VERSION "12.2.7"

NS_ :

BS_:

BU_: BMS_Tester EDS_F EDS_R EPS2 FCAM_PT GS IDB_PT POD RCU_PT VCU_PT XGW_PT

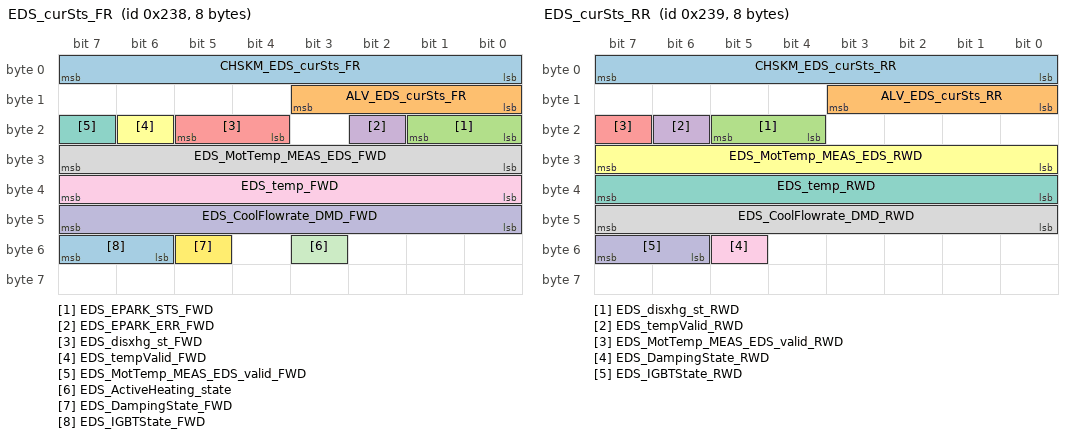
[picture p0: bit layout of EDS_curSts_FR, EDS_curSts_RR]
BO_ 568 EDS_curSts_FR: 8 EDS_F
 SG_ CHSKM_EDS_curSts_FR : 7|8@0+ (1,0) [0|255] ""  IDB_PT,VCU_PT
 SG_ ALV_EDS_curSts_FR : 11|4@0+ (1,0) [0|14] ""  IDB_PT,VCU_PT
 SG_ EDS_EPARK_STS_FWD : 17|2@0+ (1,0) [0|3] ""  VCU_PT
 SG_ EDS_EPARK_ERR_FWD : 18|1@0+ (1,0) [0|1] ""  VCU_PT
 SG_ EDS_disxhg_st_FWD : 21|2@0+ (1,0) [0|3] ""  VCU_PT
 SG_ EDS_tempValid_FWD : 22|1@0+ (1,0) [0|1] ""  VCU_PT
 SG_ EDS_MotTemp_MEAS_EDS_valid_FWD : 23|1@0+ (1,0) [0|1] ""  VCU_PT
 SG_ EDS_MotTemp_MEAS_EDS_FWD : 31|8@0+ (1,-40) [-40|215] "°C"  VCU_PT
 SG_ EDS_temp_FWD : 39|8@0+ (1,-40) [-40|215] "°C"  VCU_PT
 SG_ EDS_CoolFlowrate_DMD_FWD : 47|8@0+ (0.1,0) [0|25.4] "l/min"  IDB_PT,VCU_PT
 SG_ EDS_ActiveHeating_state : 51|1@0+ (1,0) [0|1] ""  VCU_PT
 SG_ EDS_DampingState_FWD : 53|1@0+ (1,0) [0|1] ""  IDB_PT,VCU_PT
 SG_ EDS_IGBTState_FWD : 55|2@0+ (1,0) [0|3] ""  IDB_PT,VCU_PT

BO_ 569 EDS_curSts_RR: 8 EDS_R
 SG_ CHSKM_EDS_curSts_RR : 7|8@0+ (1,0) [0|255] ""  IDB_PT,VCU_PT
 SG_ ALV_EDS_curSts_RR : 11|4@0+ (1,0) [0|14] ""  IDB_PT,VCU_PT
 SG_ EDS_disxhg_st_RWD : 21|2@0+ (1,0) [0|3] ""  VCU_PT
 SG_ EDS_tempValid_RWD : 22|1@0+ (1,0) [0|1] ""  VCU_PT
 SG_ EDS_MotTemp_MEAS_EDS_valid_RWD : 23|1@0+ (1,0) [0|1] ""  VCU_PT
 SG_ EDS_MotTemp_MEAS_EDS_RWD : 31|8@0+ (1,-40) [-40|215] "°C"  VCU_PT
 SG_ EDS_temp_RWD : 39|8@0+ (1,-40) [-40|215] "°C"  VCU_PT
 SG_ EDS_CoolFlowrate_DMD_RWD : 47|8@0+ (0.1,0) [0|25.4] "l/min"  IDB_PT,VCU_PT
 SG_ EDS_DampingState_RWD : 53|1@0+ (1,0) [0|1] ""  IDB_PT,VCU_PT
 SG_ EDS_IGBTState_RWD : 55|2@0+ (1,0) [0|3] ""  IDB_PT,VCU_PT

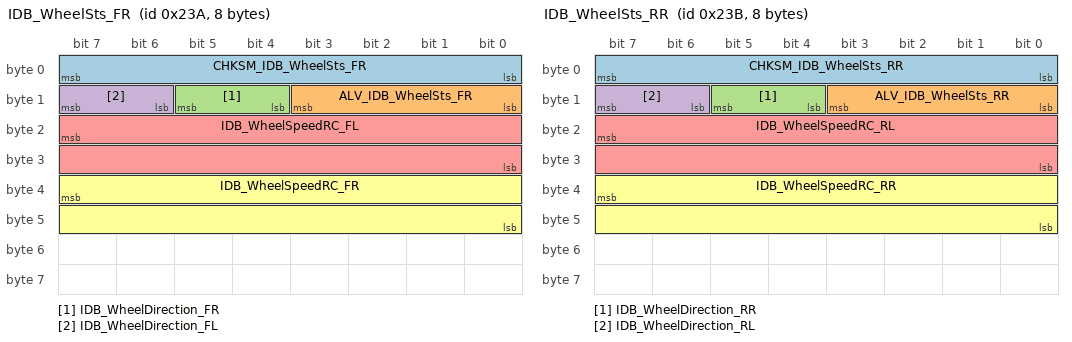
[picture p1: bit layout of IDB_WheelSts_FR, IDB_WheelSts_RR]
BO_ 570 IDB_WheelSts_FR: 8 IDB_PT
 SG_ CHKSM_IDB_WheelSts_FR : 7|8@0+ (1,0) [0|255] ""  FCAM_PT,RCU_PT
 SG_ ALV_IDB_WheelSts_FR : 11|4@0+ (1,0) [0|14] ""  FCAM_PT,RCU_PT
 SG_ IDB_WheelDirection_FR : 13|2@0+ (1,0) [0|3] ""  FCAM_PT,RCU_PT
 SG_ IDB_WheelDirection_FL : 15|2@0+ (1,0) [0|3] ""  FCAM_PT,RCU_PT
 SG_ IDB_WheelSpeedRC_FL : 23|16@0+ (1,0) [0|65534] ""  FCAM_PT,RCU_PT
 SG_ IDB_WheelSpeedRC_FR : 39|16@0+ (1,0) [0|65534] ""  FCAM_PT,RCU_PT

BO_ 571 IDB_WheelSts_RR: 8 IDB_PT
 SG_ CHKSM_IDB_WheelSts_RR : 7|8@0+ (1,0) [0|255] ""  FCAM_PT,RCU_PT
 SG_ ALV_IDB_WheelSts_RR : 11|4@0+ (1,0) [0|14] ""  FCAM_PT,RCU_PT
 SG_ IDB_WheelDirection_RR : 13|2@0+ (1,0) [0|3] ""  FCAM_PT,RCU_PT
 SG_ IDB_WheelDirection_RL : 15|2@0+ (1,0) [0|3] ""  FCAM_PT,RCU_PT
 SG_ IDB_WheelSpeedRC_RL : 23|16@0+ (1,0) [0|65534] ""  FCAM_PT,RCU_PT
 SG_ IDB_WheelSpeedRC_RR : 39|16@0+ (1,0) [0|65534] ""  FCAM_PT,RCU_PT

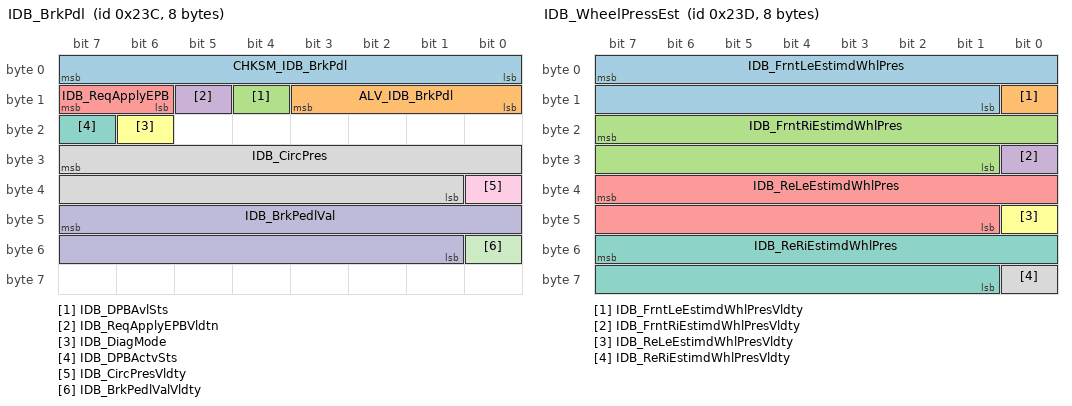
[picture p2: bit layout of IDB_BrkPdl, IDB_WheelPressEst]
BO_ 572 IDB_BrkPdl: 8 IDB_PT
 SG_ CHKSM_IDB_BrkPdl : 7|8@0+ (1,0) [0|255] ""  FCAM_PT,RCU_PT
 SG_ ALV_IDB_BrkPdl : 11|4@0+ (1,0) [0|14] ""  FCAM_PT,RCU_PT
 SG_ IDB_DPBAvlSts : 12|1@0+ (1,0) [0|1] ""  RCU_PT
 SG_ IDB_ReqApplyEPBVldtn : 13|1@0+ (1,0) [0|1] ""  RCU_PT
 SG_ IDB_ReqApplyEPB : 15|2@0+ (1,0) [0|3] ""  RCU_PT
 SG_ IDB_DiagMode : 22|1@0+ (1,0) [0|1] ""  RCU_PT
 SG_ IDB_DPBActvSts : 23|1@0+ (1,0) [0|1] ""  RCU_PT
 SG_ IDB_CircPres : 31|15@0+ (0.01,0) [0|327.67] "bar"  RCU_PT
 SG_ IDB_CircPresVldty : 32|1@0+ (1,0) [0|1] ""  RCU_PT
 SG_ IDB_BrkPedlVal : 47|15@0+ (0.1,0) [0|3276.7] "mm"  FCAM_PT,RCU_PT
 SG_ IDB_BrkPedlValVldty : 48|1@0+ (1,0) [0|1] ""  FCAM_PT,RCU_PT

BO_ 573 IDB_WheelPressEst: 8 IDB_PT
 SG_ IDB_FrntLeEstimdWhlPres : 7|15@0+ (1,0) [0|327.67] "bar"  RCU_PT
 SG_ IDB_FrntLeEstimdWhlPresVldty : 8|1@0+ (1,0) [0|1] ""  RCU_PT
 SG_ IDB_FrntRiEstimdWhlPres : 23|15@0+ (1,0) [0|327.67] "bar"  RCU_PT
 SG_ IDB_FrntRiEstimdWhlPresVldty : 24|1@0+ (1,0) [0|1] ""  RCU_PT
 SG_ IDB_ReLeEstimdWhlPres : 39|15@0+ (1,0) [0|327.67] "bar"  RCU_PT
 SG_ IDB_ReLeEstimdWhlPresVldty : 40|1@0+ (1,0) [0|1] ""  RCU_PT
 SG_ IDB_ReRiEstimdWhlPres : 55|15@0+ (1,0) [0|327.67] "bar"  RCU_PT
 SG_ IDB_ReRiEstimdWhlPresVldty : 56|1@0+ (1,0) [0|1] ""  RCU_PT

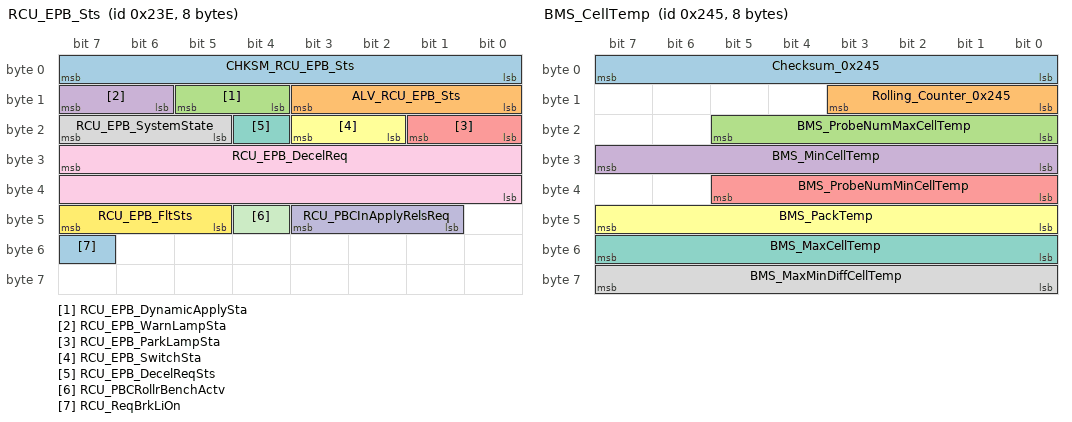
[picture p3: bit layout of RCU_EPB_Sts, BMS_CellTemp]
BO_ 574 RCU_EPB_Sts: 8 RCU_PT
 SG_ CHKSM_RCU_EPB_Sts : 7|8@0+ (1,0) [0|255] ""  FCAM_PT,IDB_PT,VCU_PT
 SG_ ALV_RCU_EPB_Sts : 11|4@0+ (1,0) [0|14] ""  FCAM_PT,IDB_PT,VCU_PT
 SG_ RCU_EPB_DynamicApplySta : 13|2@0+ (1,0) [0|3] ""  IDB_PT
 SG_ RCU_EPB_WarnLampSta : 15|2@0+ (1,0) [0|3] ""  IDB_PT
 SG_ RCU_EPB_ParkLampSta : 17|2@0+ (1,0) [0|3] ""  IDB_PT
 SG_ RCU_EPB_SwitchSta : 19|2@0+ (1,0) [0|3] ""  IDB_PT
 SG_ RCU_EPB_DecelReqSts : 20|1@0+ (1,0) [0|1] ""  IDB_PT
 SG_ RCU_EPB_SystemState : 23|3@0+ (1,0) [0|7] ""  FCAM_PT,IDB_PT
 SG_ RCU_EPB_DecelReq : 31|16@0+ (0.001,0) [0|65.535] "g"  IDB_PT
 SG_ RCU_PBCInApplyRelsReq : 43|3@0+ (1,0) [0|7] ""  IDB_PT
 SG_ RCU_PBCRollrBenchActv : 44|1@0+ (1,0) [0|1] ""  IDB_PT
 SG_ RCU_EPB_FltSts : 47|3@0+ (1,0) [0|5] ""  FCAM_PT,IDB_PT,VCU_PT
 SG_ RCU_ReqBrkLiOn : 55|1@0+ (1,0) [0|1] ""  IDB_PT

BO_ 581 BMS_CellTemp: 8 XGW_PT
 SG_ Checksum_0x245 : 7|8@0+ (1,0) [0|255] ""  POD
 SG_ Rolling_Counter_0x245 : 11|4@0+ (1,0) [0|14] ""  POD
 SG_ BMS_ProbeNumMaxCellTemp : 21|6@0+ (1,0) [0|63] ""  POD
 SG_ BMS_MinCellTemp : 31|8@0+ (1,-40) [-40|215] "°C"  POD
 SG_ BMS_ProbeNumMinCellTemp : 37|6@0+ (1,0) [0|63] ""  POD
 SG_ BMS_PackTemp : 47|8@0+ (1,-40) [-40|215] "°C"  POD
 SG_ BMS_MaxCellTemp : 55|8@0+ (1,-40) [-40|215] "°C"  POD
 SG_ BMS_MaxMinDiffCellTemp : 63|8@0+ (1,-40) [-40|215] "°C"  POD

BO_ 585 BMS_CoolntInletOutletTmp: 8 XGW_PT
 SG_ CHSKM_BMS_CoolntInletOutletTmp : 7|8@0+ (1,0) [0|255] ""  POD,VCU_PT
 SG_ ALV_BMS_CoolntInletOutletTmp : 11|4@0+ (1,0) [0|14] ""  POD,VCU_PT
 SG_ BMS_CoolantInletTemp : 23|8@0+ (1,-40) [-40|215] "°C"  POD,VCU_PT
 SG_ BMS_CoolantOutletTemp : 31|8@0+ (1,-40) [-40|215] "°C"  POD,VCU_PT

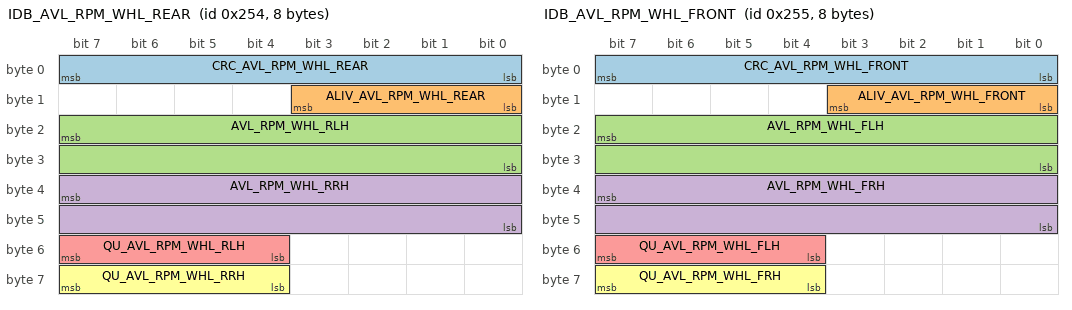
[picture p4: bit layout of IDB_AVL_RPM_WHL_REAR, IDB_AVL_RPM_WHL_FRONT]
BO_ 596 IDB_AVL_RPM_WHL_REAR: 8 IDB_PT
 SG_ CRC_AVL_RPM_WHL_REAR : 7|8@0+ (1,0) [0|255] ""  EPS2
 SG_ ALIV_AVL_RPM_WHL_REAR : 11|4@0+ (1,0) [0|14] ""  EPS2
 SG_ AVL_RPM_WHL_RLH : 23|16@0+ (0.0156,-511.9844) [-400|400] "rad/s"  EPS2
 SG_ AVL_RPM_WHL_RRH : 39|16@0+ (0.0156,-511.9844) [-400|400] "rad/s"  EPS2
 SG_ QU_AVL_RPM_WHL_RLH : 55|4@0+ (1,0) [0|15] "Bit"  EPS2
 SG_ QU_AVL_RPM_WHL_RRH : 63|4@0+ (1,0) [0|15] "Bit"  EPS2

BO_ 597 IDB_AVL_RPM_WHL_FRONT: 8 IDB_PT
 SG_ CRC_AVL_RPM_WHL_FRONT : 7|8@0+ (1,0) [0|255] ""  EPS2
 SG_ ALIV_AVL_RPM_WHL_FRONT : 11|4@0+ (1,0) [0|14] ""  EPS2
 SG_ AVL_RPM_WHL_FLH : 23|16@0+ (0.0156,-511.9844) [-400|400] "rad/s"  EPS2
 SG_ AVL_RPM_WHL_FRH : 39|16@0+ (0.0156,-511.9844) [-400|400] "rad/s"  EPS2
 SG_ QU_AVL_RPM_WHL_FLH : 55|4@0+ (1,0) [0|15] "Bit"  EPS2
 SG_ QU_AVL_RPM_WHL_FRH : 63|4@0+ (1,0) [0|15] "Bit"  EPS2

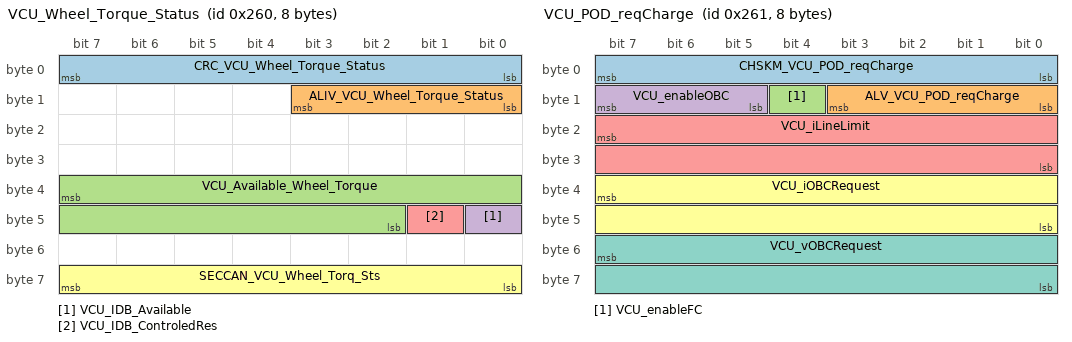
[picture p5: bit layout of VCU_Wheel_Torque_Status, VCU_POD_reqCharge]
BO_ 608 VCU_Wheel_Torque_Status: 8 VCU_PT
 SG_ CRC_VCU_Wheel_Torque_Status : 7|8@0+ (1,0) [0|255] ""  IDB_PT
 SG_ ALIV_VCU_Wheel_Torque_Status : 11|4@0+ (1,0) [0|14] ""  IDB_PT
 SG_ VCU_Available_Wheel_Torque : 39|14@0- (1,0) [-8000|8000] "Nm"  IDB_PT
 SG_ VCU_IDB_Available : 40|1@0+ (1,0) [0|1] ""  IDB_PT
 SG_ VCU_IDB_ControledRes : 41|1@0+ (1,0) [0|1] ""  IDB_PT
 SG_ SECCAN_VCU_Wheel_Torq_Sts : 63|8@0+ (1,0) [0|255] ""  IDB_PT

BO_ 609 VCU_POD_reqCharge: 8 VCU_PT
 SG_ CHSKM_VCU_POD_reqCharge : 7|8@0+ (1,0) [0|255] ""  POD
 SG_ ALV_VCU_POD_reqCharge : 11|4@0+ (1,0) [0|14] ""  POD
 SG_ VCU_enableFC : 12|1@0+ (1,0) [0|1] ""  POD
 SG_ VCU_enableOBC : 15|3@0+ (1,0) [0|7] ""  POD
 SG_ VCU_iLineLimit : 23|16@0+ (0.0625,0) [0|48] "A"  POD
 SG_ VCU_iOBCRequest : 39|16@0+ (0.0625,0) [0|48] "A"  POD
 SG_ VCU_vOBCRequest : 55|16@0+ (0.0625,0) [240|470] "V"  POD

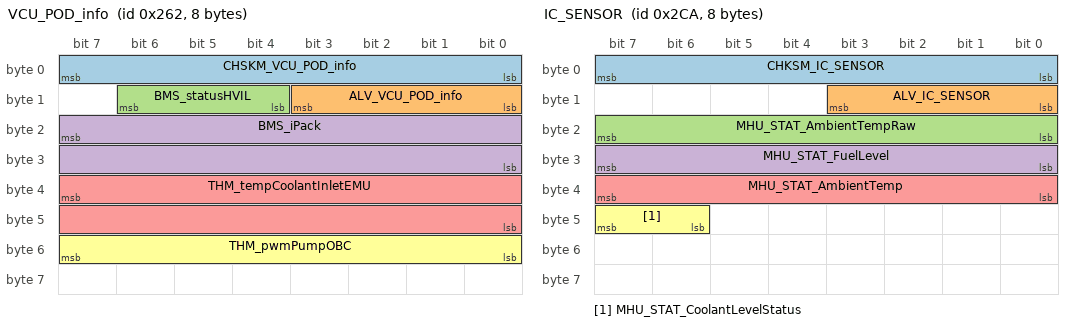
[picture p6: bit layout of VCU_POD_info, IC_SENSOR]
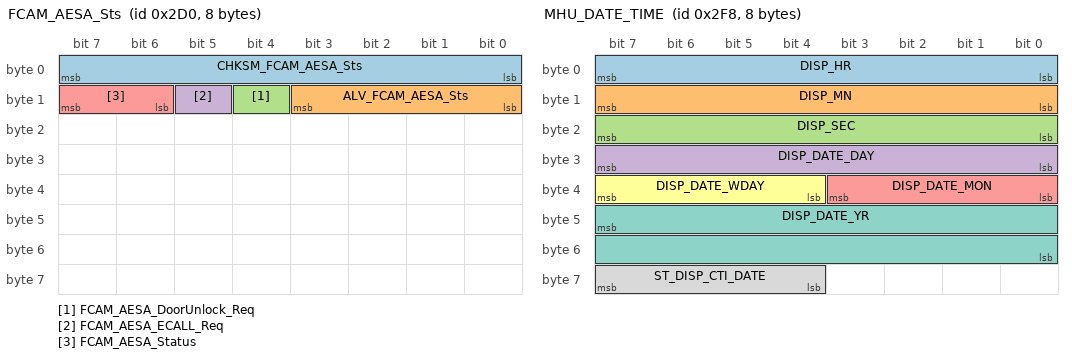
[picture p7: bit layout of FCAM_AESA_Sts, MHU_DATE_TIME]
BO_ 610 VCU_POD_info: 8 VCU_PT
 SG_ CHSKM_VCU_POD_info : 7|8@0+ (1,0) [0|255] ""  POD
 SG_ ALV_VCU_POD_info : 11|4@0+ (1,0) [0|14] ""  POD
 SG_ BMS_statusHVIL : 14|3@0+ (1,0) [0|1] ""  POD
 SG_ BMS_iPack : 23|16@0- (0.125,0) [-1023|1023] "A"  POD
 SG_ THM_tempCoolantInletEMU : 39|16@0+ (1,-40) [-30|98] "°C"  POD
 SG_ THM_pwmPumpOBC : 55|8@0+ (1,0) [0|100] "%"  POD

BO_ 680 EDS_Power_FR: 8 EDS_F
 SG_ CHSKM_EDS_Power_FR : 7|8@0+ (1,0) [0|255] ""  IDB_PT,VCU_PT
 SG_ ALV_EDS_Power_FR : 11|4@0+ (1,0) [0|14] ""  IDB_PT,VCU_PT
 SG_ EDS_MotorSerialNum_FWD : 15|1@0+ (1,0) [0|1] ""  IDB_PT,VCU_PT
 SG_ EDS_MaxTrq_FWD : 23|16@0+ (1,-2000) [-2000|2000] "Nm"  IDB_PT,VCU_PT
 SG_ EDS_MinTrq_FWD : 39|16@0+ (1,-2000) [-2000|2000] "Nm"  IDB_PT,VCU_PT

BO_ 681 EDS_Power_RR: 8 EDS_R
 SG_ CHSKM_EDS_R_Power_RR : 7|8@0+ (1,0) [0|255] ""  IDB_PT,VCU_PT
 SG_ ALV_EDS_R_Power_RR : 11|4@0+ (1,0) [0|14] ""  IDB_PT,VCU_PT
 SG_ EDS_MotorSerialNum_RWD : 15|1@0+ (1,0) [0|1] ""  IDB_PT,VCU_PT
 SG_ EDS_MaxTrq_RWD : 23|16@0+ (1,-2000) [-2000|2000] "Nm"  IDB_PT,VCU_PT
 SG_ EDS_MinTrq_RWD : 39|16@0+ (1,-2000) [-2000|2000] "Nm"  IDB_PT,VCU_PT

BO_ 714 IC_SENSOR: 8 XGW_PT
 SG_ CHKSM_IC_SENSOR : 7|8@0+ (1,0) [0|255] ""  EDS_F,EDS_R,EPS2,IDB_PT,POD,RCU_PT,VCU_PT
 SG_ ALV_IC_SENSOR : 11|4@0+ (1,0) [0|14] ""  EDS_F,EDS_R,EPS2,IDB_PT,POD,RCU_PT,VCU_PT
 SG_ MHU_STAT_AmbientTempRaw : 23|8@0+ (0.5,-40) [-40|85] "°C"  EDS_F,EDS_R,EPS2,IDB_PT,POD,RCU_PT,VCU_PT
 SG_ MHU_STAT_FuelLevel : 31|8@0+ (1,0) [0|100] "l"  EDS_F,EDS_R,EPS2,IDB_PT,POD,RCU_PT,VCU_PT
 SG_ MHU_STAT_AmbientTemp : 39|8@0+ (0.5,-40) [-40|85] "Degree C"  EDS_F,EDS_R,EPS2,IDB_PT,POD,RCU_PT,VCU_PT
 SG_ MHU_STAT_CoolantLevelStatus : 47|2@0+ (1,0) [0|3] "-"  EDS_F,EDS_R,EPS2,IDB_PT,POD,RCU_PT,VCU_PT

 BO_ 720 FCAM_AESA_Sts: 8 FCAM_PT
 SG_ CHKSM_FCAM_AESA_Sts : 7|8@0+ (1,0) [0|255] ""  VCU_PT
 SG_ ALV_FCAM_AESA_Sts : 11|4@0+ (1,0) [0|14] ""  VCU_PT
 SG_ FCAM_AESA_DoorUnlock_Req : 12|1@0+ (1,0) [0|1] ""  Vector__XXX
 SG_ FCAM_AESA_ECALL_Req : 13|1@0+ (1,0) [0|1] ""  Vector__XXX
 SG_ FCAM_AESA_Status : 15|2@0+ (1,0) [0|3] ""  VCU_PT

BO_ 760 MHU_DATE_TIME: 8 XGW_PT
 SG_ DISP_HR : 7|8@0+ (1,0) [0|23] "h"  EDS_F,EDS_R,EPS2,GS,IDB_PT,POD,RCU_PT,VCU_PT
 SG_ DISP_MN : 15|8@0+ (1,0) [0|59] "min"  EDS_F,EDS_R,EPS2,GS,IDB_PT,POD,RCU_PT,VCU_PT
 SG_ DISP_SEC : 23|8@0+ (1,0) [0|59] "s"  EDS_F,EDS_R,EPS2,GS,IDB_PT,POD,RCU_PT,VCU_PT
 SG_ DISP_DATE_DAY : 31|8@0+ (1,0) [1|31] "Day"  EDS_F,EDS_R,EPS2,GS,IDB_PT,POD,RCU_PT,VCU_PT
 SG_ DISP_DATE_MON : 35|4@0+ (1,0) [1|12] "Month"  EDS_F,EDS_R,EPS2,GS,IDB_PT,POD,RCU_PT,VCU_PT
 SG_ DISP_DATE_WDAY : 39|4@0+ (1,0) [0|15] ""  EDS_F,EDS_R,EPS2,GS,IDB_PT,POD,RCU_PT,VCU_PT
 SG_ DISP_DATE_YR : 47|16@0+ (1,0) [1|65534] "Year"  EDS_F,EDS_R,EPS2,GS,IDB_PT,POD,RCU_PT,VCU_PT
 SG_ ST_DISP_CTI_DATE : 63|4@0+ (1,0) [0|15] ""  EDS_F,EDS_R,EPS2,GS,IDB_PT,POD,RCU_PT,VCU_PT

BO_ 761 MHU_DATE_TIME_UTC: 8 XGW_PT
 SG_ DISP_HR_UTC : 7|8@0+ (1,0) [0|23] "h"  VCU_PT
 SG_ DISP_MN_UTC : 15|8@0+ (1,0) [0|59] "min"  VCU_PT
 SG_ DISP_SEC_UTC : 23|8@0+ (1,0) [0|59] "s"  VCU_PT
 SG_ DISP_DATE_DAY_UTC : 31|8@0+ (1,0) [1|31] "Day"  VCU_PT
 SG_ DISP_DATE_MON_UTC : 35|4@0+ (1,0) [1|12] "Month"  VCU_PT
 SG_ DISP_DATE_YR_UTC : 47|16@0+ (1,0) [1|65534] "Year"  VCU_PT

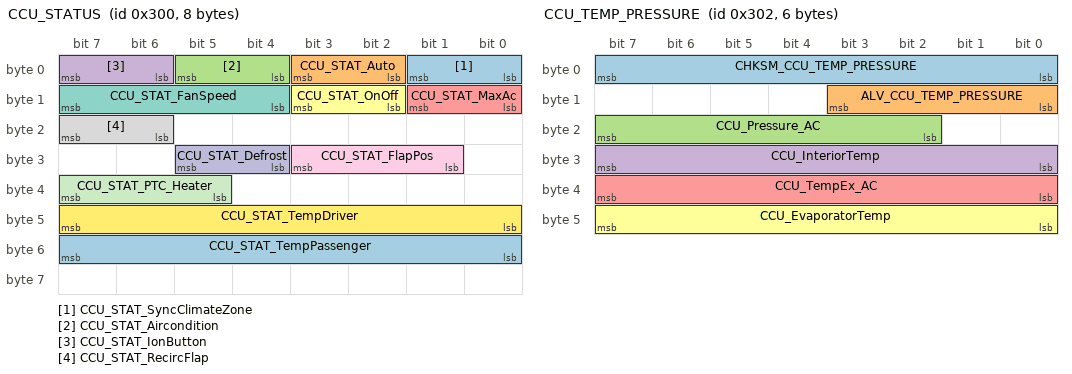
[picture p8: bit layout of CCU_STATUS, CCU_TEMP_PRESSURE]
BO_ 768 CCU_STATUS: 8 XGW_PT
 SG_ CCU_STAT_SyncClimateZone : 1|2@0+ (1,0) [0|3] "" Vector__XXX
 SG_ CCU_STAT_Auto : 3|2@0+ (1,0) [0|3] "-" Vector__XXX
 SG_ CCU_STAT_Aircondition : 5|2@0+ (1,0) [0|3] "" Vector__XXX
 SG_ CCU_STAT_IonButton : 7|2@0+ (1,0) [0|3] "" Vector__XXX
 SG_ CCU_STAT_MaxAc : 9|2@0+ (1,0) [0|3] "" Vector__XXX
 SG_ CCU_STAT_OnOff : 11|2@0+ (1,0) [0|3] "Bit" Vector__XXX
 SG_ CCU_STAT_FanSpeed : 15|4@0+ (1,0) [0|15] "" Vector__XXX
 SG_ CCU_STAT_RecircFlap : 23|2@0+ (1,0) [0|3] "" Vector__XXX
 SG_ CCU_STAT_FlapPos : 27|3@0+ (1,0) [0|7] "" Vector__XXX
 SG_ CCU_STAT_Defrost : 29|2@0+ (1,0) [0|3] "-"  VCU_PT
 SG_ CCU_STAT_PTC_Heater : 39|3@0+ (1,0) [0|7] "-" Vector__XXX
 SG_ CCU_STAT_TempDriver : 47|8@0+ (0.5,0) [16|32] "Degree C" Vector__XXX
 SG_ CCU_STAT_TempPassenger : 55|8@0+ (0.5,0) [16|32] "Degree C" Vector__XXX

BO_ 770 CCU_TEMP_PRESSURE: 6 XGW_PT
 SG_ CHKSM_CCU_TEMP_PRESSURE : 7|8@0+ (1,0) [0|255] ""  EDS_F,EDS_R,EPS2,GS,IDB_PT,POD,RCU_PT,VCU_PT
 SG_ ALV_CCU_TEMP_PRESSURE : 11|4@0+ (1,0) [0|14] ""  EDS_F,EDS_R,EPS2,GS,IDB_PT,POD,RCU_PT,VCU_PT
 SG_ CCU_Pressure_AC : 23|6@0+ (1,0) [0|62] "bar"  EDS_F,EDS_R,EPS2,GS,IDB_PT,POD,RCU_PT,VCU_PT
 SG_ CCU_InteriorTemp : 31|8@0+ (0.5,-40) [-40|85] "Degree C"  EDS_F,EDS_R,EPS2,GS,IDB_PT,POD,RCU_PT,VCU_PT
 SG_ CCU_TempEx_AC : 39|8@0+ (0.5,-40) [-40|85] "Degree C"  EDS_F,EDS_R,EPS2,GS,IDB_PT,POD,RCU_PT,VCU_PT
 SG_ CCU_EvaporatorTemp : 47|8@0+ (0.5,-40) [-40|85] "Degree C"  EDS_F,EDS_R,EPS2,GS,IDB_PT,POD,RCU_PT,VCU_PT

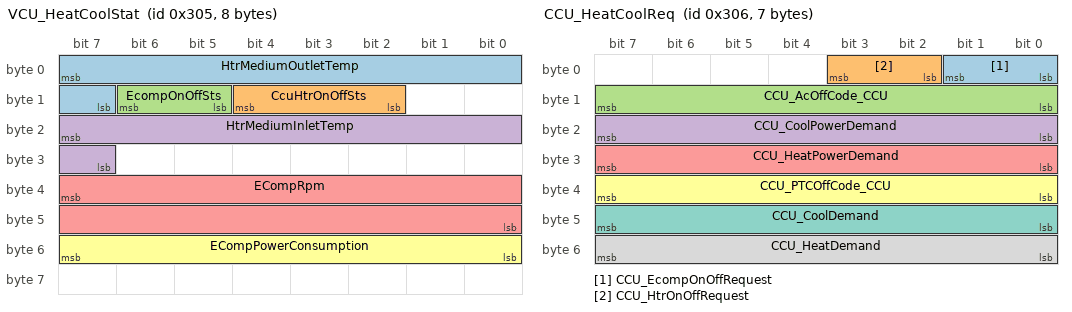
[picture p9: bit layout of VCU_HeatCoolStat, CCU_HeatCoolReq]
BO_ 773 VCU_HeatCoolStat: 8 VCU_PT
 SG_ HtrMediumOutletTemp : 7|9@0+ (0.5,-40) [-40|200] "°C"  XGW_PT
 SG_ CcuHtrOnOffSts : 12|3@0+ (1,0) [0|7] ""  XGW_PT
 SG_ EcompOnOffSts : 14|2@0+ (1,0) [0|3] ""  XGW_PT
 SG_ HtrMediumInletTemp : 23|9@0+ (0.5,-40) [-40|200] "Degree C"  XGW_PT
 SG_ ECompRpm : 39|16@0+ (1,0) [0|12000] "1/min"  XGW_PT
 SG_ ECompPowerConsumption : 55|8@0+ (0.1,0) [0|12] "kW"  XGW_PT

BO_ 774 CCU_HeatCoolReq: 7 XGW_PT
 SG_ CCU_EcompOnOffRequest : 1|2@0+ (1,0) [0|3] ""  VCU_PT
 SG_ CCU_HtrOnOffRequest : 3|2@0+ (1,0) [0|3] ""  VCU_PT
 SG_ CCU_AcOffCode_CCU : 15|8@0+ (1,0) [0|255] ""  VCU_PT
 SG_ CCU_CoolPowerDemand : 23|8@0+ (0.1,0) [0|10] "kW"  VCU_PT
 SG_ CCU_HeatPowerDemand : 31|8@0+ (0.1,0) [0|10] "kW"  VCU_PT
 SG_ CCU_PTCOffCode_CCU : 39|8@0+ (1,0) [0|255] ""  VCU_PT
 SG_ CCU_CoolDemand : 47|8@0+ (0.5,0) [0|100] "%"  VCU_PT
 SG_ CCU_HeatDemand : 55|8@0+ (0.5,0) [0|100] "%"  VCU_PT

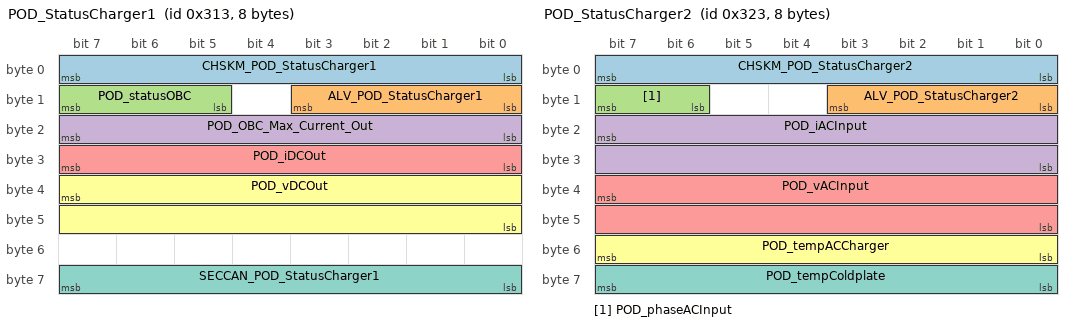
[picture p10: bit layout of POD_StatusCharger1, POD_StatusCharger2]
BO_ 787 POD_StatusCharger1: 8 POD
 SG_ CHSKM_POD_StatusCharger1 : 7|8@0+ (1,0) [0|255] ""  VCU_PT,XGW_PT
 SG_ ALV_POD_StatusCharger1 : 11|4@0+ (1,0) [0|14] ""  VCU_PT,XGW_PT
 SG_ POD_statusOBC : 15|3@0+ (1,0) [0|7] ""  VCU_PT,XGW_PT
 SG_ POD_OBC_Max_Current_Out : 23|8@0+ (1,0) [0|64] "A"  VCU_PT,XGW_PT
 SG_ POD_iDCOut : 31|8@0+ (1,0) [0|64] "A"  VCU_PT,XGW_PT
 SG_ POD_vDCOut : 39|16@0+ (0.0625,0) [0|512] "V"  VCU_PT,XGW_PT
 SG_ SECCAN_POD_StatusCharger1 : 63|8@0+ (1,0) [0|255] ""  VCU_PT,XGW_PT

BO_ 803 POD_StatusCharger2: 8 POD
 SG_ CHSKM_POD_StatusCharger2 : 7|8@0+ (1,0) [0|255] ""  VCU_PT,XGW_PT
 SG_ ALV_POD_StatusCharger2 : 11|4@0+ (1,0) [0|14] ""  VCU_PT,XGW_PT
 SG_ POD_phaseACInput : 15|2@0+ (1,0) [0|3] ""  VCU_PT,XGW_PT
 SG_ POD_iACInput : 23|16@0+ (0.0625,0) [0|60] "A"  VCU_PT,XGW_PT
 SG_ POD_vACInput : 39|16@0+ (0.0625,0) [0|512] "V"  VCU_PT,XGW_PT
 SG_ POD_tempACCharger : 55|8@0+ (1,-40) [-30|150] "°C"  VCU_PT,XGW_PT
 SG_ POD_tempColdplate : 63|8@0+ (1,-40) [-40|130] "°C"  VCU_PT,XGW_PT

BO_ 806 POD_StatusDCDC1: 8 POD
 SG_ CHSKM_POD_StatusDCDC1 : 7|8@0+ (1,0) [0|255] ""  VCU_PT,XGW_PT
 SG_ ALV_POD_StatusDCDC1 : 11|4@0+ (1,0) [0|14] ""  VCU_PT,XGW_PT
 SG_ POD_statusDCDC : 14|3@0+ (1,0) [0|7] ""  VCU_PT,XGW_PT
 SG_ POD_DCDC_Max_Current_Out : 23|8@0+ (1,0) [0|250] "A"  VCU_PT,XGW_PT

BO_ 807 POD_StatusFC: 8 POD
 SG_ CHKSM_POD_StatusFC : 7|8@0+ (1,0) [0|255] "" VCU_PT,XGW_PT
 SG_ ALV_POD_StatusFC : 11|4@0+ (1,0) [0|14] "" VCU_PT,XGW_PT
 SG_ POD_vFC : 23|16@0+ (0.0625,0) [0|512] "V" VCU_PT,XGW_PT
 SG_ POD_statusFCContactors : 47|3@0+ (1,0) [0|7] "" VCU_PT,XGW_PT

BO_ 816 IC_MILEAGE: 8 XGW_PT
 SG_ MILE_KM : 7|24@0+ (1,0) [0|999999] "km"  EDS_F,EDS_R,EPS2,GS,IDB_PT,POD,RCU_PT,VCU_PT
 SG_ FLLV_FUTA : 31|8@0+ (1,0) [0|254] "l"  EDS_F,EDS_R,EPS2,GS,IDB_PT,POD,RCU_PT,VCU_PT
 SG_ RNG : 51|12@0+ (1,0) [0|4094] "km"  EDS_F,EDS_R,EPS2,GS,IDB_PT,POD,RCU_PT,VCU_PT
 SG_ ST_FLLV_FUTA_SPAR : 55|2@0+ (1,0) [0|3] ""  EDS_F,EDS_R,EPS2,FCAM_PT,GS,IDB_PT,POD,RCU_PT,VCU_PT

BO_ 838 POD_StatusDCDC2: 8 POD
 SG_ CHSKM_POD_StatusDCDC2 : 7|8@0+ (1,0) [0|255] ""  VCU_PT,XGW_PT
 SG_ ALV_POD_StatusDCDC2 : 11|4@0+ (1,0) [0|14] ""  VCU_PT,XGW_PT
 SG_ POD_vDCInput : 23|16@0+ (0.0625,0) [0|512] "V"  VCU_PT,XGW_PT
 SG_ POD_iDCDCOutput : 39|16@0+ (0.0625,0) [0|300] "A"  VCU_PT,XGW_PT
 SG_ POD_vDCDCOutput : 55|16@0+ (0.0625,0) [0|18] "V"  VCU_PT,XGW_PT

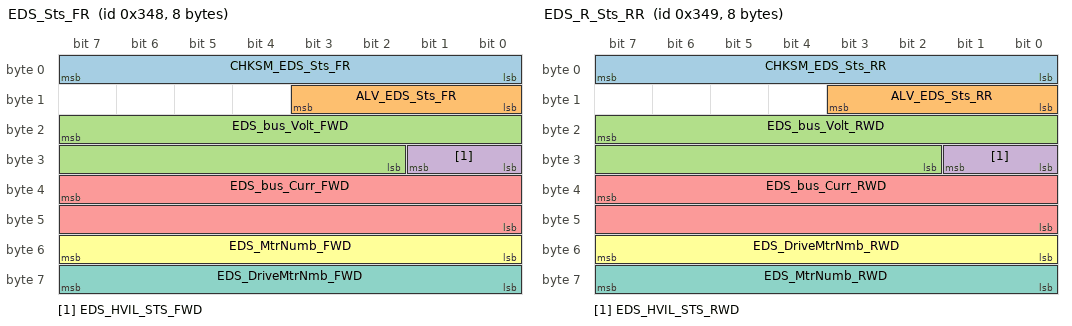
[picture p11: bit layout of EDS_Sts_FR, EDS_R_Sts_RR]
BO_ 840 EDS_Sts_FR: 8 EDS_F
 SG_ CHKSM_EDS_Sts_FR : 7|8@0+ (1,0) [0|255] ""  VCU_PT
 SG_ ALV_EDS_Sts_FR : 11|4@0+ (1,0) [0|14] ""  VCU_PT
 SG_ EDS_bus_Volt_FWD : 23|14@0+ (0.1,0) [0|1000] "V"  VCU_PT
 SG_ EDS_HVIL_STS_FWD : 25|2@0+ (1,0) [0|3] ""  VCU_PT,XGW_PT
 SG_ EDS_bus_Curr_FWD : 39|16@0+ (0.1,-1000) [-1000|1000] "A"  VCU_PT
 SG_ EDS_MtrNumb_FWD : 55|8@0+ (1,0) [0|255] ""  VCU_PT
 SG_ EDS_DriveMtrNmb_FWD : 63|8@0+ (1,0) [0|255] ""  VCU_PT

BO_ 841 EDS_R_Sts_RR: 8 EDS_R
 SG_ CHKSM_EDS_Sts_RR : 7|8@0+ (1,0) [0|255] ""  VCU_PT
 SG_ ALV_EDS_Sts_RR : 11|4@0+ (1,0) [0|14] ""  VCU_PT
 SG_ EDS_bus_Volt_RWD : 23|14@0+ (0.1,0) [0|1000] "V"  VCU_PT
 SG_ EDS_HVIL_STS_RWD : 25|2@0+ (1,0) [0|3] ""  VCU_PT,XGW_PT
 SG_ EDS_bus_Curr_RWD : 39|16@0+ (0.1,-1000) [-1000|1000] "A"  VCU_PT
 SG_ EDS_DriveMtrNmb_RWD : 55|8@0+ (1,0) [0|255] ""  VCU_PT
 SG_ EDS_MtrNumb_RWD : 63|8@0+ (1,0) [0|255] ""  VCU_PT

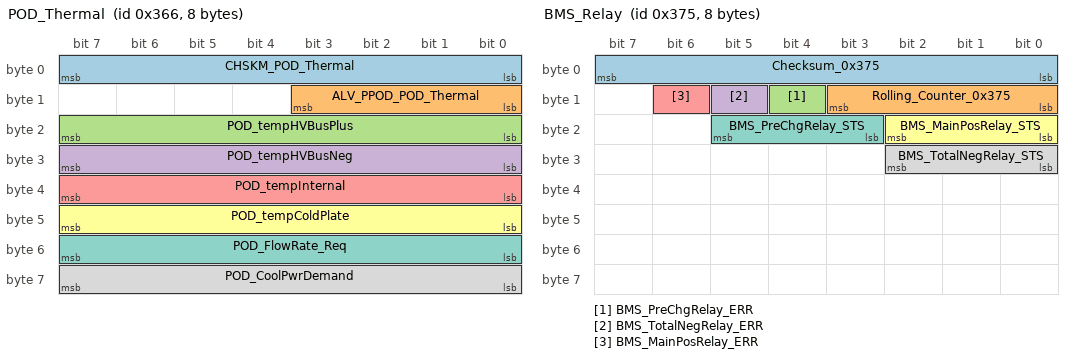
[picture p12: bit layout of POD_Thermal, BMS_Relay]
BO_ 870 POD_Thermal: 8 POD
 SG_ CHSKM_POD_Thermal : 7|8@0+ (1,0) [0|255] ""  VCU_PT
 SG_ ALV_PPOD_POD_Thermal : 11|4@0+ (1,0) [0|14] ""  VCU_PT
 SG_ POD_tempHVBusPlus : 23|8@0+ (1,-40) [-30|150] "°C"  VCU_PT
 SG_ POD_tempHVBusNeg : 31|8@0+ (1,-40) [-30|150] "°C"  VCU_PT
 SG_ POD_tempInternal : 39|8@0+ (1,-40) [-30|150] "°C"  VCU_PT
 SG_ POD_tempColdPlate : 47|8@0+ (1,-40) [-30|150] "Degree C"  VCU_PT
 SG_ POD_FlowRate_Req : 55|8@0+ (1,0) [0|50] "l/min"  VCU_PT
 SG_ POD_CoolPwrDemand : 63|8@0+ (0.1,0) [0|10] "kW"  VCU_PT

BO_ 885 BMS_Relay: 8 XGW_PT
 SG_ Checksum_0x375 : 7|8@0+ (1,0) [0|255] ""  EDS_F,EDS_R
 SG_ Rolling_Counter_0x375 : 11|4@0+ (1,0) [0|14] ""  EDS_F,EDS_R
 SG_ BMS_PreChgRelay_ERR : 12|1@0+ (1,0) [0|1] ""  EDS_F,EDS_R
 SG_ BMS_TotalNegRelay_ERR : 13|1@0+ (1,0) [0|1] ""  EDS_F,EDS_R
 SG_ BMS_MainPosRelay_ERR : 14|1@0+ (1,0) [0|1] ""  EDS_F,EDS_R
 SG_ BMS_MainPosRelay_STS : 18|3@0+ (1,0) [0|7] ""  EDS_F,EDS_R
 SG_ BMS_PreChgRelay_STS : 21|3@0+ (1,0) [0|7] ""  EDS_F,EDS_R
 SG_ BMS_TotalNegRelay_STS : 26|3@0+ (1,0) [0|7] ""  EDS_F,EDS_R

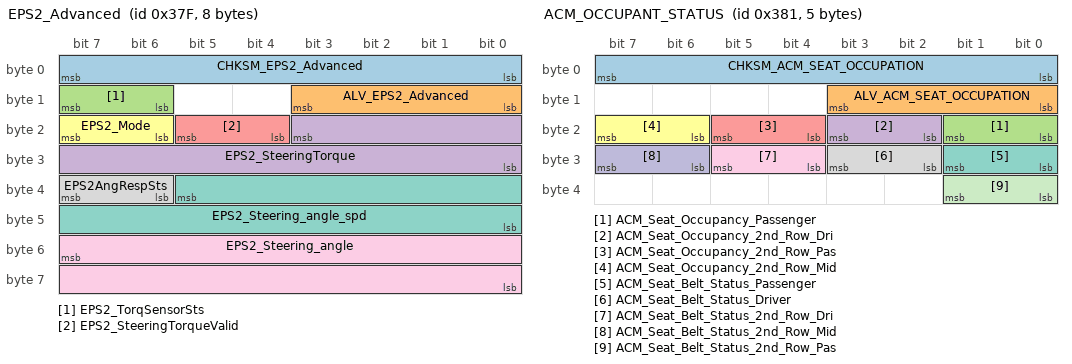
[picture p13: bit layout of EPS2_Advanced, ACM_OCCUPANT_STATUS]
BO_ 895 EPS2_Advanced: 8 EPS2
 SG_ CHKSM_EPS2_Advanced : 7|8@0+ (1,0) [0|255] ""  IDB_PT
 SG_ ALV_EPS2_Advanced : 11|4@0+ (1,0) [0|14] ""  IDB_PT
 SG_ EPS2_TorqSensorSts : 15|2@0+ (1,0) [0|1] ""  IDB_PT
 SG_ EPS2_SteeringTorque : 19|12@0+ (0.01,-10.24) [-10.24|10.23] "Nm"  IDB_PT
 SG_ EPS2_SteeringTorqueValid : 21|2@0+ (1,0) [0|1] ""  IDB_PT
 SG_ EPS2_Mode : 23|2@0+ (1,0) [0|3] ""  IDB_PT
 SG_ EPS2_Steering_angle_spd : 37|14@0+ (0.125,-1024) [-1024|1023.875] "degree/s"  IDB_PT
 SG_ EPS2AngRespSts : 39|2@0+ (1,0) [0|3] ""  IDB_PT
 SG_ EPS2_Steering_angle : 55|16@0+ (0.0238,-780) [-780|779.733] "deg"  IDB_PT

BO_ 896 BCM_VEHICLE_IDENT_NUMBER: 8 XGW_PT
 SG_ VIN_Byte1 : 7|8@0+ (1,0) [0|255] ""  EDS_F,EDS_R,EPS2,GS,IDB_PT,POD,RCU_PT,VCU_PT
 SG_ VIN_Byte2 : 15|8@0+ (1,0) [0|255] ""  EDS_F,EDS_R,EPS2,GS,IDB_PT,POD,RCU_PT,VCU_PT
 SG_ VIN_Byte3 : 23|8@0+ (1,0) [0|255] ""  EDS_F,EDS_R,EPS2,GS,IDB_PT,POD,RCU_PT,VCU_PT
 SG_ VIN_Byte4 : 31|8@0+ (1,0) [0|255] ""  EDS_F,EDS_R,EPS2,GS,IDB_PT,POD,RCU_PT,VCU_PT
 SG_ VIN_Byte5 : 39|8@0+ (1,0) [0|255] ""  EDS_F,EDS_R,EPS2,GS,IDB_PT,POD,RCU_PT,VCU_PT
 SG_ VIN_Byte6 : 47|8@0+ (1,0) [0|255] ""  EDS_F,EDS_R,EPS2,GS,IDB_PT,POD,RCU_PT,VCU_PT
 SG_ VIN_Byte7 : 55|8@0+ (1,0) [0|255] ""  EDS_F,EDS_R,EPS2,GS,IDB_PT,POD,RCU_PT,VCU_PT

BO_ 897 ACM_OCCUPANT_STATUS: 5 XGW_PT
 SG_ CHKSM_ACM_SEAT_OCCUPATION : 7|8@0+ (1,0) [0|255] ""  IDB_PT,RCU_PT
 SG_ ALV_ACM_SEAT_OCCUPATION : 11|4@0+ (1,0) [0|14] ""  IDB_PT,RCU_PT
 SG_ ACM_Seat_Occupancy_Passenger : 17|2@0+ (1,0) [0|3] ""  IDB_PT
 SG_ ACM_Seat_Occupancy_2nd_Row_Dri : 19|2@0+ (1,0) [0|3] ""  IDB_PT
 SG_ ACM_Seat_Occupancy_2nd_Row_Pas : 21|2@0+ (1,0) [0|3] "-"  IDB_PT
 SG_ ACM_Seat_Occupancy_2nd_Row_Mid : 23|2@0+ (1,0) [0|3] "-"  IDB_PT
 SG_ ACM_Seat_Belt_Status_Passenger : 25|2@0+ (1,0) [0|3] ""  IDB_PT
 SG_ ACM_Seat_Belt_Status_Driver : 27|2@0+ (1,0) [0|3] ""  IDB_PT,RCU_PT,VCU_PT
 SG_ ACM_Seat_Belt_Status_2nd_Row_Dri : 29|2@0+ (1,0) [0|3] "-"  IDB_PT
 SG_ ACM_Seat_Belt_Status_2nd_Row_Mid : 31|2@0+ (1,0) [0|3] ""  IDB_PT
 SG_ ACM_Seat_Belt_Status_2nd_Row_Pas : 33|2@0+ (1,0) [0|3] "-"  IDB_PT

BO_ 905 VCU_Sts3: 8 VCU_PT
 SG_ VCU_IMMO_Sts : 35|2@0+ (1,0) [0|3] ""  XGW_PT
 SG_ SECCAN_VCU_IMMO_Sts : 63|8@0+ (1,0) [0|255] ""  XGW_PT

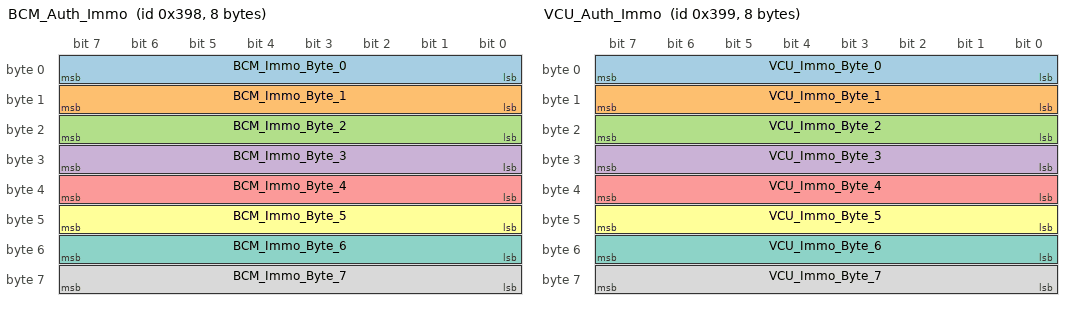
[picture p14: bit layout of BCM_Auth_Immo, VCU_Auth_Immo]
BO_ 920 BCM_Auth_Immo: 8 XGW_PT
 SG_ BCM_Immo_Byte_0 : 7|8@0+ (1,0) [0|255] ""  VCU_PT
 SG_ BCM_Immo_Byte_1 : 15|8@0+ (1,0) [0|255] ""  VCU_PT
 SG_ BCM_Immo_Byte_2 : 23|8@0+ (1,0) [0|255] ""  VCU_PT
 SG_ BCM_Immo_Byte_3 : 31|8@0+ (1,0) [0|255] ""  VCU_PT
 SG_ BCM_Immo_Byte_4 : 39|8@0+ (1,0) [0|255] ""  VCU_PT
 SG_ BCM_Immo_Byte_5 : 47|8@0+ (1,0) [0|255] ""  VCU_PT
 SG_ BCM_Immo_Byte_6 : 55|8@0+ (1,0) [0|255] ""  VCU_PT
 SG_ BCM_Immo_Byte_7 : 63|8@0+ (1,0) [0|255] ""  VCU_PT

BO_ 921 VCU_Auth_Immo: 8 VCU_PT
 SG_ VCU_Immo_Byte_0 : 7|8@0+ (1,0) [0|255] ""  XGW_PT
 SG_ VCU_Immo_Byte_1 : 15|8@0+ (1,0) [0|255] ""  XGW_PT
 SG_ VCU_Immo_Byte_2 : 23|8@0+ (1,0) [0|255] ""  XGW_PT
 SG_ VCU_Immo_Byte_3 : 31|8@0+ (1,0) [0|255] ""  XGW_PT
 SG_ VCU_Immo_Byte_4 : 39|8@0+ (1,0) [0|255] ""  XGW_PT
 SG_ VCU_Immo_Byte_5 : 47|8@0+ (1,0) [0|255] ""  XGW_PT
 SG_ VCU_Immo_Byte_6 : 55|8@0+ (1,0) [0|255] ""  XGW_PT
 SG_ VCU_Immo_Byte_7 : 63|8@0+ (1,0) [0|255] ""  XGW_PT

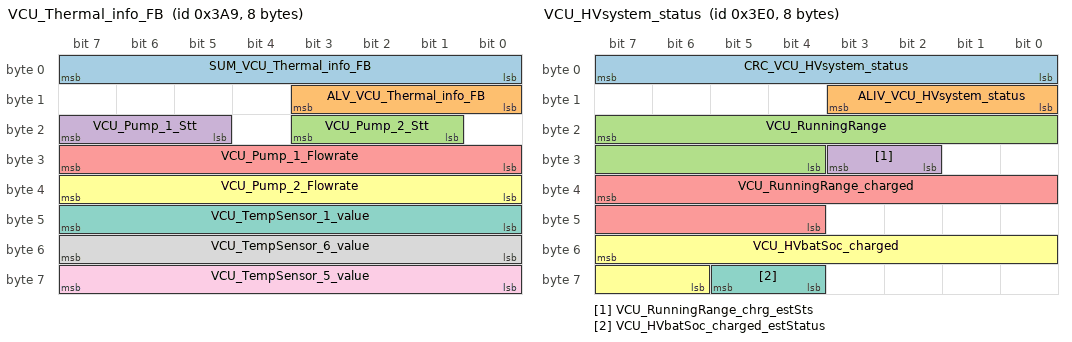
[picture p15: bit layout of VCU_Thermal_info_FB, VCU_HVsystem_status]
BO_ 937 VCU_Thermal_info_FB: 8 VCU_PT
 SG_ SUM_VCU_Thermal_info_FB : 7|8@0+ (1,0) [0|255] ""  EDS_F,EDS_R,POD
 SG_ ALV_VCU_Thermal_info_FB : 11|4@0+ (1,0) [0|14] ""  EDS_F,EDS_R,POD
 SG_ VCU_Pump_2_Stt : 19|3@0+ (1,0) [0|3] ""  POD
 SG_ VCU_Pump_1_Stt : 23|3@0+ (1,0) [0|3] ""  POD
 SG_ VCU_Pump_1_Flowrate : 31|8@0+ (0.1,0) [0|25.4] "l/min"  EDS_F,EDS_R,POD
 SG_ VCU_Pump_2_Flowrate : 39|8@0+ (0.1,0) [0|25.4] "l/min"  POD
 SG_ VCU_TempSensor_1_value : 47|8@0+ (1,-40) [-40|215] "°C"  EDS_F,EDS_R,POD
 SG_ VCU_TempSensor_6_value : 55|8@0+ (1,-40) [-40|215] "°C"  POD
 SG_ VCU_TempSensor_5_value : 63|8@0+ (1,-40) [-40|215] "°C"  POD

BO_ 992 VCU_HVsystem_status: 8 VCU_PT
 SG_ CRC_VCU_HVsystem_status : 7|8@0+ (1,0) [0|255] ""  XGW_PT
 SG_ ALIV_VCU_HVsystem_status : 11|4@0+ (1,0) [0|14] ""  XGW_PT
 SG_ VCU_RunningRange : 23|12@0+ (0.5,0) [0|2047] "km"  XGW_PT
 SG_ VCU_RunningRange_chrg_estSts : 27|2@0+ (1,0) [0|3] "-"  XGW_PT
 SG_ VCU_RunningRange_charged : 39|12@0+ (0.5,0) [0|2047] "km"  XGW_PT
 SG_ VCU_HVbatSoc_charged : 55|10@0+ (0.1,0) [0|100] "%"  XGW_PT
 SG_ VCU_HVbatSoc_charged_estStatus : 61|2@0+ (1,0) [0|3] "-"  XGW_PT

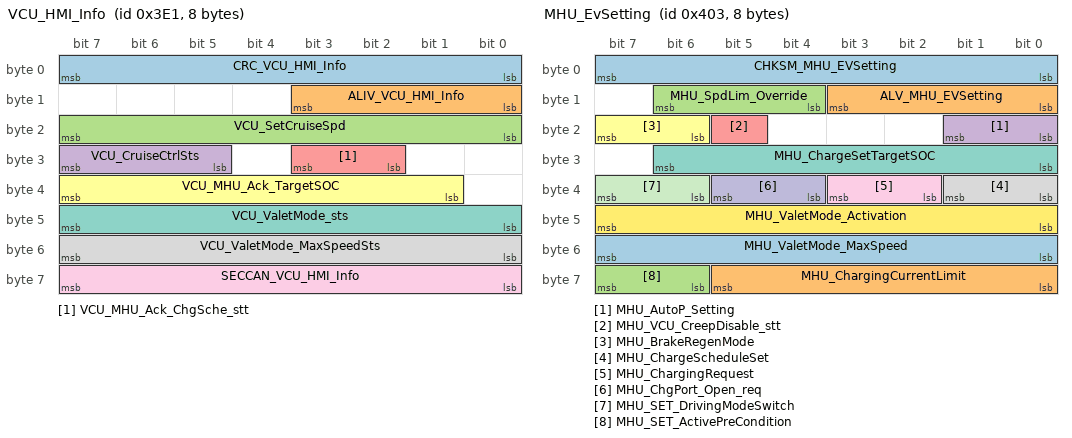
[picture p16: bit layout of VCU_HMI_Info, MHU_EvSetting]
BO_ 993 VCU_HMI_Info: 8 VCU_PT
 SG_ CRC_VCU_HMI_Info : 7|8@0+ (1,0) [0|255] ""  XGW_PT
 SG_ ALIV_VCU_HMI_Info : 11|4@0+ (1,0) [0|14] ""  XGW_PT
 SG_ VCU_SetCruiseSpd : 23|8@0+ (1,0) [0|200] "km/h"  XGW_PT
 SG_ VCU_CruiseCtrlSts : 31|3@0+ (1,0) [0|7] ""  XGW_PT
 SG_ VCU_MHU_Ack_ChgSche_stt : 27|2@0+ (1,0) [0|3] ""  XGW_PT
 SG_ VCU_MHU_Ack_TargetSOC : 39|7@0+ (1,0) [10|100] "%"  XGW_PT
 SG_ VCU_ValetMode_sts : 47|8@0+ (1,0) [0|255] ""  XGW_PT
 SG_ VCU_ValetMode_MaxSpeedSts : 55|8@0+ (1,0) [0|255] "km/h"  XGW_PT
 SG_ SECCAN_VCU_HMI_Info : 63|8@0+ (1,0) [0|255] ""  XGW_PT

BO_ 1015 MFS_Control_Button: 8 XGW_PT
 SG_ CHSKM_MFS_Control_Button : 7|8@0+ (1,0) [0|255] ""  VCU_PT
 SG_ ALV_MFS_Control_Button : 11|4@0+ (1,0) [0|14] ""  VCU_PT
 SG_ MFS_VoiceRecognitionOn_Off : 15|3@0+ (1,0) [0|4] "Bit"  VCU_PT
 SG_ MFS_ISAControl : 17|2@0+ (1,0) [0|3] "Bit"  VCU_PT
 SG_ MFS_CruiseSpeedIncrease : 20|3@0+ (1,0) [0|4] "Bit"  VCU_PT
 SG_ MFS_TelephoneCall_EndCall : 23|3@0+ (1,0) [0|4] "Bit"  VCU_PT
 SG_ MFS_LKAControl : 25|2@0+ (1,0) [0|3] "Bit"  VCU_PT
 SG_ MFS_CruiseGapIncrease : 28|3@0+ (1,0) [0|4] "Bit"  VCU_PT
 SG_ MFS_CruiseOn_Off : 31|3@0+ (1,0) [0|4] "Bit"  VCU_PT
 SG_ MFS_CruiseGapDecrease : 34|3@0+ (1,0) [0|4] "Bit"  VCU_PT
 SG_ MFS_CAN_RESControl : 36|2@0+ (1,0) [0|3] "Bit"  VCU_PT
 SG_ MFS_CruiseSpeedDecrease : 39|3@0+ (1,0) [0|4] "Bit"  VCU_PT
 SG_ MFS_SourseControl : 44|3@0+ (1,0) [0|4] "Bit"  VCU_PT
 SG_ MFS_UpControl : 47|3@0+ (1,0) [0|4] "Bit"  VCU_PT
 SG_ MFS_DownControl : 52|3@0+ (1,0) [0|4] "Bit"  VCU_PT
 SG_ MFS_LeftControl : 55|3@0+ (1,0) [0|4] "Bit"  VCU_PT
 SG_ MFS_Failure : 57|1@0+ (1,0) [0|1] "Bit"  VCU_PT
 SG_ MFS_RightControl : 60|3@0+ (1,0) [0|4] "Bit"  VCU_PT
 SG_ MFS_OK_Control : 63|3@0+ (1,0) [0|4] "Bit"  VCU_PT

BO_ 1027 MHU_EvSetting: 8 XGW_PT
 SG_ CHKSM_MHU_EVSetting : 7|8@0+ (1,0) [0|255] ""  VCU_PT
 SG_ ALV_MHU_EVSetting : 11|4@0+ (1,0) [0|14] ""  VCU_PT
 SG_ MHU_SpdLim_Override : 14|3@0+ (10,0) [0|30] "km/h"  VCU_PT
 SG_ MHU_AutoP_Setting : 17|2@0+ (1,0) [0|3] ""  VCU_PT
 SG_ MHU_VCU_CreepDisable_stt : 21|1@0+ (1,0) [0|1] ""  VCU_PT
 SG_ MHU_BrakeRegenMode : 23|2@0+ (1,0) [0|3] ""  VCU_PT
 SG_ MHU_ChargeSetTargetSOC : 30|7@0+ (1,0) [10|100] "%"  VCU_PT
 SG_ MHU_ChargeScheduleSet : 33|2@0+ (1,0) [0|3] ""  VCU_PT
 SG_ MHU_ChargingRequest : 35|2@0+ (1,0) [0|3] "-"  VCU_PT
 SG_ MHU_ChgPort_Open_req : 37|2@0+ (1,0) [0|3] "-"  VCU_PT
 SG_ MHU_SET_DrivingModeSwitch : 39|2@0+ (1,0) [0|3] "-"  VCU_PT
 SG_ MHU_ValetMode_Activation : 47|8@0+ (1,0) [0|255] ""  VCU_PT
 SG_ MHU_ValetMode_MaxSpeed : 55|8@0+ (1,0) [0|255] "km/h"  VCU_PT
 SG_ MHU_ChargingCurrentLimit : 61|6@0+ (1,0) [0|62] "A"  VCU_PT
 SG_ MHU_SET_ActivePreCondition : 63|2@0+ (1,0) [0|3] ""  VCU_PT

BO_ 1029 MHU_CCUF_ClimateSetting: 6 XGW_PT
 SG_ MHU_SET_CCUF_FrontDefrost : 47|2@0+ (1,0) [0|3] ""  VCU_PT

BO_ 1037 MHU_DIGIT_SPEED: 5 XGW_PT
  SG_ CHKSM_MHU_DIGIT_SPEED : 7|8@0+ (1,0) [0|255] "" VCU_PT
  SG_ ALV_MHU_DIGIT_SPEED : 11|4@0+ (1,0) [0|14] "" VCU_PT
  SG_ MHU_DigitSpeed : 23|9@0+ (1,0) [0|300] "km/h" VCU_PT

BO_ 1074 MHU_FOTA_STATUS: 8 XGW_PT
 SG_ MHU_FOTA_Checksum : 7|8@0+ (1,0) [0|255] ""  EDS_F,EDS_R,EPS2,GS,IDB_PT,POD,VCU_PT
 SG_ MHU_FOTA_Alive_Counter : 11|4@0+ (1,0) [0|14] ""  EDS_F,EDS_R,EPS2,GS,IDB_PT,POD,VCU_PT
 SG_ MHU_FOTA_State : 15|4@0+ (1,0) [0|14] "-"  EDS_F,EDS_R,EPS2,GS,IDB_PT,POD,VCU_PT
 SG_ MHU_FOTA_Error_Code : 23|8@0+ (1,0) [0|255] "-"  EDS_F,EDS_R,EPS2,GS,IDB_PT,POD,VCU_PT

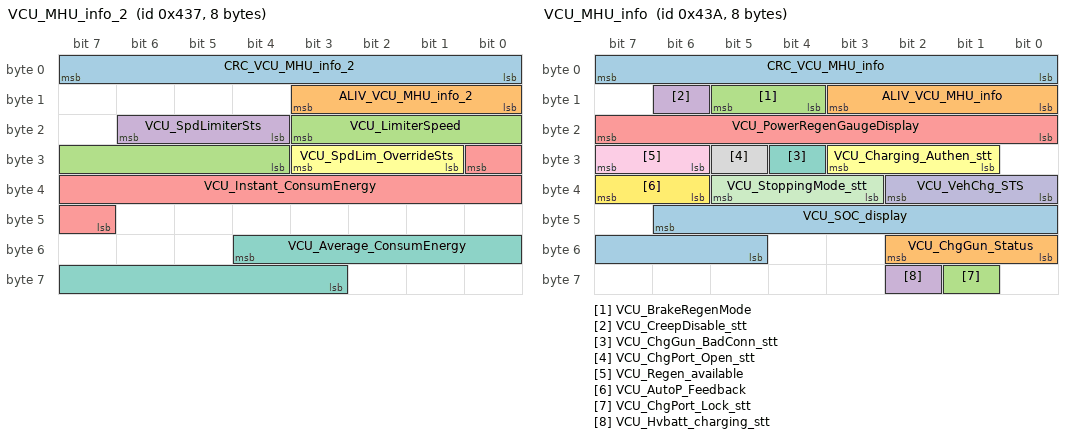
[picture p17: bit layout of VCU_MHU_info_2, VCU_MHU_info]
BO_ 1079 VCU_MHU_info_2: 8 VCU_PT
 SG_ CRC_VCU_MHU_info_2 : 7|8@0+ (1,0) [0|255] ""  XGW_PT
 SG_ ALIV_VCU_MHU_info_2 : 11|4@0+ (1,0) [0|14] ""  XGW_PT
 SG_ VCU_LimiterSpeed : 19|8@0+ (1,0) [0|200] "km/h"  XGW_PT
 SG_ VCU_SpdLimiterSts : 22|3@0+ (1,0) [0|7] ""  XGW_PT
 SG_ VCU_Instant_ConsumEnergy : 24|10@0+ (0.1,0) [0|100] "kWh/100km"  XGW_PT
 SG_ VCU_SpdLim_OverrideSts : 27|3@0+ (10,0) [0|30] "km/h"  XGW_PT
 SG_ VCU_Average_ConsumEnergy : 52|10@0+ (0.1,0) [0|100] "kWh/100km"  XGW_PT

BO_ 1080 EDS_Error_FR_A: 8 EDS_F
 SG_ CHKSM_EDS_Error_FR_A : 7|8@0+ (1,0) [0|255] ""  VCU_PT,XGW_PT
 SG_ ALV_EDS_Error_FR_A : 11|4@0+ (1,0) [0|14] ""  VCU_PT,XGW_PT
 SG_ EDS_FailNum_ERR_FWD : 23|8@0+ (1,0) [0|255] ""  VCU_PT,XGW_PT
 SG_ EDS_FailGrade_ERR_FWD : 26|3@0+ (1,0) [0|7] ""  VCU_PT,XGW_PT
 SG_ EDS_MotOverTempAlarm_FWD : 27|1@0+ (1,0) [0|1] ""  VCU_PT,XGW_PT
 SG_ EDS_MotOverTempFault_FWD : 28|1@0+ (1,0) [0|1] ""  VCU_PT,XGW_PT
 SG_ EDS_MotTempSenFault_FWD : 29|1@0+ (1,0) [0|1] ""  VCU_PT,XGW_PT
 SG_ EDS_EDSOverTempUFault_FWD : 30|1@0+ (1,0) [0|1] ""  VCU_PT,XGW_PT
 SG_ EDS_EDSOverTempVFault_FWD : 31|1@0+ (1,0) [0|1] ""  VCU_PT,XGW_PT
 SG_ EDS_EDSOverTempWFault_FWD : 32|1@0+ (1,0) [0|1] ""  VCU_PT,XGW_PT
 SG_ EDS_EDSOverTempAlarm_FWD : 33|1@0+ (1,0) [0|1] ""  VCU_PT,XGW_PT
 SG_ EDS_TCoolantOvHi_FWD : 34|1@0+ (1,0) [0|1] ""  VCU_PT,XGW_PT
 SG_ EDS_EDSTempCmpAlarm_FWD : 35|1@0+ (1,0) [0|1] ""  VCU_PT,XGW_PT
 SG_ EDS_EDSPhaOvCurentHWFault_FWD : 36|1@0+ (1,0) [0|1] ""  VCU_PT,XGW_PT
 SG_ EDS_EDSphaOffCalFault_FWD : 37|1@0+ (1,0) [0|1] ""  VCU_PT,XGW_PT
 SG_ EDS_EDSOverIdcLnkAlarm_FWD : 38|1@0+ (1,0) [0|1] ""  VCU_PT,XGW_PT
 SG_ EDS_EDSHVOverVoltageAlarm_FWD : 39|1@0+ (1,0) [0|1] ""  VCU_PT,XGW_PT
 SG_ EDS_EDSHVOverVoltageFault_FWD : 40|1@0+ (1,0) [0|1] ""  VCU_PT,XGW_PT
 SG_ EDS_EDSHVUnderVoltageAlarm_FWD : 41|1@0+ (1,0) [0|1] ""  VCU_PT,XGW_PT
 SG_ EDS_EDSHVUnderVoltageFault_FWD : 42|1@0+ (1,0) [0|1] ""  VCU_PT,XGW_PT
 SG_ EDS_RunToDischaErr_FWD : 43|1@0+ (1,0) [0|1] ""  VCU_PT,XGW_PT
 SG_ EDS_12VOverVoltageAlarm_FWD : 44|1@0+ (1,0) [0|1] ""  VCU_PT,XGW_PT
 SG_ EDS_12VUnderVoltageAlarm_FWD : 45|1@0+ (1,0) [0|1] ""  VCU_PT,XGW_PT
 SG_ EDS_MotOverAlarm_FWD : 46|1@0+ (1,0) [0|1] ""  VCU_PT,XGW_PT
 SG_ EDS_MotOverFault_FWD : 47|1@0+ (1,0) [0|1] ""  VCU_PT,XGW_PT
 SG_ EDS_ResolverOffsetAngle_FWD : 48|1@0+ (1,0) [0|1] ""  VCU_PT,XGW_PT
 SG_ SECCAN_EDS_Error_FR_A : 63|8@0+ (1,0) [0|255] ""  VCU_PT,XGW_PT

BO_ 1081 EDS_Error_RR_A: 8 EDS_R
 SG_ CHKSM_EDS_Error_RR_A : 7|8@0+ (1,0) [0|255] ""  VCU_PT,XGW_PT
 SG_ ALV_EDS_Error_RR_A : 11|4@0+ (1,0) [0|14] ""  VCU_PT,XGW_PT
 SG_ EDS_FailNum_ERR_RWD : 23|8@0+ (1,0) [0|255] ""  VCU_PT,XGW_PT
 SG_ EDS_FailGrade_ERR_RWD : 26|3@0+ (1,0) [0|7] ""  VCU_PT,XGW_PT
 SG_ EDS_MotOverTempAlarm_RWD : 27|1@0+ (1,0) [0|1] ""  VCU_PT,XGW_PT
 SG_ EDS_MotOverTempFault_RWD : 28|1@0+ (1,0) [0|1] ""  VCU_PT,XGW_PT
 SG_ EDS_MotTempSenFault_RWD : 29|1@0+ (1,0) [0|1] ""  VCU_PT,XGW_PT
 SG_ EDS_EDSOverTempUFault_RWD : 30|1@0+ (1,0) [0|1] ""  VCU_PT,XGW_PT
 SG_ EDS_EDSOverTempVFault_RWD : 31|1@0+ (1,0) [0|1] ""  VCU_PT,XGW_PT
 SG_ EDS_EDSOverTempWFault_RWD : 32|1@0+ (1,0) [0|1] ""  VCU_PT,XGW_PT
 SG_ EDS_EDSOverTempAlarm_RWD : 33|1@0+ (1,0) [0|1] ""  VCU_PT,XGW_PT
 SG_ EDS_TCoolantOvHi_RWD : 34|1@0+ (1,0) [0|1] ""  VCU_PT,XGW_PT
 SG_ EDS_EDSTempCmpAlarm_RWD : 35|1@0+ (1,0) [0|1] ""  VCU_PT,XGW_PT
 SG_ EDS_EDSPhaOvCurentHWFault_RWD : 36|1@0+ (1,0) [0|1] ""  VCU_PT,XGW_PT
 SG_ EDS_EDSphaOffCalFault_RWD : 37|1@0+ (1,0) [0|1] ""  VCU_PT,XGW_PT
 SG_ EDS_EDSOverIdcLnkAlarm_RWD : 38|1@0+ (1,0) [0|1] ""  VCU_PT,XGW_PT
 SG_ EDS_EDSHVOverVoltageAlarm_RWD : 39|1@0+ (1,0) [0|1] ""  VCU_PT,XGW_PT
 SG_ EDS_EDSHVOverVoltageFault_RWD : 40|1@0+ (1,0) [0|1] ""  VCU_PT,XGW_PT
 SG_ EDS_EDSHVUnderVoltageAlarm_RWD : 41|1@0+ (1,0) [0|1] ""  VCU_PT,XGW_PT
 SG_ EDS_EDSHVUnderVoltageFault_RWD : 42|1@0+ (1,0) [0|1] ""  VCU_PT,XGW_PT
 SG_ EDS_RunToDischaErr_RWD : 43|1@0+ (1,0) [0|1] ""  VCU_PT,XGW_PT
 SG_ EDS_12VOverVoltageAlarm_RWD : 44|1@0+ (1,0) [0|1] ""  VCU_PT,XGW_PT
 SG_ EDS_12VUnderVoltageAlarm_RWD : 45|1@0+ (1,0) [0|1] ""  VCU_PT,XGW_PT
 SG_ EDS_MotOverAlarm_RWD : 46|1@0+ (1,0) [0|1] ""  VCU_PT,XGW_PT
 SG_ EDS_MotOverFault_RWD : 47|1@0+ (1,0) [0|1] ""  VCU_PT,XGW_PT
 SG_ EDS_ResolverOffsetAngle_RWD : 48|1@0+ (1,0) [0|1] ""  VCU_PT,XGW_PT
 SG_ SECCAN_EDS_Error_RR_A : 63|8@0+ (1,0) [0|255] ""  VCU_PT,XGW_PT

BO_ 1082 VCU_MHU_info: 8 VCU_PT
 SG_ CRC_VCU_MHU_info : 7|8@0+ (1,0) [0|255] ""  XGW_PT
 SG_ ALIV_VCU_MHU_info : 11|4@0+ (1,0) [0|14] ""  XGW_PT
 SG_ VCU_BrakeRegenMode : 13|2@0+ (1,0) [0|3] "-"  XGW_PT
 SG_ VCU_CreepDisable_stt : 14|1@0+ (1,0) [0|1] ""  XGW_PT
 SG_ VCU_PowerRegenGaugeDisplay : 23|8@0+ (1,-100) [-100|100] "%"  XGW_PT
 SG_ VCU_Charging_Authen_stt : 27|3@0+ (1,0) [0|7] "-"  XGW_PT
 SG_ VCU_ChgGun_BadConn_stt : 28|1@0+ (1,0) [0|1] ""  XGW_PT
 SG_ VCU_ChgPort_Open_stt : 29|1@0+ (1,0) [0|1] ""  XGW_PT
 SG_ VCU_Regen_available : 31|2@0+ (1,0) [0|3] ""  XGW_PT
 SG_ VCU_VehChg_STS : 34|3@0+ (1,0) [0|7] ""  POD,XGW_PT
 SG_ VCU_StoppingMode_stt : 37|3@0+ (1,0) [0|7] ""  XGW_PT
 SG_ VCU_AutoP_Feedback : 39|2@0+ (1,0) [0|3] ""  XGW_PT
 SG_ VCU_SOC_display : 46|10@0+ (0.1,0) [0|100] "%"  XGW_PT,EDS_F,EDS_R
 SG_ VCU_ChgGun_Status : 50|3@0+ (1,0) [0|7] ""  XGW_PT
 SG_ VCU_ChgPort_Lock_stt : 57|1@0+ (1,0) [0|1] ""  XGW_PT
 SG_ VCU_Hvbatt_charging_stt : 58|1@0+ (1,0) [0|1] "-"  XGW_PT

BO_ 1083 EDS_Error_FR_B: 8 EDS_F
 SG_ CHKSM_EDS_Error_FR_B : 7|8@0+ (1,0) [0|255] ""  VCU_PT,XGW_PT
 SG_ ALV_EDS_Error_FR_B : 11|4@0+ (1,0) [0|14] ""  VCU_PT,XGW_PT
 SG_ EDS_iDcLnkOvCLimFail_FWD : 16|1@0+ (1,0) [0|1] ""  VCU_PT,XGW_PT
 SG_ EDS_MotBlockedFault_FWD : 17|1@0+ (1,0) [0|1] ""  VCU_PT,XGW_PT
 SG_ EDS_RSLErr_FWD : 18|1@0+ (1,0) [0|1] ""  VCU_PT,XGW_PT
 SG_ EDS_MotTrqLimFault_FWD : 19|1@0+ (1,0) [0|1] ""  VCU_PT,XGW_PT
 SG_ EDS_VCUChksumFault_FWD : 20|1@0+ (1,0) [0|1] ""  VCU_PT,XGW_PT
 SG_ EDS_IGBTFault_FWD : 22|1@0+ (1,0) [0|1] ""  VCU_PT,XGW_PT
 SG_ EDS_CANBusoffFault_FWD : 23|1@0+ (1,0) [0|1] ""  VCU_PT,XGW_PT
 SG_ EDS_TDrvBoardOvHiWarn_FWD : 24|1@0+ (1,0) [0|1] ""  VCU_PT,XGW_PT
 SG_ EDS_TIGBTOvHiFault_FWD : 25|1@0+ (1,0) [0|1] ""  VCU_PT,XGW_PT
 SG_ EDS_TIGBTOvHiWarn_FWD : 26|1@0+ (1,0) [0|1] ""  VCU_PT,XGW_PT
 SG_ EDS_IOHWABSampFail_FWD : 27|1@0+ (1,0) [0|1] ""  VCU_PT,XGW_PT
 SG_ EDS_EDSOpenFault_FWD : 28|1@0+ (1,0) [0|1] ""  VCU_PT,XGW_PT
 SG_ EDS_MotorOpenFault_FWD : 29|1@0+ (1,0) [0|1] ""  VCU_PT,XGW_PT
 SG_ EDS_EparkSampFail_FWD : 30|1@0+ (1,0) [0|1] ""  VCU_PT,XGW_PT
 SG_ EDS_EmacBlkdWarn_FWD : 31|1@0+ (1,0) [0|1] ""  VCU_PT,XGW_PT
 SG_ EDS_VerMatchFailureErr_FWD : 32|1@0+ (1,0) [0|1] ""  VCU_PT,XGW_PT
 SG_ EDS_DiashCirNoPsblErr_FWD : 33|1@0+ (1,0) [0|1] ""  VCU_PT,XGW_PT
 SG_ EDS_OperOutdRngErr_FWD : 34|1@0+ (1,0) [0|1] ""  VCU_PT,XGW_PT
 SG_ EDS_PhaseLossFaultErr_FWD : 35|1@0+ (1,0) [0|1] ""  VCU_PT,XGW_PT
 SG_ EDS_CPLDFault_FWD : 36|1@0+ (1,0) [0|1] ""  VCU_PT,XGW_PT
 SG_ EDS_CPLDFaultBaseSpd_FWD : 37|1@0+ (1,0) [0|1] ""  VCU_PT,XGW_PT
 SG_ EDS_IOHWABNen33Fail_FWD : 38|1@0+ (1,0) [0|1] ""  VCU_PT,XGW_PT
 SG_ EDS_HvMcuSlightFault_FWD : 39|1@0+ (1,0) [0|1] ""  VCU_PT,XGW_PT
 SG_ EDS_HvMcuSevFault_FWD : 40|1@0+ (1,0) [0|1] ""  VCU_PT,XGW_PT
 SG_ EDS_EDSPhaSampHWFault_FWD : 41|1@0+ (1,0) [0|1] ""  VCU_PT,XGW_PT
 SG_ EDS_IsOvHiErr_FWD : 42|1@0+ (1,0) [0|1] ""  VCU_PT,XGW_PT
 SG_ EDS_CanRollingCounterErr_FWD : 43|1@0+ (1,0) [0|1] ""  VCU_PT,XGW_PT
 SG_ EDS_CanTimeoutErr_FWD : 44|1@0+ (1,0) [0|1] ""  VCU_PT,XGW_PT
 SG_ EDS_CrashFault_FWD : 45|1@0+ (1,0) [0|1] ""  VCU_PT,XGW_PT
 SG_ EDS_PCFSlightFault_FWD : 46|1@0+ (1,0) [0|1] ""  VCU_PT,XGW_PT
 SG_ EDS_PCFSerFault_FWD : 47|1@0+ (1,0) [0|1] ""  VCU_PT,XGW_PT
 SG_ SECCAN_EDS_Error_FR_B : 63|8@0+ (1,0) [0|255] ""  VCU_PT,XGW_PT

BO_ 1084 EDS_Error_RR_B: 8 EDS_R
 SG_ CHKSM_EDS_Error_RR_B : 7|8@0+ (1,0) [0|255] ""  VCU_PT,XGW_PT
 SG_ ALV_EDS_Error_RR_B : 11|4@0+ (1,0) [0|14] ""  VCU_PT,XGW_PT
 SG_ EDS_iDcLnkOvCLimFail_RWD : 16|1@0+ (1,0) [0|1] ""  VCU_PT,XGW_PT
 SG_ EDS_MotBlockedFault_RWD : 17|1@0+ (1,0) [0|1] ""  VCU_PT,XGW_PT
 SG_ EDS_RSLErr_RWD : 18|1@0+ (1,0) [0|1] ""  VCU_PT,XGW_PT
 SG_ EDS_MotTrqLimFault_RWD : 19|1@0+ (1,0) [0|1] ""  VCU_PT,XGW_PT
 SG_ EDS_VCUChksumFault_RWD : 20|1@0+ (1,0) [0|1] ""  VCU_PT,XGW_PT
 SG_ EDS_IGBTFault_RWD : 22|1@0+ (1,0) [0|1] ""  VCU_PT,XGW_PT
 SG_ EDS_CANBusoffFault_RWD : 23|1@0+ (1,0) [0|1] ""  VCU_PT,XGW_PT
 SG_ EDS_TDrvBoardOvHiWarn_RWD : 24|1@0+ (1,0) [0|1] ""  VCU_PT,XGW_PT
 SG_ EDS_TIGBTOvHiFault_RWD : 25|1@0+ (1,0) [0|1] ""  VCU_PT,XGW_PT
 SG_ EDS_TIGBTOvHiWarn_RWD : 26|1@0+ (1,0) [0|1] ""  VCU_PT,XGW_PT
 SG_ EDS_IOHWABSampFail_RWD : 27|1@0+ (1,0) [0|1] ""  VCU_PT,XGW_PT
 SG_ EDS_EDSOpenFault_RWD : 28|1@0+ (1,0) [0|1] ""  VCU_PT,XGW_PT
 SG_ EDS_MotorOpenFault_RWD : 29|1@0+ (1,0) [0|1] ""  VCU_PT,XGW_PT
 SG_ EDS_EparkSampFail_RWD : 30|1@0+ (1,0) [0|1] ""  VCU_PT,XGW_PT
 SG_ EDS_EmacBlkdWarn_RWD : 31|1@0+ (1,0) [0|1] ""  VCU_PT,XGW_PT
 SG_ EDS_VerMatchFailureErr_RWD : 32|1@0+ (1,0) [0|1] ""  VCU_PT,XGW_PT
 SG_ EDS_DiashCirNoPsblErr_RWD : 33|1@0+ (1,0) [0|1] ""  VCU_PT,XGW_PT
 SG_ EDS_OperOutdRngErr_RWD : 34|1@0+ (1,0) [0|1] ""  VCU_PT,XGW_PT
 SG_ EDS_PhaseLossFaultErr_RWD : 35|1@0+ (1,0) [0|1] ""  VCU_PT,XGW_PT
 SG_ EDS_CPLDFault_RWD : 36|1@0+ (1,0) [0|1] ""  VCU_PT,XGW_PT
 SG_ EDS_CPLDFaultBaseSpd_RWD : 37|1@0+ (1,0) [0|1] ""  VCU_PT,XGW_PT
 SG_ EDS_IOHWABNen33Fail_RWD : 38|1@0+ (1,0) [0|1] ""  VCU_PT,XGW_PT
 SG_ EDS_HvMcuSlightFault_RWD : 39|1@0+ (1,0) [0|1] ""  VCU_PT,XGW_PT
 SG_ EDS_HvMcuSevFault_RWD : 40|1@0+ (1,0) [0|1] ""  VCU_PT,XGW_PT
 SG_ EDS_EDSPhaSampHWFault_RWD : 41|1@0+ (1,0) [0|1] ""  VCU_PT,XGW_PT
 SG_ EDS_IsOvHiErr_RWD : 42|1@0+ (1,0) [0|1] ""  VCU_PT,XGW_PT
 SG_ EDS_CanRollingCounterErr_RWD : 43|1@0+ (1,0) [0|1] ""  VCU_PT,XGW_PT
 SG_ EDS_CanTimeoutErr_RWD : 44|1@0+ (1,0) [0|1] ""  VCU_PT,XGW_PT
 SG_ EDS_CrashFault_RWD : 45|1@0+ (1,0) [0|1] ""  VCU_PT,XGW_PT
 SG_ EDS_PCFSlightFault_RWD : 46|1@0+ (1,0) [0|1] ""  VCU_PT,XGW_PT
 SG_ EDS_PCFSerFault_RWD : 47|1@0+ (1,0) [0|1] ""  VCU_PT,XGW_PT
 SG_ SECCAN_EDS_Error_RR_B : 63|8@0+ (1,0) [0|255] ""  VCU_PT,XGW_PT

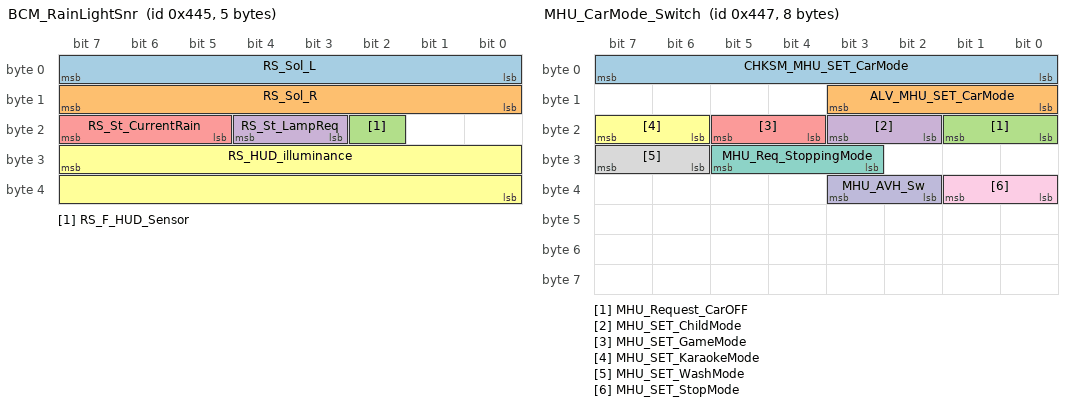
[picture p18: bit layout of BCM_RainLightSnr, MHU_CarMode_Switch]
BO_ 1093 BCM_RainLightSnr: 5 XGW_PT
 SG_ RS_Sol_L : 7|8@0+ (5,0) [0|1000] "W/m^2" Vector__XXX
 SG_ RS_Sol_R : 15|8@0+ (5,0) [0|1000] "W/m^2" Vector__XXX
 SG_ RS_F_HUD_Sensor : 18|1@0+ (1,0) [0|1] "cd/m2" Vector__XXX
 SG_ RS_St_LampReq : 20|2@0+ (1,0) [0|3] "" Vector__XXX
 SG_ RS_St_CurrentRain : 23|3@0+ (1,0) [0|7] ""  IDB_PT
 SG_ RS_HUD_illuminance : 31|16@0+ (1,0) [0|10000] "cd/m2" Vector__XXX

BO_ 1095 MHU_CarMode_Switch: 8 XGW_PT
 SG_ CHKSM_MHU_SET_CarMode : 7|8@0+ (1,0) [0|255] ""  VCU_PT
 SG_ ALV_MHU_SET_CarMode : 11|4@0+ (1,0) [0|14] ""  VCU_PT
 SG_ MHU_Request_CarOFF : 17|2@0+ (1,0) [0|3] "-"  VCU_PT
 SG_ MHU_SET_ChildMode : 19|2@0+ (1,0) [0|3] ""  VCU_PT
 SG_ MHU_SET_GameMode : 21|2@0+ (1,0) [0|3] ""  VCU_PT
 SG_ MHU_SET_KaraokeMode : 23|2@0+ (1,0) [0|3] ""  VCU_PT
 SG_ MHU_Req_StoppingMode : 29|3@0+ (1,0) [0|7] ""  VCU_PT
 SG_ MHU_SET_WashMode : 31|2@0+ (1,0) [0|3] ""  VCU_PT
 SG_ MHU_SET_StopMode : 33|2@0+ (1,0) [0|3] ""  VCU_PT
 SG_ MHU_AVH_Sw : 35|2@0+ (1,0) [0|3] ""  VCU_PT

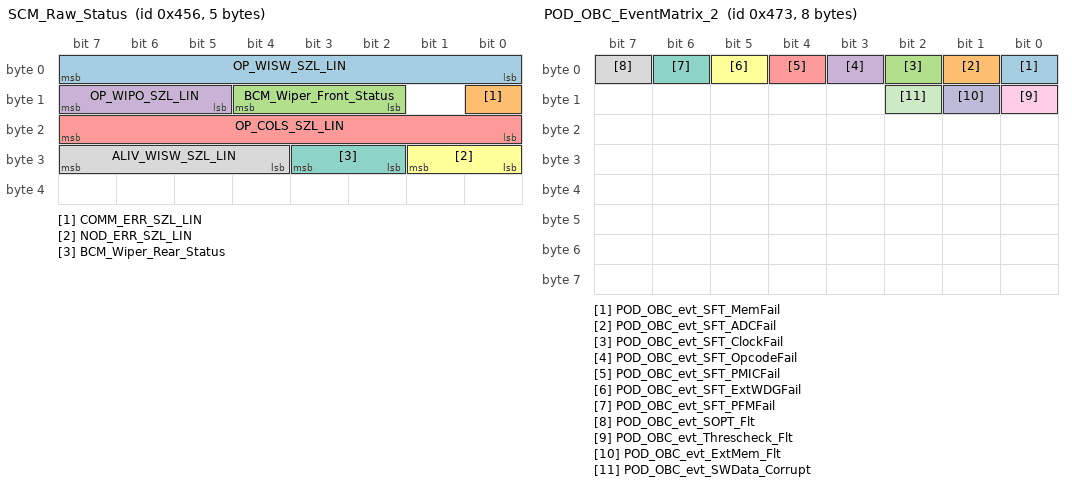
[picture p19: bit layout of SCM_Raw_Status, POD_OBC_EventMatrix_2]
BO_ 1110 SCM_Raw_Status: 5 XGW_PT
 SG_ OP_WISW_SZL_LIN : 7|8@0+ (1,0) [0|255] "" Vector__XXX
 SG_ COMM_ERR_SZL_LIN : 8|1@0+ (1,0) [0|1] "" Vector__XXX
 SG_ BCM_Wiper_Front_Status : 12|3@0+ (1,0) [0|7] ""  IDB_PT
 SG_ OP_WIPO_SZL_LIN : 15|3@0+ (1,0) [0|7] "-" Vector__XXX
 SG_ OP_COLS_SZL_LIN : 23|8@0+ (1,0) [0|255] "-" Vector__XXX
 SG_ NOD_ERR_SZL_LIN : 25|2@0+ (1,0) [0|3] "" Vector__XXX
 SG_ BCM_Wiper_Rear_Status : 27|2@0+ (1,0) [0|3] "" Vector__XXX
 SG_ ALIV_WISW_SZL_LIN : 31|4@0+ (1,0) [0|14] "" Vector__XXX

BO_ 1139 POD_OBC_EventMatrix_2: 8 POD
 SG_ POD_OBC_evt_SFT_MemFail : 0|1@0+ (1,0) [0|1] "" Vector__XXX
 SG_ POD_OBC_evt_SFT_ADCFail : 1|1@0+ (1,0) [0|1] "" Vector__XXX
 SG_ POD_OBC_evt_SFT_ClockFail : 2|1@0+ (1,0) [0|1] "" Vector__XXX
 SG_ POD_OBC_evt_SFT_OpcodeFail : 3|1@0+ (1,0) [0|1] "" Vector__XXX
 SG_ POD_OBC_evt_SFT_PMICFail : 4|1@0+ (1,0) [0|1] "" Vector__XXX
 SG_ POD_OBC_evt_SFT_ExtWDGFail : 5|1@0+ (1,0) [0|1] "" Vector__XXX
 SG_ POD_OBC_evt_SFT_PFMFail : 6|1@0+ (1,0) [0|1] "" Vector__XXX
 SG_ POD_OBC_evt_SOPT_Flt : 7|1@0+ (1,0) [0|1] "" Vector__XXX
 SG_ POD_OBC_evt_Threscheck_Flt : 8|1@0+ (1,0) [0|1] "" Vector__XXX
 SG_ POD_OBC_evt_ExtMem_Flt : 9|1@0+ (1,0) [0|1] "" Vector__XXX
 SG_ POD_OBC_evt_SWData_Corrupt : 10|1@0+ (1,0) [0|1] "" Vector__XXX

BO_ 1140 POD_GTW_Fault_Event: 8 POD
 SG_ POD_GW_En_CLC_Fail : 0|1@0+ (1,0) [0|1] "" Vector__XXX
 SG_ POD_GW_ADC_Convert_Fail : 1|1@0+ (1,0) [0|1] "" Vector__XXX
 SG_ POD_GW_Intbus_CANSM_Fail : 2|1@0+ (1,0) [0|1] "" Vector__XXX
 SG_ POD_GW_Pubbus_CANSM_Fail : 3|1@0+ (1,0) [0|1] "" Vector__XXX
 SG_ POD_GW_ECUM_KillAllReq : 4|1@0+ (1,0) [0|1] "" Vector__XXX
 SG_ POD_GW_ECUM_ConfigData_Fail : 5|1@0+ (1,0) [0|1] "" Vector__XXX
 SG_ POD_GW_ECUM_ImproperCaller : 6|1@0+ (1,0) [0|1] "" Vector__XXX
 SG_ POD_GW_ECUM_RAMchecked_Fail : 7|1@0+ (1,0) [0|1] "" Vector__XXX
 SG_ POD_GW_FEE_Erase_Fail : 8|1@0+ (1,0) [0|1] "" Vector__XXX
 SG_ POD_GW_FEE_InitGC_Fail : 9|1@0+ (1,0) [0|1] "" Vector__XXX
 SG_ POD_GW_FEE_ReadGC_Fail : 10|1@0+ (1,0) [0|1] "" Vector__XXX
 SG_ POD_GW_FEE_GC_Trigger_Fail : 11|1@0+ (1,0) [0|1] "" Vector__XXX
 SG_ POD_GW_FEE_WriteGC_Fail : 12|1@0+ (1,0) [0|1] "" Vector__XXX
 SG_ POD_GW_FEE_InvalidReq : 13|1@0+ (1,0) [0|1] "" Vector__XXX
 SG_ POD_GW_FEE_Read_Fail : 14|1@0+ (1,0) [0|1] "" Vector__XXX
 SG_ POD_GW_FEE_UnconfigBLK_Exceed : 15|1@0+ (1,0) [0|1] "" Vector__XXX
 SG_ POD_GW_FEE_Write_Fail : 16|1@0+ (1,0) [0|1] "" Vector__XXX
 SG_ POD_GW_FEE_OverWriteCycle : 17|1@0+ (1,0) [0|1] "" Vector__XXX
 SG_ POD_GW_Fls_Compared_Fail : 18|1@0+ (1,0) [0|1] "" Vector__XXX
 SG_ POD_GW_Fls_Erase_Fail : 19|1@0+ (1,0) [0|1] "" Vector__XXX
 SG_ POD_GW_Fls_Read_Fail : 20|1@0+ (1,0) [0|1] "" Vector__XXX
 SG_ POD_GW_Fls_UnexpectedFlashID : 21|1@0+ (1,0) [0|1] "" Vector__XXX
 SG_ POD_GW_Fls_Write_Fail : 22|1@0+ (1,0) [0|1] "" Vector__XXX
 SG_ POD_GW_MCU_CCU6_CLC_DisableErr : 23|1@0+ (1,0) [0|1] "" Vector__XXX
 SG_ POD_GW_MCU_CCU6_CLC_EnableErr : 24|1@0+ (1,0) [0|1] "" Vector__XXX
 SG_ POD_GW_CCUCON_UpdateErr : 25|1@0+ (1,0) [0|1] "" Vector__XXX
 SG_ POD_GW_MCU_CLK_Fail : 26|1@0+ (1,0) [0|1] "" Vector__XXX
 SG_ POD_GW_MCU_CONVCTRLCLC_DisErr : 27|1@0+ (1,0) [0|1] "" Vector__XXX
 SG_ POD_GW_MCU_CONVCTRLCLC_EnableErr : 28|1@0+ (1,0) [0|1] "" Vector__XXX
 SG_ POD_GW_MCU_GPT12_CLC_DisableErr : 29|1@0+ (1,0) [0|1] "" Vector__XXX
 SG_ POD_GW_MCU_GPT12_CLC_EnableErr : 30|1@0+ (1,0) [0|1] "" Vector__XXX
 SG_ POD_GW_MCU_GTM_CLC_DisableErr : 31|1@0+ (1,0) [0|1] "" Vector__XXX
 SG_ POD_GW_MCU_GTM_CLC_EnableErr : 32|1@0+ (1,0) [0|1] "" Vector__XXX
 SG_ POD_GW_MCU_Oscillator_Fail : 33|1@0+ (1,0) [0|1] "" Vector__XXX
 SG_ POD_GW_MCU_PeriPLL_Lock_Loss : 34|1@0+ (1,0) [0|1] "" Vector__XXX
 SG_ POD_GW_MCU_PeriPLL_Timeout_Fail : 35|1@0+ (1,0) [0|1] "" Vector__XXX
 SG_ POD_GW_MCU_PMSCWR_UpdateErr : 36|1@0+ (1,0) [0|1] "" Vector__XXX
 SG_ POD_GW_MCU_SysPLL_LockLoss : 37|1@0+ (1,0) [0|1] "" Vector__XXX
 SG_ POD_GW_MCU_SysPLL_Timeout_Fail : 38|1@0+ (1,0) [0|1] "" Vector__XXX
 SG_ POD_GW_NVM_Integrity_Fail : 39|1@0+ (1,0) [0|1] "" Vector__XXX
 SG_ POD_GW_NVM_Loss_Redundancy_Fail : 40|1@0+ (1,0) [0|1] "" Vector__XXX
 SG_ POD_GW_NVM_Queue_OverFlow : 41|1@0+ (1,0) [0|1] "" Vector__XXX
 SG_ POD_GW_NVM_Request_Fail : 42|1@0+ (1,0) [0|1] "" Vector__XXX
 SG_ POD_GW_NVM_Verify_Fail : 43|1@0+ (1,0) [0|1] "" Vector__XXX
 SG_ POD_GW_NVM_WriteProtected : 44|1@0+ (1,0) [0|1] "" Vector__XXX
 SG_ POD_GW_NVM_WrongBlockID : 45|1@0+ (1,0) [0|1] "" Vector__XXX
 SG_ POD_GW_SPI_HWError : 46|1@0+ (1,0) [0|1] "" Vector__XXX
 SG_ POD_GW_DCDC_EventMatrix_mia : 47|1@0+ (1,0) [0|1] "" Vector__XXX
 SG_ POD_GW_OBC_EventMatrix_mia : 48|1@0+ (1,0) [0|1] "" Vector__XXX
 SG_ POD_GW_DCFC_EventMatrix_mia : 49|1@0+ (1,0) [0|1] "" Vector__XXX
 SG_ POD_GW_Public_Busoff : 50|1@0+ (1,0) [0|1] "" Vector__XXX
 SG_ POD_GW_Private_Busoff : 51|1@0+ (1,0) [0|1] "" Vector__XXX
 SG_ POD_GW_VBAT_Low : 52|1@0+ (1,0) [0|1] "" Vector__XXX
 SG_ POD_GW_VBat_High : 53|1@0+ (1,0) [0|1] "" Vector__XXX

CM_ BO_ 568 "Front MCU currently status";
CM_ BO_ 569 "Rear MCU currently status";
CM_ BO_ 570 "IDB Front Wheel Status";
CM_ BO_ 571 "IDB Rear Wheel Status";
CM_ BO_ 572 "IDB Brake Pedal";
CM_ BO_ 573 "IDB Wheel Pressor Estimated";
CM_ BO_ 574 "RCU Status";
CM_ BO_ 581 "BMS Temperature";
CM_ BO_ 585 "BMS Coolant water temperature";
CM_ BO_ 596 "Wheel Speed Rear";
CM_ BO_ 597 "Wheel Speed Front";
CM_ BO_ 608 "VCU_Wheel_Torque_Status";
CM_ BO_ 609 "VCU POD Command1";
CM_ BO_ 610 "VCU POD Information";
CM_ BO_ 680 "MCU Front Power";
CM_ BO_ 681 "MCU Rear Power";
CM_ BO_ 714 "Tester control BMS";
CM_ SG_ 720 FCAM_AESA_Status "The signal will be used to indicate the MRM status";
CM_ BO_ 760 "MHU Date Time";
CM_ BO_ 761 "MHU Date time UTC.";
CM_ BO_ 768 "CCU Status";
CM_ BO_ 770 "CCU temprature and pressure";
CM_ BO_ 773 "VCU Heat Cool Status";
CM_ BO_ 774 "CCU Heat Cool Request";
CM_ BO_ 787 "POD StatusCharger1";
CM_ BO_ 803 "POD StatusCharger2";
CM_ BO_ 806 "POD StatusDCDC1";
CM_ BO_ 807 "POD Fast Charge status";
CM_ BO_ 816 "IC_MILEAGE
";
CM_ BO_ 838 "POD Status2";
CM_ BO_ 840 "MCU Front status";
CM_ BO_ 841 "MCU Rear status";
CM_ BO_ 870 "POD Thermal";
CM_ BO_ 885 "BMS Relay";
CM_ BO_ 895 "EPS advanced information";
CM_ BO_ 896 "BCM vehicle identifier number";
CM_ BO_ 897 "ACM seatbelt and buckle status for seatbelt reminder";
CM_ BO_ 905 "VCU_status";
CM_ BO_ 920 "BCM Authentication message";
CM_ BO_ 921 "VCU Authentication message";
CM_ BO_ 937 "VCU thermal info feedback";
CM_ BO_ 992 "VCU High Voltage System Status";
CM_ BO_ 993 "VCU_HMI_Info.";
CM_ BO_ 1027 "MHU Driving Mode Setting";
CM_ BO_ 1029 "MHU Climate Setting";
CM_ BO_ 1037 "Display Vehicle speed CAN Signal sent by MHU";
CM_ BO_ 1074 "MHU_FOTA_STATUS";
CM_ BO_ 1079 "VCU MHU Information";
CM_ BO_ 1080 "MCU Front Error";
CM_ BO_ 1081 "MCU Rear Error";
CM_ BO_ 1082 "VCU MHU Information";
CM_ BO_ 1083 "MCU Front Error";
CM_ BO_ 1084 "MCU Rear Error";
CM_ BO_ 1093 "Rain light sensor";
CM_ BO_ 1095 "MHU_CarMode_Switch";
CM_ BO_ 1110 "SCM_Raw_Status";
CM_ SG_ 568 CHSKM_EDS_curSts_FR "Checksum";
CM_ SG_ 568 ALV_EDS_curSts_FR "Alive Counter";
CM_ SG_ 568 EDS_EPARK_STS_FWD "E-park status";
CM_ SG_ 568 EDS_EPARK_ERR_FWD "E-park erroe";
CM_ SG_ 568 EDS_disxhg_st_FWD "State of active discharge of EDS";
CM_ SG_ 568 EDS_tempValid_FWD "Indicate the valid flag of EDS current temperature";
CM_ SG_ 568 EDS_MotTemp_MEAS_EDS_valid_FWD "Indicate the valid flag of MotorTemperature";
CM_ SG_ 568 EDS_MotTemp_MEAS_EDS_FWD "MotorTemperature";
CM_ SG_ 568 EDS_temp_FWD "EDS current temperature";
CM_ SG_ 568 EDS_CoolFlowrate_DMD_FWD "Coolant Florate demand from FWD EDS";
CM_ SG_ 568 EDS_ActiveHeating_state "EDS_Active heating function status";
CM_ SG_ 568 EDS_DampingState_FWD "FWD EDS Damping state";
CM_ SG_ 568 EDS_IGBTState_FWD "FWD EDS IGBT State";
CM_ SG_ 569 CHSKM_EDS_curSts_RR "Checksum";
CM_ SG_ 569 ALV_EDS_curSts_RR "Alive Counter";
CM_ SG_ 569 EDS_disxhg_st_RWD "State of active discharge of EDS";
CM_ SG_ 569 EDS_tempValid_RWD "Indicate the valid flag of EDS current temperature";
CM_ SG_ 569 EDS_MotTemp_MEAS_EDS_valid_RWD "Indicate the valid flag of MotorTemperature";
CM_ SG_ 569 EDS_MotTemp_MEAS_EDS_RWD "MotorTemperature";
CM_ SG_ 569 EDS_temp_RWD "EDS current temperature";
CM_ SG_ 569 EDS_CoolFlowrate_DMD_RWD "Coolant Florate demand from RWD EDS";
CM_ SG_ 569 EDS_DampingState_RWD "RWD EDS Damping state";
CM_ SG_ 569 EDS_IGBTState_RWD "RWD EDS IGBT State";
CM_ SG_ 570 CHKSM_IDB_WheelSts_FR "Checksum";
CM_ SG_ 570 ALV_IDB_WheelSts_FR "Alive Counter";
CM_ SG_ 570 IDB_WheelDirection_FR "IDB Front Right Wheel Direction";
CM_ SG_ 570 IDB_WheelDirection_FL "IDB Front Left Wheel Direction";
CM_ SG_ 570 IDB_WheelSpeedRC_FL "IDB Front Left Wheel Speed Pulse";
CM_ SG_ 570 IDB_WheelSpeedRC_FR "IDB Front Right Wheel Speed Pulse";
CM_ SG_ 571 CHKSM_IDB_WheelSts_RR "Checksum";
CM_ SG_ 571 ALV_IDB_WheelSts_RR "Alive Counter";
CM_ SG_ 571 IDB_WheelDirection_RR "IDB Rear Right Wheel Direction";
CM_ SG_ 571 IDB_WheelDirection_RL "IDB Rear Left Wheel Direction";
CM_ SG_ 571 IDB_WheelSpeedRC_RL "IDB Rear Left Wheel Speed Pulse";
CM_ SG_ 571 IDB_WheelSpeedRC_RR "IDB Rear Right Wheel Speed Pulse";
CM_ SG_ 572 CHKSM_IDB_BrkPdl "Checksum";
CM_ SG_ 572 ALV_IDB_BrkPdl "Alive Counter";
CM_ SG_ 572 IDB_DPBAvlSts "Dynamic parking brake available status by IDB (CDP)";
CM_ SG_ 572 IDB_ReqApplyEPBVldtn "Request EPB apply or release validation";
CM_ SG_ 572 IDB_ReqApplyEPB "Request EPB apply or release";
CM_ SG_ 572 IDB_DiagMode "Diagnosis mode";
CM_ SG_ 572 IDB_DPBActvSts "Dynamic parking brake active status by IDB (CDP)";
CM_ SG_ 572 IDB_CircPres "CiIDBit pressure";
CM_ SG_ 572 IDB_CircPresVldty "CiIDBit pressure validity";
CM_ SG_ 572 IDB_BrkPedlVal "Brake pedal value (mm)";
CM_ SG_ 572 IDB_BrkPedlValVldty "Brake pedal sensor failed";
CM_ SG_ 573 IDB_FrntLeEstimdWhlPres "Front  left  of the estimated wheels pressure";
CM_ SG_ 573 IDB_FrntLeEstimdWhlPresVldty "Front  left  of the estimated wheels pressure Validity";
CM_ SG_ 573 IDB_FrntRiEstimdWhlPres "Front  right   of the estimated wheels pressure";
CM_ SG_ 573 IDB_FrntRiEstimdWhlPresVldty "Front  right   of the estimated wheels pressure Validity";
CM_ SG_ 573 IDB_ReLeEstimdWhlPres "Rear left  of the estimated wheels pressure";
CM_ SG_ 573 IDB_ReLeEstimdWhlPresVldty "Rear  left  of the estimated wheels pressure Validity";
CM_ SG_ 573 IDB_ReRiEstimdWhlPres "Rear  right  of the estimated wheels pressure";
CM_ SG_ 573 IDB_ReRiEstimdWhlPresVldty "Rear  right  of the estimated wheels pressure Validity";
CM_ SG_ 574 CHKSM_RCU_EPB_Sts "Checksum";
CM_ SG_ 574 ALV_RCU_EPB_Sts "Alive Counter";
CM_ SG_ 574 RCU_EPB_DynamicApplySta "Dynamic Apply Status";
CM_ SG_ 574 RCU_EPB_WarnLampSta "EPB Warning Lamp State";
CM_ SG_ 574 RCU_EPB_ParkLampSta "Park Lamp state";
CM_ SG_ 574 RCU_EPB_SwitchSta "EPB Switch State ";
CM_ SG_ 574 RCU_EPB_DecelReqSts "EPB Deceleration Request Status";
CM_ SG_ 574 RCU_EPB_SystemState "Unified state of EPB actuator";
CM_ SG_ 574 RCU_EPB_DecelReq "EPB Deceleration Request";
CM_ SG_ 574 RCU_PBCInApplyRelsReq "Host To PBC Apply Release Request Command";
CM_ SG_ 574 RCU_PBCRollrBenchActv "Host To PBC Roller Bench Active State";
CM_ SG_ 574 RCU_EPB_FltSts "EPB Fault Status";
CM_ SG_ 574 RCU_ReqBrkLiOn "Request Brake Light On";
CM_ SG_ 581 Checksum_0x245 "Checksum";
CM_ SG_ 581 Rolling_Counter_0x245 "Rolling Counter";
CM_ SG_ 581 BMS_ProbeNumMaxCellTemp "Probe Number of Max Cell Temperature ";
CM_ SG_ 581 BMS_MinCellTemp "Min Cell Temperature ";
CM_ SG_ 581 BMS_ProbeNumMinCellTemp "Probe Number of Min Cell Temperature ";
CM_ SG_ 581 BMS_PackTemp "Pack Temperature ";
CM_ SG_ 581 BMS_MaxCellTemp "Max Cell Temperature ";
CM_ SG_ 581 BMS_MaxMinDiffCellTemp "max and min cell temperature differences ";
CM_ SG_ 585 CHSKM_BMS_CoolntInletOutletTmp "Check sum";
CM_ SG_ 585 ALV_BMS_CoolntInletOutletTmp "Alive counter";
CM_ SG_ 585 BMS_CoolantInletTemp "Temperature of Battery Coolant Inlet";
CM_ SG_ 585 BMS_CoolantOutletTemp "Temperature of Battery Coolant Outlet";
CM_ SG_ 596 CRC_AVL_RPM_WHL_REAR "Checksum";
CM_ SG_ 596 ALIV_AVL_RPM_WHL_REAR "Alive Counter";
CM_ SG_ 596 AVL_RPM_WHL_RLH "Measured speed of the rear left single wheel.";
CM_ SG_ 596 AVL_RPM_WHL_RRH "Measured speed of the rear right single wheel.";
CM_ SG_ 596 QU_AVL_RPM_WHL_RLH "status qualifier to signal actual-value_RPM_wheel_HL.";
CM_ SG_ 596 QU_AVL_RPM_WHL_RRH "status qualifier to signal actual-value_RPM_wheel_HR.";
CM_ SG_ 597 CRC_AVL_RPM_WHL_FRONT "Checksum";
CM_ SG_ 597 ALIV_AVL_RPM_WHL_FRONT "Alive Counter";
CM_ SG_ 597 AVL_RPM_WHL_FLH "Measured speed of the front left single wheel.";
CM_ SG_ 597 AVL_RPM_WHL_FRH "Measured speed of the front right single wheel.";
CM_ SG_ 597 QU_AVL_RPM_WHL_FLH "status qualifier to signal actual-value_RPM_wheel_VL.";
CM_ SG_ 597 QU_AVL_RPM_WHL_FRH "status qualifier to signal actual-value_RPM_wheel_VL.";
CM_ SG_ 608 CRC_VCU_Wheel_Torque_Status "Checksum";
CM_ SG_ 608 ALIV_VCU_Wheel_Torque_Status "Alive counter";
CM_ SG_ 608 VCU_Available_Wheel_Torque "VCU Max Available Wheel Torque for Acceleration control";
CM_ SG_ 608 VCU_IDB_Available "VCU Availability for IDB engine control";
CM_ SG_ 608 VCU_IDB_ControledRes "VCU Handshake Request Feedback";
CM_ SG_ 608 SECCAN_VCU_Wheel_Torq_Sts "Seed generated from Secure CAN algorithm
";
CM_ SG_ 609 CHSKM_VCU_POD_reqCharge "Check sum";
CM_ SG_ 609 ALV_VCU_POD_reqCharge "Alive counter";
CM_ SG_ 609 VCU_enableFC "E2E - Requests FC Contactors to close";
CM_ SG_ 609 VCU_enableOBC "Requests OBC to turn on";
CM_ SG_ 609 VCU_iLineLimit "AC line current limit";
CM_ SG_ 609 VCU_iOBCRequest "Requested OBC DC output current";
CM_ SG_ 609 VCU_vOBCRequest "Requested OBC DC output voltage";
CM_ SG_ 610 CHSKM_VCU_POD_info "Check sum";
CM_ SG_ 610 ALV_VCU_POD_info "Alive counter";
CM_ SG_ 610 BMS_statusHVIL "HVIL status";
CM_ SG_ 610 BMS_iPack "Battery current";
CM_ SG_ 610 THM_tempCoolantInletEMU "Thermal Input Coolant Temperature";
CM_ SG_ 610 THM_pwmPumpOBC "Pump PWM";
CM_ SG_ 680 CHSKM_EDS_Power_FR "Checksum";
CM_ SG_ 680 ALV_EDS_Power_FR "Alive Counter";
CM_ SG_ 680 EDS_MotorSerialNum_FWD "FrontMotorSerialNumber";
CM_ SG_ 680 EDS_MaxTrq_FWD "AllowMaxTorque(long time max torque available)";
CM_ SG_ 680 EDS_MinTrq_FWD "AllowMinTorque(long time min torque available)";
CM_ SG_ 681 CHSKM_EDS_R_Power_RR "Checksum";
CM_ SG_ 681 ALV_EDS_R_Power_RR "Alive Counter";
CM_ SG_ 681 EDS_MotorSerialNum_RWD "RearMotorSerialNumber";
CM_ SG_ 681 EDS_MaxTrq_RWD "AllowMaxTorque(long time max torque available)";
CM_ SG_ 681 EDS_MinTrq_RWD "AllowMinTorque(long time min torque available)";
CM_ SG_ 714 CHKSM_IC_SENSOR "Checksum";
CM_ SG_ 714 ALV_IC_SENSOR "Alive Counter";
CM_ SG_ 714 MHU_STAT_AmbientTempRaw "Ambient Temperature Raw";
CM_ SG_ 714 MHU_STAT_FuelLevel "Fuel Level 3 to 63 l  (only for ICE)";
CM_ SG_ 714 MHU_STAT_AmbientTemp "Ambient Temperature filtered";
CM_ SG_ 714 MHU_STAT_CoolantLevelStatus "Low level coolant indicator";
CM_ SG_ 720 CHKSM_FCAM_AESA_Sts "Checksum";
CM_ SG_ 720 ALV_FCAM_AESA_Sts "Alive Counter";
CM_ SG_ 720 FCAM_AESA_DoorUnlock_Req "The signal will be used to unlock the doors once the AESA control is done and the vehicle is brough to stop";
CM_ SG_ 720 FCAM_AESA_ECALL_Req "The signal will be used to triggered the ECALL functionality once the AESA control is done and the vehicle is brough to stop";
CM_ SG_ 720 FCAM_AESA_Status "The signal will be used to indicate the MRM status";
CM_ SG_ 760 DISP_HR "The signal / parameter indicates the current hour.";
CM_ SG_ 760 DISP_MN "The signal / parameter indicates the current minute.";
CM_ SG_ 760 DISP_SEC "The signal / parameter indicates the current second.";
CM_ SG_ 760 DISP_DATE_DAY "The signal / parameter indicates the current day.";
CM_ SG_ 760 DISP_DATE_MON "The signal / parameter indicates the current month.";
CM_ SG_ 760 DISP_DATE_WDAY "The signal   parameter indicates the current day of the week.";
CM_ SG_ 760 DISP_DATE_YR "The signal / parameter indicates the current year.";
CM_ SG_ 760 ST_DISP_CTI_DATE "The signal / parameter indicates the state of the switch summer winter time.";
CM_ SG_ 761 DISP_HR_UTC "The signal/parameter indcates the current hour";
CM_ SG_ 761 DISP_MN_UTC "The signal/parameter indicates the current minute";
CM_ SG_ 761 DISP_SEC_UTC "The signal / parameter indicates the current second.";
CM_ SG_ 761 DISP_DATE_DAY_UTC "The signal / parameter indicates the current day.";
CM_ SG_ 761 DISP_DATE_MON_UTC "The signal/parameter indicates the current month";
CM_ SG_ 761 DISP_DATE_YR_UTC "The signal / parameter indicates the current year.";
CM_ SG_ 768 CCU_STAT_SyncClimateZone "Status dual clima automatic";
CM_ SG_ 768 CCU_STAT_Auto "Status activation of auto mode";
CM_ SG_ 768 CCU_STAT_Aircondition "Aircondition status";
CM_ SG_ 768 CCU_STAT_IonButton "Status if the ionisator is active";
CM_ SG_ 768 CCU_STAT_MaxAc "Status activation of MAX AC mode";
CM_ SG_ 768 CCU_STAT_OnOff "Status On  Off button for clima";
CM_ SG_ 768 CCU_STAT_FanSpeed "Blower settings/Fan Speed for climate system";
CM_ SG_ 768 CCU_STAT_RecircFlap "Recirculation flap status, 100% fresh air, 0% recirculation mode";
CM_ SG_ 768 CCU_STAT_FlapPos "Request for flap position";
CM_ SG_ 768 CCU_STAT_Defrost "Status activation of Defrost mode";
CM_ SG_ 768 CCU_STAT_PTC_Heater "CCU status for PTC heater";
CM_ SG_ 768 CCU_STAT_TempDriver "CCU status for temperature regulationr driver (Display Temperature)";
CM_ SG_ 768 CCU_STAT_TempPassenger "CCU status for temperature regulation  passenger(Display Temperature)";
CM_ SG_ 770 CHKSM_CCU_TEMP_PRESSURE "Checksum";
CM_ SG_ 770 ALV_CCU_TEMP_PRESSURE "Alive Counter";
CM_ SG_ 770 CCU_Pressure_AC "The compressor line pressure.";
CM_ SG_ 770 CCU_InteriorTemp "CCU interiour  temperature. Invalid = 251-255";
CM_ SG_ 770 CCU_TempEx_AC "Outside temperature calculated by CCU";
CM_ SG_ 770 CCU_EvaporatorTemp "Actual evaporator temperature of the HVAC unit. Invalid = 251-255";
CM_ SG_ 773 HtrMediumOutletTemp "Heater medium outlet temperature (Purpose for PTC) Only BEV car";
CM_ SG_ 773 CcuHtrOnOffSts "PTC status from VCU  Only BEV car";
CM_ SG_ 773 EcompOnOffSts "Electrical compressor on/off status  Only BEV car";
CM_ SG_ 773 HtrMediumInletTemp "Heater medium inlet temperature (Purpose for PTC) Only BEV car";
CM_ SG_ 773 ECompRpm "E-compressor actual RPM  Only BEV car";
CM_ SG_ 773 ECompPowerConsumption "E-compressor actual power consumption  Only BEV car";
CM_ SG_ 774 CCU_EcompOnOffRequest "Electrical compressor on/off request only for BEV vehicle";
CM_ SG_ 774 CCU_HtrOnOffRequest "PTC on/off request from CCU  only for BEV vehicle";
CM_ SG_ 774 CCU_AcOffCode_CCU "Compressor off code";
CM_ SG_ 774 CCU_CoolPowerDemand "CCU Cooling Demand in kilowat  only for BEV vehicle";
CM_ SG_ 774 CCU_HeatPowerDemand "CCU Heating Demand in kilowat  only for BEV vehicle";
CM_ SG_ 774 CCU_PTCOffCode_CCU "PTC Off Code only for BEV vehicle";
CM_ SG_ 774 CCU_CoolDemand "CCU Cooling  Demand in percentage  only for BEV vehicle";
CM_ SG_ 774 CCU_HeatDemand "CCU Heating Demand in percentage only for BEV vehicle";
CM_ SG_ 787 CHSKM_POD_StatusCharger1 "Check sum";
CM_ SG_ 787 ALV_POD_StatusCharger1 "Alive counter";
CM_ SG_ 787 POD_statusOBC "OBC status";
CM_ SG_ 787 POD_OBC_Max_Current_Out "Max DC current OBC able to output";
CM_ SG_ 787 POD_iDCOut "POD measured output current on OBC output";
CM_ SG_ 787 POD_vDCOut "POD measured bus voltage at OBC output";
CM_ SG_ 787 SECCAN_POD_StatusCharger1 "Secret portion from Secure CAN algorithm";
CM_ SG_ 803 CHSKM_POD_StatusCharger2 "Check sum";
CM_ SG_ 803 ALV_POD_StatusCharger2 "Alive counter";
CM_ SG_ 803 POD_iACInput "POD measured current on AC input";
CM_ SG_ 803 POD_vACInput "POD measured voltage on AC input";
CM_ SG_ 803 POD_tempACCharger "POD measured temperature on AC charger";
CM_ SG_ 803 POD_tempColdplate "coolant temperature into the 3in1";
CM_ SG_ 806 CHSKM_POD_StatusDCDC1 "Check sum";
CM_ SG_ 806 ALV_POD_StatusDCDC1 "Alive counter";
CM_ SG_ 806 POD_statusDCDC "DCDC status";
CM_ SG_ 806 POD_DCDC_Max_Current_Out "Max LV current DCDC able to output";
CM_ SG_ 807 CHKSM_POD_StatusFC "Check sum POD_StatusFC";
CM_ SG_ 807 ALV_POD_StatusFC "Alive counter POD_StatusFC";
CM_ SG_ 807 POD_vFC "POD measured voltage on charge port side of fast charge contactors";
CM_ SG_ 807 POD_statusFCContactors "DC charge contactor";
CM_ SG_ 816 MILE_KM "Mileage information
";
CM_ SG_ 816 FLLV_FUTA "The fuel level of  tank. 255 value invalid";
CM_ SG_ 816 RNG "Calculated range of IPC";
CM_ SG_ 816 ST_FLLV_FUTA_SPAR "State of the tank reserve indicator 

";
CM_ SG_ 838 CHSKM_POD_StatusDCDC2 "Check sum";
CM_ SG_ 838 ALV_POD_StatusDCDC2 "Alive counter";
CM_ SG_ 838 POD_vDCInput "POD measured DC bus voltage at DCDC input";
CM_ SG_ 838 POD_iDCDCOutput "POD reported 12V current";
CM_ SG_ 838 POD_vDCDCOutput "POD reported 12V voltage";
CM_ SG_ 840 CHKSM_EDS_Sts_FR "Checksum";
CM_ SG_ 840 ALV_EDS_Sts_FR "Alive Counter";
CM_ SG_ 840 EDS_bus_Volt_FWD "Bus voltage of current EDS";
CM_ SG_ 840 EDS_HVIL_STS_FWD "FWD EDS HighVoltage state";
CM_ SG_ 840 EDS_bus_Curr_FWD "Bus current of current EDS";
CM_ SG_ 840 EDS_MtrNumb_FWD "Motor Number";
CM_ SG_ 840 EDS_DriveMtrNmb_FWD "DriveMotorNumber";
CM_ SG_ 841 CHKSM_EDS_Sts_RR "Checksum";
CM_ SG_ 841 ALV_EDS_Sts_RR "Alive Counter";
CM_ SG_ 841 EDS_bus_Volt_RWD "Bus voltage of current EDS";
CM_ SG_ 841 EDS_HVIL_STS_RWD "RWD EDS HighVoltage state";
CM_ SG_ 841 EDS_bus_Curr_RWD "Bus current of current EDS";
CM_ SG_ 841 EDS_DriveMtrNmb_RWD "DriveMotorNumber";
CM_ SG_ 841 EDS_MtrNumb_RWD "Motor Number";
CM_ SG_ 870 CHSKM_POD_Thermal "Check sum";
CM_ SG_ 870 ALV_PPOD_POD_Thermal "Alive counter";
CM_ SG_ 870 POD_tempHVBusPlus "Reported temperature of positive HV busbar";
CM_ SG_ 870 POD_tempHVBusNeg "Reported temperature of negative HV busbar";
CM_ SG_ 870 POD_tempInternal "Reported internal temperauture";
CM_ SG_ 870 POD_tempColdPlate "Reported 3in1 coldplate(cooling Block surface) temperauture";
CM_ SG_ 870 POD_FlowRate_Req "Flow rate required for POD";
CM_ SG_ 870 POD_CoolPwrDemand "Cooling Power requested by POD";
CM_ SG_ 885 Checksum_0x375 "Checksum";
CM_ SG_ 885 Rolling_Counter_0x375 "Rolling Counter";
CM_ SG_ 885 BMS_PreChgRelay_ERR "Precahrge relay is not working properly ";
CM_ SG_ 885 BMS_TotalNegRelay_ERR "Main Negative Relay Error ";
CM_ SG_ 885 BMS_MainPosRelay_ERR "Main Position Relay Error ";
CM_ SG_ 885 BMS_MainPosRelay_STS "Main Positive Relay Status ";
CM_ SG_ 885 BMS_PreChgRelay_STS "PreCharge Relay Status ";
CM_ SG_ 885 BMS_TotalNegRelay_STS "Main Negative Relay Status ";
CM_ SG_ 895 CHKSM_EPS2_Advanced "Checksum";
CM_ SG_ 895 ALV_EPS2_Advanced "Alive Counter";
CM_ SG_ 895 EPS2_TorqSensorSts "Validation bit of torsion bar torque";
CM_ SG_ 895 EPS2_SteeringTorque "Steering torque (Positive, to left; Negative, to right)";
CM_ SG_ 895 EPS2_SteeringTorqueValid "validity of steering torque";
CM_ SG_ 895 EPS2_Mode "Electric steering mode";
CM_ SG_ 895 EPS2_Steering_angle_spd "EPS_Steering_angle_spd";
CM_ SG_ 895 EPS2AngRespSts "Electric steering mode";
CM_ SG_ 895 EPS2_Steering_angle "EPS steering wheel ange (Positive, to left; Negative, to right)";
CM_ SG_ 896 VIN_Byte1 "This signal contains the seventh last digit of the chassis number. (The individual digits are encoded in ASCII characters.)
Bit 0: LSB, Bit 7: MSB";
CM_ SG_ 896 VIN_Byte2 "This signal contains the sixth last digit of the chassis number. (The individual digits are encoded in ASCII characters.)
Bit 0: LSB, Bit 7: MSB";
CM_ SG_ 896 VIN_Byte3 "This signal contains the fifth last digit of the chassis number. (The individual digits are encoded in ASCII characters.)
Bit 0: LSB, Bit 7: MSB";
CM_ SG_ 896 VIN_Byte4 "This signal contains the fourth last digit of the chassis number. (The individual digits are encoded in ASCII characters.)
Bit 0: LSB, Bit 7: MSB";
CM_ SG_ 896 VIN_Byte5 "This signal contains the third last digit of the chassis number. (The individual digits are encoded in ASCII characters.)
Bit 0: LSB, Bit 7: MSB";
CM_ SG_ 896 VIN_Byte6 "This signal contains the penultimate digit of the chassis number. (The individual digits are encoded in ASCII characters.)
Bit 0: LSB, Bit 7: MSB";
CM_ SG_ 896 VIN_Byte7 "This signal contains the last digit of the chassis number. (The individual digits are encoded in ASCII characters.)
Bit 0: LSB, Bit 7: MSB";
CM_ SG_ 897 CHKSM_ACM_SEAT_OCCUPATION "Checksum";
CM_ SG_ 897 ALV_ACM_SEAT_OCCUPATION "Alive Counter";
CM_ SG_ 897 ACM_Seat_Occupancy_Passenger "Signal to indicate status of occupancy";
CM_ SG_ 897 ACM_Seat_Occupancy_2nd_Row_Dri "Signal to indicate status of occupancy";
CM_ SG_ 897 ACM_Seat_Occupancy_2nd_Row_Pas "Signal to indicate status of occupancy";
CM_ SG_ 897 ACM_Seat_Occupancy_2nd_Row_Mid "Signal to indicate status of occupancy";
CM_ SG_ 897 ACM_Seat_Belt_Status_Passenger "Seatbelt status for seatbelt reminder function";
CM_ SG_ 897 ACM_Seat_Belt_Status_Driver "Seatbelt status for seatbelt reminder function";
CM_ SG_ 897 ACM_Seat_Belt_Status_2nd_Row_Dri "Seatbelt status for seatbelt reminder function";
CM_ SG_ 897 ACM_Seat_Belt_Status_2nd_Row_Mid "Seatbelt status for seatbelt reminder function";
CM_ SG_ 897 ACM_Seat_Belt_Status_2nd_Row_Pas "Seatbelt status for seatbelt reminder function";
CM_ SG_ 905 VCU_IMMO_Sts "IMMO status";
CM_ SG_ 905 SECCAN_VCU_IMMO_Sts "Seed generated from Secure CAN algorithm
";
CM_ SG_ 920 BCM_Immo_Byte_0 "BCM Authentication signal byte 0";
CM_ SG_ 920 BCM_Immo_Byte_1 "BCM Authentication signal byte 1";
CM_ SG_ 920 BCM_Immo_Byte_2 "BCM Authentication signal byte 2";
CM_ SG_ 920 BCM_Immo_Byte_3 "BCM Authentication signal byte 3";
CM_ SG_ 920 BCM_Immo_Byte_4 "BCM Authentication signal byte 4";
CM_ SG_ 920 BCM_Immo_Byte_5 "BCM Authentication signal byte 5";
CM_ SG_ 920 BCM_Immo_Byte_6 "BCM Authentication signal byte 6";
CM_ SG_ 920 BCM_Immo_Byte_7 "BCM Authentication signal byte 7";
CM_ SG_ 921 VCU_Immo_Byte_0 "VCU Authentication signal byte 0";
CM_ SG_ 921 VCU_Immo_Byte_1 "VCU Authentication signal byte 1";
CM_ SG_ 921 VCU_Immo_Byte_2 "VCU Authentication signal byte 2";
CM_ SG_ 921 VCU_Immo_Byte_3 "VCU Authentication signal byte 3";
CM_ SG_ 921 VCU_Immo_Byte_4 "VCU Authentication signal byte 4";
CM_ SG_ 921 VCU_Immo_Byte_5 "VCU Authentication signal byte 5";
CM_ SG_ 921 VCU_Immo_Byte_6 "VCU Authentication signal byte 6";
CM_ SG_ 921 VCU_Immo_Byte_7 "VCU Authentication signal byte 7";
CM_ SG_ 937 SUM_VCU_Thermal_info_FB "Checksum";
CM_ SG_ 937 ALV_VCU_Thermal_info_FB "Alive counter";
CM_ SG_ 937 VCU_Pump_2_Stt "Cooling pump 2 status (HV Battery loop)";
CM_ SG_ 937 VCU_Pump_1_Stt "Cooling pump 1 status (EDS loop)";
CM_ SG_ 937 VCU_Pump_1_Flowrate "Cooling pump 1 flow rate (EDS loop)";
CM_ SG_ 937 VCU_Pump_2_Flowrate "Cooling pump 2 flow rate  (HV Battery loop)";
CM_ SG_ 937 VCU_TempSensor_1_value "Temp sensor 1 measured value (EDS loop)";
CM_ SG_ 937 VCU_TempSensor_6_value "Temp sensor 6 measured value (PTC Heater output)";
CM_ SG_ 937 VCU_TempSensor_5_value "Temp sensor 5 measured value (LTR2 - Low Temp Radiator 2)";
CM_ SG_ 992 CRC_VCU_HVsystem_status "Checksum";
CM_ SG_ 992 ALIV_VCU_HVsystem_status "Alive counter";
CM_ SG_ 992 VCU_RunningRange "Estimated running range ( at present )";
CM_ SG_ 992 VCU_RunningRange_chrg_estSts "Status of estimation running range after charged by current charging condition ( max chg.current, chg.time, ?)";
CM_ SG_ 992 VCU_RunningRange_charged "Estimated running range after charged by current charging condition ( max chg.current, chg.time, ?)";
CM_ SG_ 992 VCU_HVbatSoc_charged "Estimated HVBattery SOC by current charging condition ( max chg.current, chg.time, ?)";
CM_ SG_ 992 VCU_HVbatSoc_charged_estStatus "Status of SOC Estimation by current charging condition ( max chg.current, chg.time, ?)";
CM_ SG_ 993 CRC_VCU_HMI_Info "Checksum";
CM_ SG_ 993 ALIV_VCU_HMI_Info "Alive counter";
CM_ SG_ 993 VCU_SetCruiseSpd "Set Cruise Speed";
CM_ SG_ 993 VCU_CruiseCtrlSts "Cruise state";
CM_ SG_ 993 VCU_MHU_Ack_ChgSche_stt "Status Enabled/ Disabled of Schedule Charging acknowledged by VCU base on request from MHU 0x403 MHU_ChargeScheduleSet.";
CM_ SG_ 993 VCU_MHU_Ack_TargetSOC "Target SOC acknowledged by VCU base on request from MHU";
CM_ SG_ 993 VCU_ValetMode_sts "Status indicate valet mode is effected to VCU";
CM_ SG_ 993 VCU_ValetMode_MaxSpeedSts "Max speed setting of Valet mode";
CM_ SG_ 993 SECCAN_VCU_HMI_Info "Seed generated from Secure CAN algorithm";
CM_ SG_ 1015 CHSKM_MFS_Control_Button "Checksum";
CM_ SG_ 1015 ALV_MFS_Control_Button "Alive Counter";
CM_ SG_ 1015 MFS_VoiceRecognitionOn_Off "VoiceRecognition control";
CM_ SG_ 1015 MFS_ISAControl "ISA Control";
CM_ SG_ 1015 MFS_CruiseSpeedIncrease "Cruise Speed Increase";
CM_ SG_ 1015 MFS_TelephoneCall_EndCall "Telephone Call functionality control  ";
CM_ SG_ 1015 MFS_LKAControl "Line Keep Assistance/Line Departure warning Control";
CM_ SG_ 1015 MFS_CruiseGapIncrease "Cruise Gap Increase";
CM_ SG_ 1015 MFS_CruiseOn_Off "Cruise control On/Off";
CM_ SG_ 1015 MFS_CruiseGapDecrease "Cruise Gap Decrease";
CM_ SG_ 1015 MFS_CAN_RESControl "Cancel/Resume Cruise control/Speed Limiter";
CM_ SG_ 1015 MFS_CruiseSpeedDecrease "Cruise Speed Decrease";
CM_ SG_ 1015 MFS_SourseControl "Resourse Control";
CM_ SG_ 1015 MFS_UpControl "Up Control";
CM_ SG_ 1015 MFS_DownControl "Down Control";
CM_ SG_ 1015 MFS_LeftControl "Left Control";
CM_ SG_ 1015 MFS_Failure "Multi-Funtion Switch Failure";
CM_ SG_ 1015 MFS_RightControl "Right Control";
CM_ SG_ 1015 MFS_OK_Control "OK Control";
CM_ SG_ 1027 CHKSM_MHU_EVSetting "Checksum for EV setting";
CM_ SG_ 1027 MHU_AutoP_Setting "Request for VCU to ON/OFF Auto P setting";
CM_ SG_ 1027 ALV_MHU_EVSetting "Alive Counter for EV Setting";
CM_ SG_ 1027 MHU_VCU_CreepDisable_stt "Request for VCU to disable creep function";
CM_ SG_ 1027 MHU_BrakeRegenMode "Brake Regen Style";
CM_ SG_ 1027 MHU_ChargeSetTargetSOC "Request for VCU to set target HV SOC";
CM_ SG_ 1027 MHU_ChargeScheduleSet "Request for VCU to enable/disable Charging Scheduling";
CM_ SG_ 1027 MHU_ChargingRequest "Request for VCU to ON/OFF Charging when schedule is reached";
CM_ SG_ 1027 MHU_ChgPort_Open_req "Request to open charging port(release latch)";
CM_ SG_ 1027 MHU_SET_DrivingModeSwitch "Change vehicle driving mode";
CM_ SG_ 1027 MHU_ValetMode_Activation "Activate Valet mode from MHU";
CM_ SG_ 1027 MHU_ValetMode_MaxSpeed "Setting of maximum allowable in valet mode";
CM_ SG_ 1027 MHU_ChargingCurrentLimit "Request VCU the max charging current at the rush hour - Apply for AC charging only at home";
CM_ SG_ 1027 MHU_SET_ActivePreCondition "Request active PreCondition State (schedule heating battery)";
CM_ SG_ 1027 MHU_SpdLim_Override "Extra Override Speed in Speed Limiter";
CM_ SG_ 1029 MHU_SET_CCUF_FrontDefrost "Change Flap poition to Front Defrost";
CM_ SG_ 1037 CHKSM_MHU_DIGIT_SPEED "Checksum";
CM_ SG_ 1037 ALV_MHU_DIGIT_SPEED "Alive Counter";
CM_ SG_ 1037 MHU_DigitSpeed "This signal represents the digital speed and is displayed; values between 301 and 511 are invalid.";
CM_ SG_ 1074 MHU_FOTA_Checksum "FOTA global status message checksum";
CM_ SG_ 1074 MHU_FOTA_Alive_Counter "FOTA global status message alive counter";
CM_ SG_ 1074 MHU_FOTA_State "FOTA global status";
CM_ SG_ 1074 MHU_FOTA_Error_Code "FOTA Error Code";
CM_ SG_ 1079 CRC_VCU_MHU_info_2 "Checksum";
CM_ SG_ 1079 ALIV_VCU_MHU_info_2 "Alive Counter";
CM_ SG_ 1079 VCU_Instant_ConsumEnergy "Instant Consumption Energy";
CM_ SG_ 1079 VCU_Average_ConsumEnergy "Average Consumption Energy";
CM_ SG_ 1079 VCU_SpdLimiterSts "Speed Limiter state";
CM_ SG_ 1079 VCU_LimiterSpeed "Set Limiter Speed";
CM_ SG_ 1079 VCU_SpdLim_OverrideSts "Extra Override Speed in Speed Limiter";
CM_ SG_ 1080 CHKSM_EDS_Error_FR_A "Check sum";
CM_ SG_ 1080 ALV_EDS_Error_FR_A "Alive Counter";
CM_ SG_ 1080 EDS_FailNum_ERR_FWD "FaultNumber";
CM_ SG_ 1080 EDS_FailGrade_ERR_FWD "Fault level of EDS system";
CM_ SG_ 1080 EDS_MotOverTempAlarm_FWD "Motor over temperture alarm ";
CM_ SG_ 1080 EDS_MotOverTempFault_FWD "Motor over temperture fault ";
CM_ SG_ 1080 EDS_MotTempSenFault_FWD "Motor temperature sensor fault ";
CM_ SG_ 1080 EDS_EDSOverTempUFault_FWD "EDS Upha Over temperature fault ";
CM_ SG_ 1080 EDS_EDSOverTempVFault_FWD "EDS Vpha Over temperature fault ";
CM_ SG_ 1080 EDS_EDSOverTempWFault_FWD "EDS Wpha Over temperature fault ";
CM_ SG_ 1080 EDS_EDSOverTempAlarm_FWD "EDS over temperture alarm ";
CM_ SG_ 1080 EDS_TCoolantOvHi_FWD " Alarm  when Cooling water temperature is too high ";
CM_ SG_ 1080 EDS_EDSTempCmpAlarm_FWD "EDS temp offset checkout alarm ";
CM_ SG_ 1080 EDS_EDSPhaOvCurentHWFault_FWD "Phase Current Overcurrent hardware fault ";
CM_ SG_ 1080 EDS_EDSphaOffCalFault_FWD "EDS phase Current Offset Calibration Fault";
CM_ SG_ 1080 EDS_EDSOverIdcLnkAlarm_FWD "EDS IdcLnk Overcurrent alarm";
CM_ SG_ 1080 EDS_EDSHVOverVoltageAlarm_FWD "EDS high voltage over voltage alarm ";
CM_ SG_ 1080 EDS_EDSHVOverVoltageFault_FWD "EDS high voltage over voltage fault ";
CM_ SG_ 1080 EDS_EDSHVUnderVoltageAlarm_FWD "EDS high voltage under voltage alarm";
CM_ SG_ 1080 EDS_EDSHVUnderVoltageFault_FWD "EDS high voltage under voltage fault ";
CM_ SG_ 1080 EDS_RunToDischaErr_FWD "Stateflow fail to enter avtive discharge ";
CM_ SG_ 1080 EDS_12VOverVoltageAlarm_FWD "12V Power over voltage alarm";
CM_ SG_ 1080 EDS_12VUnderVoltageAlarm_FWD "12V Power under voltage alarm ";
CM_ SG_ 1080 EDS_MotOverAlarm_FWD "Motor overspeed fault alarm ";
CM_ SG_ 1080 EDS_MotOverFault_FWD "Motor overspeed fault fault ";
CM_ SG_ 1080 EDS_ResolverOffsetAngle_FWD "EDS offset angle check fault
";
CM_ SG_ 1080 SECCAN_EDS_Error_FR_A "Seed generated from Secure CAN algorithm
";
CM_ SG_ 1081 CHKSM_EDS_Error_RR_A "Check sum";
CM_ SG_ 1081 ALV_EDS_Error_RR_A "Alive Counter";
CM_ SG_ 1081 EDS_FailNum_ERR_RWD "FaultNumber";
CM_ SG_ 1081 EDS_FailGrade_ERR_RWD "Fault level of EDS system";
CM_ SG_ 1081 EDS_MotOverTempAlarm_RWD "Motor over temperture alarm ";
CM_ SG_ 1081 EDS_MotOverTempFault_RWD "Motor over temperture fault ";
CM_ SG_ 1081 EDS_MotTempSenFault_RWD "Motor temperature sensor fault ";
CM_ SG_ 1081 EDS_EDSOverTempUFault_RWD "EDS Upha Over temperature fault ";
CM_ SG_ 1081 EDS_EDSOverTempVFault_RWD "EDS Vpha Over temperature fault ";
CM_ SG_ 1081 EDS_EDSOverTempWFault_RWD "EDS Wpha Over temperature fault ";
CM_ SG_ 1081 EDS_EDSOverTempAlarm_RWD "EDS over temperture alarm ";
CM_ SG_ 1081 EDS_TCoolantOvHi_RWD " Alarm  when Cooling water temperature is too high ";
CM_ SG_ 1081 EDS_EDSTempCmpAlarm_RWD "EDS temp offset checkout alarm ";
CM_ SG_ 1081 EDS_EDSPhaOvCurentHWFault_RWD "Phase Current Overcurrent hardware fault ";
CM_ SG_ 1081 EDS_EDSphaOffCalFault_RWD "EDS phase Current Offset Calibration Fault";
CM_ SG_ 1081 EDS_EDSOverIdcLnkAlarm_RWD "EDS IdcLnk Overcurrent alarm";
CM_ SG_ 1081 EDS_EDSHVOverVoltageAlarm_RWD "EDS high voltage over voltage alarm ";
CM_ SG_ 1081 EDS_EDSHVOverVoltageFault_RWD "EDS high voltage over voltage fault ";
CM_ SG_ 1081 EDS_EDSHVUnderVoltageAlarm_RWD "EDS high voltage under voltage alarm";
CM_ SG_ 1081 EDS_EDSHVUnderVoltageFault_RWD "EDS high voltage under voltage fault ";
CM_ SG_ 1081 EDS_RunToDischaErr_RWD "Stateflow fail to enter avtive discharge ";
CM_ SG_ 1081 EDS_12VOverVoltageAlarm_RWD "12V Power over voltage alarm";
CM_ SG_ 1081 EDS_12VUnderVoltageAlarm_RWD "12V Power under voltage alarm ";
CM_ SG_ 1081 EDS_MotOverAlarm_RWD "Motor overspeed fault alarm ";
CM_ SG_ 1081 EDS_MotOverFault_RWD "Motor overspeed fault fault ";
CM_ SG_ 1081 EDS_ResolverOffsetAngle_RWD "EDS offset angle check fault
";
CM_ SG_ 1081 SECCAN_EDS_Error_RR_A "Seed generated from Secure CAN algorithm
";
CM_ SG_ 1082 VCU_AutoP_Feedback "VCU feedback Auto P Setting status";
CM_ SG_ 1082 CRC_VCU_MHU_info "Checksum";
CM_ SG_ 1082 ALIV_VCU_MHU_info "Alive counter";
CM_ SG_ 1082 VCU_BrakeRegenMode "VCU Brake regenerative mode";
CM_ SG_ 1082 VCU_CreepDisable_stt "Feedback for Creep disable request";
CM_ SG_ 1082 VCU_PowerRegenGaugeDisplay "Power Regen gauge display, plus vaue is power level, minus value is regen level. ";
CM_ SG_ 1082 VCU_Charging_Authen_stt "Authentication status with chg. station ( for display only)";
CM_ SG_ 1082 VCU_ChgGun_BadConn_stt "Charging gun bad connection status";
CM_ SG_ 1082 VCU_ChgPort_Open_stt "Open status of charging port";
CM_ SG_ 1082 VCU_Regen_available "When braking / coasting regeneration system not available or regeneration system capability = 0 or regeneration system = failed.";
CM_ SG_ 1082 VCU_VehChg_STS "Vehicle Charging Status";
CM_ SG_ 1082 VCU_StoppingMode_stt "Stopping mode status";
CM_ SG_ 1082 VCU_SOC_display "HV battery SOC for displaying only - for VCU strategy";
CM_ SG_ 1082 VCU_ChgGun_Status "Charging gun status";
CM_ SG_ 1082 VCU_ChgPort_Lock_stt "Lock status of chaging port";
CM_ SG_ 1082 VCU_Hvbatt_charging_stt "HV battery charging - not charging status,for displaying only ( for both regen/ charging )";
CM_ SG_ 1083 CHKSM_EDS_Error_FR_B "Check sum";
CM_ SG_ 1083 ALV_EDS_Error_FR_B "Alive Counter";
CM_ SG_ 1083 EDS_iDcLnkOvCLimFail_FWD "Bus current over-current fault";
CM_ SG_ 1083 EDS_MotBlockedFault_FWD "Motor blocked fault ";
CM_ SG_ 1083 EDS_RSLErr_FWD "Rotary transformer signal fault ";
CM_ SG_ 1083 EDS_MotTrqLimFault_FWD "Motor torque limit fault";
CM_ SG_ 1083 EDS_VCUChksumFault_FWD "VCU CheckSum fault ";
CM_ SG_ 1083 EDS_IGBTFault_FWD "IGBT fault ";
CM_ SG_ 1083 EDS_CANBusoffFault_FWD "CAN busoff fault ";
CM_ SG_ 1083 EDS_TDrvBoardOvHiWarn_FWD "Alarm when drive plate temperature is too high";
CM_ SG_ 1083 EDS_TIGBTOvHiFault_FWD "IGBT junction temperature over temperature fault";
CM_ SG_ 1083 EDS_TIGBTOvHiWarn_FWD "IGBT junction temperature over temperature alarm";
CM_ SG_ 1083 EDS_IOHWABSampFail_FWD "Chip control power sampling failure ";
CM_ SG_ 1083 EDS_EDSOpenFault_FWD "EDS open plate fault ";
CM_ SG_ 1083 EDS_MotorOpenFault_FWD "Motor open plate fault ";
CM_ SG_ 1083 EDS_EparkSampFail_FWD "EPP position sampling fault";
CM_ SG_ 1083 EDS_EmacBlkdWarn_FWD "Motor locked rotor warning ";
CM_ SG_ 1083 EDS_VerMatchFailureErr_FWD "EDS Software Version match Failure Fault ";
CM_ SG_ 1083 EDS_DiashCirNoPsblErr_FWD "Unable to active short circuit fault ";
CM_ SG_ 1083 EDS_OperOutdRngErr_FWD "Short circuit over temperature operation diagnosis ";
CM_ SG_ 1083 EDS_PhaseLossFaultErr_FWD "Missing phase fault ";
CM_ SG_ 1083 EDS_CPLDFault_FWD "CPLD Fault";
CM_ SG_ 1083 EDS_CPLDFaultBaseSpd_FWD "CPLD enter ASC fault based on motor speed";
CM_ SG_ 1083 EDS_IOHWABNen33Fail_FWD "Feedback NEN33 fault";
CM_ SG_ 1083 EDS_HvMcuSlightFault_FWD "HvMcu Slight fault";
CM_ SG_ 1083 EDS_HvMcuSevFault_FWD "HvMcu serious fault";
CM_ SG_ 1083 EDS_EDSPhaSampHWFault_FWD "UVW phase current monitoring sampling hard wire fault";
CM_ SG_ 1083 EDS_IsOvHiErr_FWD "Phase current overcurrent diagnosis";
CM_ SG_ 1083 EDS_CanRollingCounterErr_FWD "Receive count error ";
CM_ SG_ 1083 EDS_CanTimeoutErr_FWD " Receive timeout error";
CM_ SG_ 1083 EDS_CrashFault_FWD "Crash signal fault";
CM_ SG_ 1083 EDS_PCFSlightFault_FWD "PCF EPP slight fault";
CM_ SG_ 1083 EDS_PCFSerFault_FWD "PCF EPP serious fault";
CM_ SG_ 1083 SECCAN_EDS_Error_FR_B "Seed generated from Secure CAN algorithm
";
CM_ SG_ 1084 CHKSM_EDS_Error_RR_B "Check sum";
CM_ SG_ 1084 ALV_EDS_Error_RR_B "Alive Counter";
CM_ SG_ 1084 EDS_iDcLnkOvCLimFail_RWD "Bus current over-current fault";
CM_ SG_ 1084 EDS_MotBlockedFault_RWD "Motor blocked fault ";
CM_ SG_ 1084 EDS_RSLErr_RWD "Rotary transformer signal fault ";
CM_ SG_ 1084 EDS_MotTrqLimFault_RWD "Motor torque limit fault";
CM_ SG_ 1084 EDS_VCUChksumFault_RWD "VCU CheckSum fault ";
CM_ SG_ 1084 EDS_IGBTFault_RWD "IGBT fault ";
CM_ SG_ 1084 EDS_CANBusoffFault_RWD "CAN busoff fault ";
CM_ SG_ 1084 EDS_TDrvBoardOvHiWarn_RWD "Alarm when drive plate temperature is too high";
CM_ SG_ 1084 EDS_TIGBTOvHiFault_RWD "IGBT junction temperature over temperature fault";
CM_ SG_ 1084 EDS_TIGBTOvHiWarn_RWD "IGBT junction temperature over temperature alarm";
CM_ SG_ 1084 EDS_IOHWABSampFail_RWD "Chip control power sampling failure ";
CM_ SG_ 1084 EDS_EDSOpenFault_RWD "EDS open plate fault ";
CM_ SG_ 1084 EDS_MotorOpenFault_RWD "Motor open plate fault ";
CM_ SG_ 1084 EDS_EparkSampFail_RWD "EPP position sampling fault";
CM_ SG_ 1084 EDS_EmacBlkdWarn_RWD "Motor locked rotor warning ";
CM_ SG_ 1084 EDS_VerMatchFailureErr_RWD "EDS Software Version match Failure Fault ";
CM_ SG_ 1084 EDS_DiashCirNoPsblErr_RWD "Unable to active short circuit fault ";
CM_ SG_ 1084 EDS_OperOutdRngErr_RWD "Short circuit over temperature operation diagnosis ";
CM_ SG_ 1084 EDS_PhaseLossFaultErr_RWD "Missing phase fault ";
CM_ SG_ 1084 EDS_CPLDFault_RWD "CPLD Fault";
CM_ SG_ 1084 EDS_CPLDFaultBaseSpd_RWD "CPLD enter ASC fault based on motor speed";
CM_ SG_ 1084 EDS_IOHWABNen33Fail_RWD "Feedback NEN33 fault";
CM_ SG_ 1084 EDS_HvMcuSlightFault_RWD "HvMcu Slight fault";
CM_ SG_ 1084 EDS_HvMcuSevFault_RWD "HvMcu serious fault";
CM_ SG_ 1084 EDS_EDSPhaSampHWFault_RWD "UVW phase current monitoring sampling hard wire fault";
CM_ SG_ 1084 EDS_IsOvHiErr_RWD "Phase current overcurrent diagnosis";
CM_ SG_ 1084 EDS_CanRollingCounterErr_RWD "Receive count error ";
CM_ SG_ 1084 EDS_CanTimeoutErr_RWD " Receive timeout error";
CM_ SG_ 1084 EDS_CrashFault_RWD "Crash signal fault";
CM_ SG_ 1084 EDS_PCFSlightFault_RWD "PCF EPP slight fault";
CM_ SG_ 1084 EDS_PCFSerFault_RWD "PCF EPP serious fault";
CM_ SG_ 1084 SECCAN_EDS_Error_RR_B "Seed generated from Secure CAN algorithm
";
CM_ SG_ 1093 RS_Sol_L "Left Solar sensor values for the CCU";
CM_ SG_ 1093 RS_Sol_R "Right Solar sensor values for the CCU";
CM_ SG_ 1093 RS_F_HUD_Sensor "HUD HW error";
CM_ SG_ 1093 RS_St_LampReq "Rain light sensor lamp request";
CM_ SG_ 1093 RS_St_CurrentRain "Represents the intensity of rain from RLS";
CM_ SG_ 1093 RS_HUD_illuminance "HUD sensor input";
CM_ SG_ 1095 CHKSM_MHU_SET_CarMode "Checksum";
CM_ SG_ 1095 ALV_MHU_SET_CarMode "Alive counter";
CM_ SG_ 1095 MHU_Request_CarOFF "MHU request Car go to OFF state";
CM_ SG_ 1095 MHU_SET_ChildMode "Set Car in Child mode which keep climate control running and delay CPD (EU NCAP requirement)";
CM_ SG_ 1095 MHU_SET_GameMode "Set Car in Game mode";
CM_ SG_ 1095 MHU_SET_KaraokeMode "Set Car in Karaoket mode";
CM_ SG_ 1095 MHU_Req_StoppingMode "Stopping mode request";
CM_ SG_ 1095 MHU_SET_WashMode "Set Car in Wash mode";
CM_ SG_ 1095 MHU_SET_StopMode "Set Car Stop mode";
CM_ SG_ 1095 MHU_AVH_Sw "Set Car Auto vehicle hold (AVH) mode";
CM_ SG_ 1110 OP_WISW_SZL_LIN "Wiper Status Signal (Right Stalk)
Bit 0~1 : Switch status on Automatic wiping, Wiper step 1, Wiper step 2 switch status
Bit 2: Not used.(this bit is always 0.)
Bit 3: Front mist switch status
Bit 4: Front washer switch status
Bit 5: Not used.(this bit is always 0.)
Bit 6: Rear wiping switch status
Bit 7: Rear washing switch status
* 1111 1111: Signal Invalid
";
CM_ SG_ 1110 COMM_ERR_SZL_LIN "This signal showes if there is or was a communication error.";
CM_ SG_ 1110 BCM_Wiper_Front_Status "Front Wiper Motor Feedback of status";
CM_ SG_ 1110 OP_WIPO_SZL_LIN "Wiper Step (Right Stalk)
0x0: Step 1
0x1: Step 2
0x2: Step 3
0x4: Step 4
0x7: signal invalid
";
CM_ SG_ 1110 OP_COLS_SZL_LIN "Left Stalk Lever Signal (Light function)
*the status of each bit follows this: (0: Off, 1: ON)
Bit 0: Highway flashing right indicator status
Bit 1: Flashing right indicator status
Bit 2: Highway flashing left indicator status
Bit 3: Flashing left indicator status
Bit 4: High-beam light status
Bit 5: High-beam light flashing status
Bit 6: Reserved
Bit 7: Not used.(this value is always ?0?)
* 1111 1111: Signal Invalid";
CM_ SG_ 1110 NOD_ERR_SZL_LIN "If SCM detects any error (any error status occurred), SCM sends this signal as ?error active?.";
CM_ SG_ 1110 BCM_Wiper_Rear_Status "Rear wiper status check";
CM_ SG_ 1110 ALIV_WISW_SZL_LIN "Standard Alive-counter for validation of the transmission between SCM and Master ECU.";

BA_DEF_ BO_  "GenMsgSendType" ENUM "Cyclic","NotUsed","NotUsed","NotUsed","NotUsed","NotUsed","NotUsed","IfActive","NoMsgSendType","NotUsed";
BA_DEF_ BO_  "GenMsgILSupport" ENUM "No","Yes";
BA_DEF_ BO_  "DiagResponse" ENUM "No","Yes";
BA_DEF_ BO_  "DiagRequest" ENUM "No","Yes";
BA_DEF_ BO_  "NmAsrMessage" ENUM "No","Yes";
BA_DEF_ BO_  "DiagState" ENUM "No","Yes";
BA_DEF_ BO_  "DiagUudtResponse" ENUM "False","True";
BA_DEF_ BO_  "GenMsgStartDelayTime" INT 0 65535;
BA_DEF_ BO_  "GenMsgDelayTime" INT 0 0;
BA_DEF_ BO_  "GenMsgNrOfRepetition" INT 0 0;
BA_DEF_ BO_  "GenMsgCycleTimeFast" INT 0 0;
BA_DEF_ BO_  "GenMsgCycleTime" INT 0 0;
BA_DEF_ SG_  "GenSigSendType" ENUM "Cyclic","OnWrite","OnWriteWithRepetition","OnChange","OnChangeWithRepetition","IfActive","IfActiveWithRepetition","NoSigSendType","NotUsed","NotUsed","NotUsed","NotUsed","NotUsed";
BA_DEF_ SG_  "InvalidValue" STRING;
BA_DEF_ SG_  "GenSigStartValue" INT 0 0;
BA_DEF_ SG_  "GenSigTimeoutTime_ALL" INT 0 65535;
BA_DEF_DEF_  "DiagRequest" "No";
BA_DEF_DEF_  "DiagResponse" "No";
BA_DEF_DEF_  "DiagState" "No";
BA_DEF_DEF_  "DiagUudtResponse" "False";
BA_DEF_DEF_  "GenMsgCycleTime" 0;
BA_DEF_DEF_  "GenMsgCycleTimeFast" 0;
BA_DEF_DEF_  "GenMsgDelayTime" 0;
BA_DEF_DEF_  "GenMsgILSupport" "Yes";
BA_DEF_DEF_  "GenMsgNrOfRepetition" 0;
BA_DEF_DEF_  "GenMsgSendType" "NoMsgSendType";
BA_DEF_DEF_  "GenMsgStartDelayTime" 0;
BA_DEF_DEF_  "GenSigSendType" "Cyclic";
BA_DEF_DEF_  "GenSigStartValue" 0;
BA_DEF_DEF_  "GenSigTimeoutTime_ALL" 0;
BA_DEF_DEF_  "NmAsrMessage" "No";
BA_ "GenMsgCycleTime" BO_ 568 50;
BA_ "GenMsgSendType" BO_ 568 0;
BA_ "GenMsgCycleTime" BO_ 569 50;
BA_ "GenMsgSendType" BO_ 569 0;
BA_ "GenMsgCycleTime" BO_ 570 20;
BA_ "GenMsgSendType" BO_ 570 0;
BA_ "GenMsgCycleTime" BO_ 571 20;
BA_ "GenMsgSendType" BO_ 571 0;
BA_ "GenMsgCycleTime" BO_ 572 20;
BA_ "GenMsgSendType" BO_ 572 0;
BA_ "GenMsgCycleTime" BO_ 573 10;
BA_ "GenMsgSendType" BO_ 573 0;
BA_ "GenMsgCycleTime" BO_ 574 20;
BA_ "GenMsgSendType" BO_ 574 0;
BA_ "GenMsgCycleTime" BO_ 581 200;
BA_ "GenMsgSendType" BO_ 581 0;
BA_ "GenMsgCycleTime" BO_ 585 100;
BA_ "GenMsgSendType" BO_ 585 0;
BA_ "GenMsgCycleTime" BO_ 596 20;
BA_ "GenMsgSendType" BO_ 596 0;
BA_ "GenMsgCycleTime" BO_ 597 20;
BA_ "GenMsgSendType" BO_ 597 0;
BA_ "GenMsgCycleTime" BO_ 608 20;
BA_ "GenMsgSendType" BO_ 608 0;
BA_ "GenMsgCycleTime" BO_ 609 100;
BA_ "GenMsgSendType" BO_ 609 0;
BA_ "GenMsgCycleTime" BO_ 610 100;
BA_ "GenMsgSendType" BO_ 610 0;
BA_ "GenMsgCycleTime" BO_ 680 20;
BA_ "GenMsgSendType" BO_ 680 0;
BA_ "GenMsgCycleTime" BO_ 681 20;
BA_ "GenMsgSendType" BO_ 681 0;
BA_ "GenMsgCycleTime" BO_ 714 100;
BA_ "GenMsgSendType" BO_ 714 0;
BA_ "GenMsgCycleTime" BO_ 720 100;
BA_ "GenMsgSendType" BO_ 720 0;
BA_ "GenMsgCycleTime" BO_ 760 1000;
BA_ "GenMsgSendType" BO_ 760 0;
BA_ "GenMsgCycleTime" BO_ 761 1000;
BA_ "GenMsgSendType" BO_ 761 0;
BA_ "GenMsgSendType" BO_ 768 0;
BA_ "GenMsgCycleTime" BO_ 768 1000;
BA_ "GenMsgCycleTimeFast" BO_ 768 20;
BA_ "GenMsgNrOfRepetition" BO_ 768 2;
BA_ "GenMsgCycleTime" BO_ 770 1000;
BA_ "GenMsgSendType" BO_ 770 0;
BA_ "GenMsgCycleTime" BO_ 773 100;
BA_ "GenMsgSendType" BO_ 773 0;
BA_ "GenMsgCycleTime" BO_ 774 100;
BA_ "GenMsgSendType" BO_ 774 0;
BA_ "GenMsgCycleTime" BO_ 787 100;
BA_ "GenMsgSendType" BO_ 787 0;
BA_ "GenMsgCycleTime" BO_ 803 100;
BA_ "GenMsgSendType" BO_ 803 0;
BA_ "GenMsgCycleTime" BO_ 806 100;
BA_ "GenMsgSendType" BO_ 806 0;
BA_ "GenMsgCycleTime" BO_ 807 100;
BA_ "GenMsgSendType" BO_ 807 0;
BA_ "GenMsgCycleTime" BO_ 816 100;
BA_ "GenMsgSendType" BO_ 816 0;
BA_ "GenMsgCycleTime" BO_ 838 100;
BA_ "GenMsgSendType" BO_ 838 0;
BA_ "GenMsgCycleTime" BO_ 840 50;
BA_ "GenMsgSendType" BO_ 840 0;
BA_ "GenMsgCycleTime" BO_ 841 50;
BA_ "GenMsgSendType" BO_ 841 0;
BA_ "GenMsgCycleTime" BO_ 870 500;
BA_ "GenMsgSendType" BO_ 870 0;
BA_ "GenMsgCycleTime" BO_ 885 50;
BA_ "GenMsgILSupport" BO_ 885 0;
BA_ "GenMsgSendType" BO_ 885 0;
BA_ "GenMsgCycleTime" BO_ 895 10;
BA_ "GenMsgSendType" BO_ 895 0;
BA_ "GenMsgCycleTime" BO_ 896 1000;
BA_ "GenMsgSendType" BO_ 896 0;
BA_ "GenMsgCycleTime" BO_ 897 200;
BA_ "GenMsgSendType" BO_ 897 0;
BA_ "GenMsgDelayTime" BO_ 905 10;
BA_ "GenMsgDelayTime" BO_ 920 10;
BA_ "GenMsgDelayTime" BO_ 921 10;
BA_ "GenMsgCycleTime" BO_ 937 100;
BA_ "GenMsgSendType" BO_ 937 0;
BA_ "GenMsgCycleTime" BO_ 992 20;
BA_ "GenMsgSendType" BO_ 992 0;
BA_ "GenMsgCycleTime" BO_ 993 100;
BA_ "GenMsgSendType" BO_ 993 0;
BA_ "GenMsgCycleTime" BO_ 1015 1000;
BA_ "GenMsgCycleTimeFast" BO_ 1015 50;
BA_ "GenMsgNrOfRepetition" BO_ 1015 3;
BA_ "GenMsgSendType" BO_ 1015 0;
BA_ "GenMsgCycleTime" BO_ 1027 100;
BA_ "GenMsgSendType" BO_ 1027 0;
BA_ "GenMsgCycleTimeFast" BO_ 1029 50;
BA_ "GenMsgNrOfRepetition" BO_ 1029 3;
BA_ "GenMsgCycleTime" BO_ 1037 120;
BA_ "GenMsgSendType" BO_ 1037 0;
BA_ "GenMsgCycleTime" BO_ 1074 500;
BA_ "GenMsgSendType" BO_ 1074 0;
BA_ "GenMsgCycleTime" BO_ 1079 100;
BA_ "GenMsgSendType" BO_ 1079 0;
BA_ "GenMsgCycleTime" BO_ 1080 100;
BA_ "GenMsgSendType" BO_ 1080 0;
BA_ "GenMsgCycleTime" BO_ 1081 100;
BA_ "GenMsgSendType" BO_ 1081 0;
BA_ "GenMsgCycleTime" BO_ 1082 100;
BA_ "GenMsgSendType" BO_ 1082 0;
BA_ "GenMsgCycleTime" BO_ 1083 100;
BA_ "GenMsgSendType" BO_ 1083 0;
BA_ "GenMsgCycleTime" BO_ 1084 100;
BA_ "GenMsgSendType" BO_ 1084 0;
BA_ "GenMsgCycleTime" BO_ 1093 100;
BA_ "GenMsgSendType" BO_ 1093 0;
BA_ "GenMsgCycleTime" BO_ 1095 200;
BA_ "GenMsgSendType" BO_ 1095 0;
BA_ "GenMsgSendType" BO_ 1139 0;
BA_ "GenMsgCycleTime" BO_ 1139 100;
BA_ "GenMsgSendType" BO_ 1140 0;
BA_ "GenMsgCycleTime" BO_ 1140 100;
BA_ "GenSigTimeoutTime_ALL" SG_ 568 CHSKM_EDS_curSts_FR 200;
BA_ "InvalidValue" SG_ 568 CHSKM_EDS_curSts_FR "";
BA_ "GenSigTimeoutTime_ALL" SG_ 568 ALV_EDS_curSts_FR 200;
BA_ "InvalidValue" SG_ 568 ALV_EDS_curSts_FR "Fh";
BA_ "GenSigTimeoutTime_ALL" SG_ 568 EDS_EPARK_STS_FWD 200;
BA_ "InvalidValue" SG_ 568 EDS_EPARK_STS_FWD "";
BA_ "GenSigTimeoutTime_ALL" SG_ 568 EDS_EPARK_ERR_FWD 200;
BA_ "InvalidValue" SG_ 568 EDS_EPARK_ERR_FWD "";
BA_ "GenSigTimeoutTime_ALL" SG_ 568 EDS_disxhg_st_FWD 200;
BA_ "InvalidValue" SG_ 568 EDS_disxhg_st_FWD "";
BA_ "GenSigTimeoutTime_ALL" SG_ 568 EDS_tempValid_FWD 200;
BA_ "InvalidValue" SG_ 568 EDS_tempValid_FWD "";
BA_ "GenSigTimeoutTime_ALL" SG_ 568 EDS_MotTemp_MEAS_EDS_valid_FWD 200;
BA_ "InvalidValue" SG_ 568 EDS_MotTemp_MEAS_EDS_valid_FWD "";
BA_ "GenSigTimeoutTime_ALL" SG_ 568 EDS_MotTemp_MEAS_EDS_FWD 200;
BA_ "InvalidValue" SG_ 568 EDS_MotTemp_MEAS_EDS_FWD "FFh";
BA_ "GenSigTimeoutTime_ALL" SG_ 568 EDS_temp_FWD 200;
BA_ "InvalidValue" SG_ 568 EDS_temp_FWD "FFh";
BA_ "GenSigTimeoutTime_ALL" SG_ 568 EDS_CoolFlowrate_DMD_FWD 200;
BA_ "InvalidValue" SG_ 568 EDS_CoolFlowrate_DMD_FWD "FFh";
BA_ "GenSigTimeoutTime_ALL" SG_ 568 EDS_ActiveHeating_state 200;
BA_ "InvalidValue" SG_ 568 EDS_ActiveHeating_state "";
BA_ "GenSigTimeoutTime_ALL" SG_ 568 EDS_DampingState_FWD 200;
BA_ "InvalidValue" SG_ 568 EDS_DampingState_FWD "";
BA_ "GenSigTimeoutTime_ALL" SG_ 568 EDS_IGBTState_FWD 200;
BA_ "InvalidValue" SG_ 568 EDS_IGBTState_FWD "";
BA_ "GenSigTimeoutTime_ALL" SG_ 569 CHSKM_EDS_curSts_RR 200;
BA_ "InvalidValue" SG_ 569 CHSKM_EDS_curSts_RR "";
BA_ "GenSigTimeoutTime_ALL" SG_ 569 ALV_EDS_curSts_RR 200;
BA_ "InvalidValue" SG_ 569 ALV_EDS_curSts_RR "Fh";
BA_ "GenSigTimeoutTime_ALL" SG_ 569 EDS_disxhg_st_RWD 200;
BA_ "InvalidValue" SG_ 569 EDS_disxhg_st_RWD "";
BA_ "GenSigTimeoutTime_ALL" SG_ 569 EDS_tempValid_RWD 200;
BA_ "InvalidValue" SG_ 569 EDS_tempValid_RWD "";
BA_ "GenSigTimeoutTime_ALL" SG_ 569 EDS_MotTemp_MEAS_EDS_valid_RWD 200;
BA_ "InvalidValue" SG_ 569 EDS_MotTemp_MEAS_EDS_valid_RWD "";
BA_ "GenSigTimeoutTime_ALL" SG_ 569 EDS_MotTemp_MEAS_EDS_RWD 200;
BA_ "InvalidValue" SG_ 569 EDS_MotTemp_MEAS_EDS_RWD "FFh";
BA_ "GenSigTimeoutTime_ALL" SG_ 569 EDS_temp_RWD 200;
BA_ "InvalidValue" SG_ 569 EDS_temp_RWD "FFh";
BA_ "GenSigTimeoutTime_ALL" SG_ 569 EDS_CoolFlowrate_DMD_RWD 200;
BA_ "InvalidValue" SG_ 569 EDS_CoolFlowrate_DMD_RWD "FFh";
BA_ "GenSigTimeoutTime_ALL" SG_ 569 EDS_DampingState_RWD 200;
BA_ "InvalidValue" SG_ 569 EDS_DampingState_RWD "";
BA_ "GenSigTimeoutTime_ALL" SG_ 569 EDS_IGBTState_RWD 200;
BA_ "InvalidValue" SG_ 569 EDS_IGBTState_RWD "";
BA_ "GenSigTimeoutTime_ALL" SG_ 570 CHKSM_IDB_WheelSts_FR 200;
BA_ "InvalidValue" SG_ 570 CHKSM_IDB_WheelSts_FR "";
BA_ "GenSigTimeoutTime_ALL" SG_ 570 ALV_IDB_WheelSts_FR 200;
BA_ "InvalidValue" SG_ 570 ALV_IDB_WheelSts_FR "Fh";
BA_ "GenSigTimeoutTime_ALL" SG_ 570 IDB_WheelDirection_FR 200;
BA_ "InvalidValue" SG_ 570 IDB_WheelDirection_FR "3h";
BA_ "GenSigTimeoutTime_ALL" SG_ 570 IDB_WheelDirection_FL 200;
BA_ "InvalidValue" SG_ 570 IDB_WheelDirection_FL "3h";
BA_ "GenSigTimeoutTime_ALL" SG_ 570 IDB_WheelSpeedRC_FL 200;
BA_ "InvalidValue" SG_ 570 IDB_WheelSpeedRC_FL "FFFEh";
BA_ "GenSigTimeoutTime_ALL" SG_ 570 IDB_WheelSpeedRC_FR 200;
BA_ "InvalidValue" SG_ 570 IDB_WheelSpeedRC_FR "FFFEh";
BA_ "GenSigTimeoutTime_ALL" SG_ 571 CHKSM_IDB_WheelSts_RR 200;
BA_ "InvalidValue" SG_ 571 CHKSM_IDB_WheelSts_RR "";
BA_ "GenSigTimeoutTime_ALL" SG_ 571 ALV_IDB_WheelSts_RR 200;
BA_ "InvalidValue" SG_ 571 ALV_IDB_WheelSts_RR "Fh";
BA_ "GenSigTimeoutTime_ALL" SG_ 571 IDB_WheelDirection_RR 200;
BA_ "InvalidValue" SG_ 571 IDB_WheelDirection_RR "3h";
BA_ "GenSigTimeoutTime_ALL" SG_ 571 IDB_WheelDirection_RL 200;
BA_ "InvalidValue" SG_ 571 IDB_WheelDirection_RL "3h";
BA_ "GenSigTimeoutTime_ALL" SG_ 571 IDB_WheelSpeedRC_RL 200;
BA_ "InvalidValue" SG_ 571 IDB_WheelSpeedRC_RL "FFFEh";
BA_ "GenSigTimeoutTime_ALL" SG_ 571 IDB_WheelSpeedRC_RR 200;
BA_ "InvalidValue" SG_ 571 IDB_WheelSpeedRC_RR "FFFEh";
BA_ "GenSigTimeoutTime_ALL" SG_ 572 CHKSM_IDB_BrkPdl 200;
BA_ "InvalidValue" SG_ 572 CHKSM_IDB_BrkPdl "";
BA_ "GenSigTimeoutTime_ALL" SG_ 572 ALV_IDB_BrkPdl 200;
BA_ "InvalidValue" SG_ 572 ALV_IDB_BrkPdl "Fh";
BA_ "GenSigTimeoutTime_ALL" SG_ 572 IDB_DPBAvlSts 200;
BA_ "InvalidValue" SG_ 572 IDB_DPBAvlSts "1h";
BA_ "GenSigTimeoutTime_ALL" SG_ 572 IDB_ReqApplyEPBVldtn 200;
BA_ "InvalidValue" SG_ 572 IDB_ReqApplyEPBVldtn "1h";
BA_ "GenSigTimeoutTime_ALL" SG_ 572 IDB_ReqApplyEPB 200;
BA_ "InvalidValue" SG_ 572 IDB_ReqApplyEPB "";
BA_ "GenSigTimeoutTime_ALL" SG_ 572 IDB_DiagMode 200;
BA_ "InvalidValue" SG_ 572 IDB_DiagMode "";
BA_ "GenSigTimeoutTime_ALL" SG_ 572 IDB_DPBActvSts 200;
BA_ "InvalidValue" SG_ 572 IDB_DPBActvSts "";
BA_ "GenSigTimeoutTime_ALL" SG_ 572 IDB_CircPres 200;
BA_ "InvalidValue" SG_ 572 IDB_CircPres "";
BA_ "GenSigTimeoutTime_ALL" SG_ 572 IDB_CircPresVldty 200;
BA_ "InvalidValue" SG_ 572 IDB_CircPresVldty "1h";
BA_ "GenSigTimeoutTime_ALL" SG_ 572 IDB_BrkPedlVal 200;
BA_ "InvalidValue" SG_ 572 IDB_BrkPedlVal "";
BA_ "GenSigTimeoutTime_ALL" SG_ 572 IDB_BrkPedlValVldty 200;
BA_ "InvalidValue" SG_ 572 IDB_BrkPedlValVldty "1h";
BA_ "GenSigTimeoutTime_ALL" SG_ 573 IDB_FrntLeEstimdWhlPres 100;
BA_ "InvalidValue" SG_ 573 IDB_FrntLeEstimdWhlPres "";
BA_ "GenSigTimeoutTime_ALL" SG_ 573 IDB_FrntLeEstimdWhlPresVldty 100;
BA_ "InvalidValue" SG_ 573 IDB_FrntLeEstimdWhlPresVldty "1h";
BA_ "GenSigTimeoutTime_ALL" SG_ 573 IDB_FrntRiEstimdWhlPres 100;
BA_ "InvalidValue" SG_ 573 IDB_FrntRiEstimdWhlPres "";
BA_ "GenSigTimeoutTime_ALL" SG_ 573 IDB_FrntRiEstimdWhlPresVldty 100;
BA_ "InvalidValue" SG_ 573 IDB_FrntRiEstimdWhlPresVldty "1h";
BA_ "GenSigTimeoutTime_ALL" SG_ 573 IDB_ReLeEstimdWhlPres 100;
BA_ "InvalidValue" SG_ 573 IDB_ReLeEstimdWhlPres "";
BA_ "GenSigTimeoutTime_ALL" SG_ 573 IDB_ReLeEstimdWhlPresVldty 100;
BA_ "InvalidValue" SG_ 573 IDB_ReLeEstimdWhlPresVldty "1h";
BA_ "GenSigTimeoutTime_ALL" SG_ 573 IDB_ReRiEstimdWhlPres 100;
BA_ "InvalidValue" SG_ 573 IDB_ReRiEstimdWhlPres "";
BA_ "GenSigTimeoutTime_ALL" SG_ 573 IDB_ReRiEstimdWhlPresVldty 100;
BA_ "InvalidValue" SG_ 573 IDB_ReRiEstimdWhlPresVldty "1h";
BA_ "GenSigTimeoutTime_ALL" SG_ 574 CHKSM_RCU_EPB_Sts 200;
BA_ "InvalidValue" SG_ 574 CHKSM_RCU_EPB_Sts "";
BA_ "GenSigTimeoutTime_ALL" SG_ 574 ALV_RCU_EPB_Sts 200;
BA_ "InvalidValue" SG_ 574 ALV_RCU_EPB_Sts "Fh";
BA_ "GenSigTimeoutTime_ALL" SG_ 574 RCU_EPB_DynamicApplySta 200;
BA_ "InvalidValue" SG_ 574 RCU_EPB_DynamicApplySta "";
BA_ "GenSigTimeoutTime_ALL" SG_ 574 RCU_EPB_WarnLampSta 200;
BA_ "InvalidValue" SG_ 574 RCU_EPB_WarnLampSta "";
BA_ "GenSigTimeoutTime_ALL" SG_ 574 RCU_EPB_ParkLampSta 200;
BA_ "InvalidValue" SG_ 574 RCU_EPB_ParkLampSta "";
BA_ "GenSigTimeoutTime_ALL" SG_ 574 RCU_EPB_SwitchSta 200;
BA_ "InvalidValue" SG_ 574 RCU_EPB_SwitchSta "3h";
BA_ "GenSigTimeoutTime_ALL" SG_ 574 RCU_EPB_DecelReqSts 200;
BA_ "InvalidValue" SG_ 574 RCU_EPB_DecelReqSts "";
BA_ "GenSigTimeoutTime_ALL" SG_ 574 RCU_EPB_SystemState 200;
BA_ "InvalidValue" SG_ 574 RCU_EPB_SystemState "0h";
BA_ "GenSigTimeoutTime_ALL" SG_ 574 RCU_EPB_DecelReq 200;
BA_ "InvalidValue" SG_ 574 RCU_EPB_DecelReq "";
BA_ "GenSigTimeoutTime_ALL" SG_ 574 RCU_PBCInApplyRelsReq 200;
BA_ "InvalidValue" SG_ 574 RCU_PBCInApplyRelsReq "";
BA_ "GenSigTimeoutTime_ALL" SG_ 574 RCU_PBCRollrBenchActv 200;
BA_ "InvalidValue" SG_ 574 RCU_PBCRollrBenchActv "";
BA_ "GenSigTimeoutTime_ALL" SG_ 574 RCU_EPB_FltSts 200;
BA_ "InvalidValue" SG_ 574 RCU_EPB_FltSts "5h";
BA_ "GenSigTimeoutTime_ALL" SG_ 574 RCU_ReqBrkLiOn 200;
BA_ "InvalidValue" SG_ 574 RCU_ReqBrkLiOn "";
BA_ "GenSigTimeoutTime_ALL" SG_ 581 Checksum_0x245 200;
BA_ "InvalidValue" SG_ 581 Checksum_0x245 "";
BA_ "GenSigTimeoutTime_ALL" SG_ 581 Rolling_Counter_0x245 200;
BA_ "InvalidValue" SG_ 581 Rolling_Counter_0x245 "Fh";
BA_ "GenSigStartValue" SG_ 581 BMS_ProbeNumMaxCellTemp 1;
BA_ "GenSigTimeoutTime_ALL" SG_ 581 BMS_ProbeNumMaxCellTemp 200;
BA_ "InvalidValue" SG_ 581 BMS_ProbeNumMaxCellTemp "";
BA_ "GenSigStartValue" SG_ 581 BMS_MinCellTemp 80;
BA_ "GenSigTimeoutTime_ALL" SG_ 581 BMS_MinCellTemp 200;
BA_ "InvalidValue" SG_ 581 BMS_MinCellTemp "FFh";
BA_ "GenSigTimeoutTime_ALL" SG_ 581 BMS_ProbeNumMinCellTemp 200;
BA_ "InvalidValue" SG_ 581 BMS_ProbeNumMinCellTemp "";
BA_ "GenSigStartValue" SG_ 581 BMS_PackTemp 80;
BA_ "GenSigTimeoutTime_ALL" SG_ 581 BMS_PackTemp 200;
BA_ "InvalidValue" SG_ 581 BMS_PackTemp "FFh";
BA_ "GenSigStartValue" SG_ 581 BMS_MaxCellTemp 80;
BA_ "GenSigTimeoutTime_ALL" SG_ 581 BMS_MaxCellTemp 200;
BA_ "InvalidValue" SG_ 581 BMS_MaxCellTemp "FFh";
BA_ "GenSigStartValue" SG_ 581 BMS_MaxMinDiffCellTemp 80;
BA_ "GenSigTimeoutTime_ALL" SG_ 581 BMS_MaxMinDiffCellTemp 200;
BA_ "InvalidValue" SG_ 581 BMS_MaxMinDiffCellTemp "FFh";
BA_ "GenSigTimeoutTime_ALL" SG_ 585 CHSKM_BMS_CoolntInletOutletTmp 500;
BA_ "InvalidValue" SG_ 585 CHSKM_BMS_CoolntInletOutletTmp "";
BA_ "GenSigTimeoutTime_ALL" SG_ 585 ALV_BMS_CoolntInletOutletTmp 500;
BA_ "InvalidValue" SG_ 585 ALV_BMS_CoolntInletOutletTmp "Fh";
BA_ "GenSigStartValue" SG_ 585 BMS_CoolantInletTemp 80;
BA_ "GenSigTimeoutTime_ALL" SG_ 585 BMS_CoolantInletTemp 500;
BA_ "InvalidValue" SG_ 585 BMS_CoolantInletTemp "";
BA_ "GenSigStartValue" SG_ 585 BMS_CoolantOutletTemp 80;
BA_ "GenSigTimeoutTime_ALL" SG_ 585 BMS_CoolantOutletTemp 500;
BA_ "InvalidValue" SG_ 585 BMS_CoolantOutletTemp "";
BA_ "GenSigTimeoutTime_ALL" SG_ 596 CRC_AVL_RPM_WHL_REAR 200;
BA_ "InvalidValue" SG_ 596 CRC_AVL_RPM_WHL_REAR "";
BA_ "GenSigTimeoutTime_ALL" SG_ 596 ALIV_AVL_RPM_WHL_REAR 200;
BA_ "InvalidValue" SG_ 596 ALIV_AVL_RPM_WHL_REAR "Fh";
BA_ "GenSigStartValue" SG_ 596 AVL_RPM_WHL_RLH 32819;
BA_ "GenSigTimeoutTime_ALL" SG_ 596 AVL_RPM_WHL_RLH 200;
BA_ "InvalidValue" SG_ 596 AVL_RPM_WHL_RLH "0";
BA_ "GenSigStartValue" SG_ 596 AVL_RPM_WHL_RRH 32819;
BA_ "GenSigTimeoutTime_ALL" SG_ 596 AVL_RPM_WHL_RRH 200;
BA_ "InvalidValue" SG_ 596 AVL_RPM_WHL_RRH "0";
BA_ "GenSigTimeoutTime_ALL" SG_ 596 QU_AVL_RPM_WHL_RLH 200;
BA_ "InvalidValue" SG_ 596 QU_AVL_RPM_WHL_RLH "Fh";
BA_ "GenSigTimeoutTime_ALL" SG_ 596 QU_AVL_RPM_WHL_RRH 200;
BA_ "InvalidValue" SG_ 596 QU_AVL_RPM_WHL_RRH "Fh";
BA_ "GenSigTimeoutTime_ALL" SG_ 597 CRC_AVL_RPM_WHL_FRONT 200;
BA_ "InvalidValue" SG_ 597 CRC_AVL_RPM_WHL_FRONT "";
BA_ "GenSigTimeoutTime_ALL" SG_ 597 ALIV_AVL_RPM_WHL_FRONT 200;
BA_ "InvalidValue" SG_ 597 ALIV_AVL_RPM_WHL_FRONT "Fh";
BA_ "GenSigStartValue" SG_ 597 AVL_RPM_WHL_FLH 32819;
BA_ "GenSigTimeoutTime_ALL" SG_ 597 AVL_RPM_WHL_FLH 200;
BA_ "InvalidValue" SG_ 597 AVL_RPM_WHL_FLH "0";
BA_ "GenSigStartValue" SG_ 597 AVL_RPM_WHL_FRH 32819;
BA_ "GenSigTimeoutTime_ALL" SG_ 597 AVL_RPM_WHL_FRH 200;
BA_ "InvalidValue" SG_ 597 AVL_RPM_WHL_FRH "0";
BA_ "GenSigTimeoutTime_ALL" SG_ 597 QU_AVL_RPM_WHL_FLH 200;
BA_ "InvalidValue" SG_ 597 QU_AVL_RPM_WHL_FLH "Fh";
BA_ "GenSigTimeoutTime_ALL" SG_ 597 QU_AVL_RPM_WHL_FRH 200;
BA_ "InvalidValue" SG_ 597 QU_AVL_RPM_WHL_FRH "Fh";
BA_ "GenSigTimeoutTime_ALL" SG_ 608 CRC_VCU_Wheel_Torque_Status 200;
BA_ "GenSigTimeoutTime_ALL" SG_ 608 ALIV_VCU_Wheel_Torque_Status 200;
BA_ "InvalidValue" SG_ 608 ALIV_VCU_Wheel_Torque_Status "Fh";
BA_ "GenSigTimeoutTime_ALL" SG_ 608 VCU_Available_Wheel_Torque 200;
BA_ "InvalidValue" SG_ 608 VCU_Available_Wheel_Torque "";
BA_ "GenSigTimeoutTime_ALL" SG_ 608 SECCAN_VCU_Wheel_Torq_Sts 200;
BA_ "InvalidValue" SG_ 608 SECCAN_VCU_Wheel_Torq_Sts "";
BA_ "GenSigTimeoutTime_ALL" SG_ 609 CHSKM_VCU_POD_reqCharge 500;
BA_ "InvalidValue" SG_ 609 CHSKM_VCU_POD_reqCharge "";
BA_ "GenSigTimeoutTime_ALL" SG_ 609 ALV_VCU_POD_reqCharge 500;
BA_ "InvalidValue" SG_ 609 ALV_VCU_POD_reqCharge "Fh";
BA_ "GenSigTimeoutTime_ALL" SG_ 609 VCU_enableFC 500;
BA_ "InvalidValue" SG_ 609 VCU_enableFC "";
BA_ "GenSigTimeoutTime_ALL" SG_ 609 VCU_enableOBC 500;
BA_ "InvalidValue" SG_ 609 VCU_enableOBC "7h";
BA_ "GenSigTimeoutTime_ALL" SG_ 609 VCU_iLineLimit 500;
BA_ "InvalidValue" SG_ 609 VCU_iLineLimit "FFFFh";
BA_ "GenSigTimeoutTime_ALL" SG_ 609 VCU_iOBCRequest 500;
BA_ "InvalidValue" SG_ 609 VCU_iOBCRequest "FFFFh";
BA_ "GenSigStartValue" SG_ 609 VCU_vOBCRequest 6080;
BA_ "GenSigTimeoutTime_ALL" SG_ 609 VCU_vOBCRequest 500;
BA_ "InvalidValue" SG_ 609 VCU_vOBCRequest "FFFFh";
BA_ "GenSigTimeoutTime_ALL" SG_ 610 CHSKM_VCU_POD_info 500;
BA_ "InvalidValue" SG_ 610 CHSKM_VCU_POD_info "";
BA_ "GenSigTimeoutTime_ALL" SG_ 610 ALV_VCU_POD_info 500;
BA_ "InvalidValue" SG_ 610 ALV_VCU_POD_info "Fh";
BA_ "GenSigTimeoutTime_ALL" SG_ 610 BMS_statusHVIL 500;
BA_ "InvalidValue" SG_ 610 BMS_statusHVIL "";
BA_ "GenSigTimeoutTime_ALL" SG_ 610 BMS_iPack 500;
BA_ "InvalidValue" SG_ 610 BMS_iPack "";
BA_ "GenSigStartValue" SG_ 610 THM_tempCoolantInletEMU 40;
BA_ "GenSigTimeoutTime_ALL" SG_ 610 THM_tempCoolantInletEMU 500;
BA_ "InvalidValue" SG_ 610 THM_tempCoolantInletEMU "";
BA_ "GenSigTimeoutTime_ALL" SG_ 610 THM_pwmPumpOBC 500;
BA_ "InvalidValue" SG_ 610 THM_pwmPumpOBC "";
BA_ "GenSigTimeoutTime_ALL" SG_ 680 CHSKM_EDS_Power_FR 200;
BA_ "InvalidValue" SG_ 680 CHSKM_EDS_Power_FR "";
BA_ "GenSigTimeoutTime_ALL" SG_ 680 ALV_EDS_Power_FR 200;
BA_ "InvalidValue" SG_ 680 ALV_EDS_Power_FR "Fh";
BA_ "GenSigStartValue" SG_ 680 EDS_MotorSerialNum_FWD 1;
BA_ "GenSigTimeoutTime_ALL" SG_ 680 EDS_MotorSerialNum_FWD 200;
BA_ "InvalidValue" SG_ 680 EDS_MotorSerialNum_FWD "0h";
BA_ "GenSigTimeoutTime_ALL" SG_ 680 EDS_MaxTrq_FWD 200;
BA_ "InvalidValue" SG_ 680 EDS_MaxTrq_FWD "FFFFh";
BA_ "GenSigTimeoutTime_ALL" SG_ 680 EDS_MinTrq_FWD 200;
BA_ "InvalidValue" SG_ 680 EDS_MinTrq_FWD "FFFFh";
BA_ "GenSigTimeoutTime_ALL" SG_ 681 CHSKM_EDS_R_Power_RR 200;
BA_ "InvalidValue" SG_ 681 CHSKM_EDS_R_Power_RR "";
BA_ "GenSigTimeoutTime_ALL" SG_ 681 ALV_EDS_R_Power_RR 200;
BA_ "InvalidValue" SG_ 681 ALV_EDS_R_Power_RR "Fh";
BA_ "GenSigStartValue" SG_ 681 EDS_MotorSerialNum_RWD 1;
BA_ "GenSigTimeoutTime_ALL" SG_ 681 EDS_MotorSerialNum_RWD 200;
BA_ "InvalidValue" SG_ 681 EDS_MotorSerialNum_RWD "0h";
BA_ "GenSigTimeoutTime_ALL" SG_ 681 EDS_MaxTrq_RWD 200;
BA_ "InvalidValue" SG_ 681 EDS_MaxTrq_RWD "FFFFh";
BA_ "GenSigTimeoutTime_ALL" SG_ 681 EDS_MinTrq_RWD 200;
BA_ "InvalidValue" SG_ 681 EDS_MinTrq_RWD "FFFFh";
BA_ "GenSigTimeoutTime_ALL" SG_ 714 CHKSM_IC_SENSOR 500;
BA_ "InvalidValue" SG_ 714 CHKSM_IC_SENSOR "";
BA_ "GenSigTimeoutTime_ALL" SG_ 714 ALV_IC_SENSOR 500;
BA_ "InvalidValue" SG_ 714 ALV_IC_SENSOR "Fh";
BA_ "GenSigStartValue" SG_ 714 MHU_STAT_AmbientTempRaw 80;
BA_ "GenSigTimeoutTime_ALL" SG_ 714 MHU_STAT_AmbientTempRaw 500;
BA_ "InvalidValue" SG_ 714 MHU_STAT_AmbientTempRaw "FFh";
BA_ "GenSigTimeoutTime_ALL" SG_ 714 MHU_STAT_FuelLevel 500;
BA_ "InvalidValue" SG_ 714 MHU_STAT_FuelLevel "FFh";
BA_ "GenSigStartValue" SG_ 714 MHU_STAT_AmbientTemp 80;
BA_ "GenSigTimeoutTime_ALL" SG_ 714 MHU_STAT_AmbientTemp 500;
BA_ "InvalidValue" SG_ 714 MHU_STAT_AmbientTemp "FFh";
BA_ "GenSigTimeoutTime_ALL" SG_ 714 MHU_STAT_CoolantLevelStatus 500;
BA_ "InvalidValue" SG_ 714 MHU_STAT_CoolantLevelStatus "3h";
BA_ "GenSigTimeoutTime_ALL" SG_ 720 CHKSM_FCAM_AESA_Sts 500;
BA_ "InvalidValue" SG_ 720 ALV_FCAM_AESA_Sts "Fh";
BA_ "GenSigTimeoutTime_ALL" SG_ 720 ALV_FCAM_AESA_Sts 500;
BA_ "GenSigTimeoutTime_ALL" SG_ 720 FCAM_AESA_DoorUnlock_Req 500;
BA_ "GenSigTimeoutTime_ALL" SG_ 720 FCAM_AESA_ECALL_Req 500;
BA_ "GenSigTimeoutTime_ALL" SG_ 720 FCAM_AESA_Status 500;
BA_ "GenSigTimeoutTime_ALL" SG_ 760 DISP_HR 5000;
BA_ "InvalidValue" SG_ 760 DISP_HR "FFh";
BA_ "GenSigTimeoutTime_ALL" SG_ 760 DISP_MN 5000;
BA_ "InvalidValue" SG_ 760 DISP_MN "FFh";
BA_ "GenSigTimeoutTime_ALL" SG_ 760 DISP_SEC 5000;
BA_ "InvalidValue" SG_ 760 DISP_SEC "FFh";
BA_ "GenSigStartValue" SG_ 760 DISP_DATE_DAY 1;
BA_ "GenSigTimeoutTime_ALL" SG_ 760 DISP_DATE_DAY 5000;
BA_ "InvalidValue" SG_ 760 DISP_DATE_DAY "FFh";
BA_ "GenSigStartValue" SG_ 760 DISP_DATE_MON 1;
BA_ "GenSigTimeoutTime_ALL" SG_ 760 DISP_DATE_MON 5000;
BA_ "InvalidValue" SG_ 760 DISP_DATE_MON "Fh";
BA_ "GenSigTimeoutTime_ALL" SG_ 760 DISP_DATE_WDAY 5000;
BA_ "InvalidValue" SG_ 760 DISP_DATE_WDAY "Fh";
BA_ "GenSigStartValue" SG_ 760 DISP_DATE_YR 1;
BA_ "GenSigTimeoutTime_ALL" SG_ 760 DISP_DATE_YR 5000;
BA_ "InvalidValue" SG_ 760 DISP_DATE_YR "FFFFh";
BA_ "GenSigTimeoutTime_ALL" SG_ 760 ST_DISP_CTI_DATE 5000;
BA_ "InvalidValue" SG_ 760 ST_DISP_CTI_DATE "Fh";
BA_ "GenSigTimeoutTime_ALL" SG_ 761 DISP_HR_UTC 5000;
BA_ "InvalidValue" SG_ 761 DISP_HR_UTC "FFh";
BA_ "GenSigTimeoutTime_ALL" SG_ 761 DISP_MN_UTC 5000;
BA_ "InvalidValue" SG_ 761 DISP_MN_UTC "FFh";
BA_ "GenSigTimeoutTime_ALL" SG_ 761 DISP_SEC_UTC 5000;
BA_ "InvalidValue" SG_ 761 DISP_SEC_UTC "FFh";
BA_ "GenSigStartValue" SG_ 761 DISP_DATE_DAY_UTC 1;
BA_ "GenSigTimeoutTime_ALL" SG_ 761 DISP_DATE_DAY_UTC 5000;
BA_ "InvalidValue" SG_ 761 DISP_DATE_DAY_UTC "FFh";
BA_ "GenSigStartValue" SG_ 761 DISP_DATE_MON_UTC 1;
BA_ "GenSigTimeoutTime_ALL" SG_ 761 DISP_DATE_MON_UTC 5000;
BA_ "InvalidValue" SG_ 761 DISP_DATE_MON_UTC "Fh";
BA_ "GenSigStartValue" SG_ 761 DISP_DATE_YR_UTC 1;
BA_ "GenSigTimeoutTime_ALL" SG_ 761 DISP_DATE_YR_UTC 5000;
BA_ "InvalidValue" SG_ 761 DISP_DATE_YR_UTC "FFFFh";
BA_ "GenSigSendType" SG_ 768 CCU_STAT_SyncClimateZone 4;
BA_ "InvalidValue" SG_ 768 CCU_STAT_SyncClimateZone "3h";
BA_ "GenSigSendType" SG_ 768 CCU_STAT_Auto 4;
BA_ "InvalidValue" SG_ 768 CCU_STAT_Auto "3h";
BA_ "GenSigSendType" SG_ 768 CCU_STAT_Aircondition 4;
BA_ "InvalidValue" SG_ 768 CCU_STAT_Aircondition "3h";
BA_ "GenSigSendType" SG_ 768 CCU_STAT_IonButton 4;
BA_ "InvalidValue" SG_ 768 CCU_STAT_IonButton "3h";
BA_ "GenSigSendType" SG_ 768 CCU_STAT_MaxAc 4;
BA_ "InvalidValue" SG_ 768 CCU_STAT_MaxAc "3h";
BA_ "GenSigSendType" SG_ 768 CCU_STAT_OnOff 4;
BA_ "GenSigStartValue" SG_ 768 CCU_STAT_OnOff 3;
BA_ "InvalidValue" SG_ 768 CCU_STAT_OnOff "3h";
BA_ "GenSigSendType" SG_ 768 CCU_STAT_FanSpeed 4;
BA_ "InvalidValue" SG_ 768 CCU_STAT_FanSpeed "Fh";
BA_ "GenSigSendType" SG_ 768 CCU_STAT_RecircFlap 4;
BA_ "GenSigStartValue" SG_ 768 CCU_STAT_RecircFlap 1;
BA_ "InvalidValue" SG_ 768 CCU_STAT_RecircFlap "3h";
BA_ "GenSigSendType" SG_ 768 CCU_STAT_FlapPos 4;
BA_ "InvalidValue" SG_ 768 CCU_STAT_FlapPos "7h";
BA_ "GenSigSendType" SG_ 768 CCU_STAT_Defrost 4;
BA_ "InvalidValue" SG_ 768 CCU_STAT_Defrost "3h";
BA_ "GenSigSendType" SG_ 768 CCU_STAT_PTC_Heater 4;
BA_ "InvalidValue" SG_ 768 CCU_STAT_PTC_Heater "7h";
BA_ "GenSigSendType" SG_ 768 CCU_STAT_TempDriver 4;
BA_ "GenSigStartValue" SG_ 768 CCU_STAT_TempDriver 40;
BA_ "InvalidValue" SG_ 768 CCU_STAT_TempDriver "FFh";
BA_ "GenSigSendType" SG_ 768 CCU_STAT_TempPassenger 4;
BA_ "GenSigStartValue" SG_ 768 CCU_STAT_TempPassenger 40;
BA_ "InvalidValue" SG_ 768 CCU_STAT_TempPassenger "FFh";
BA_ "GenSigTimeoutTime_ALL" SG_ 770 CHKSM_CCU_TEMP_PRESSURE 5000;
BA_ "InvalidValue" SG_ 770 CHKSM_CCU_TEMP_PRESSURE "";
BA_ "GenSigTimeoutTime_ALL" SG_ 770 ALV_CCU_TEMP_PRESSURE 5000;
BA_ "InvalidValue" SG_ 770 ALV_CCU_TEMP_PRESSURE "Fh";
BA_ "GenSigTimeoutTime_ALL" SG_ 770 CCU_Pressure_AC 5000;
BA_ "InvalidValue" SG_ 770 CCU_Pressure_AC "3Fh";
BA_ "GenSigStartValue" SG_ 770 CCU_InteriorTemp 80;
BA_ "GenSigTimeoutTime_ALL" SG_ 770 CCU_InteriorTemp 5000;
BA_ "InvalidValue" SG_ 770 CCU_InteriorTemp "FFh";
BA_ "GenSigStartValue" SG_ 770 CCU_TempEx_AC 80;
BA_ "GenSigTimeoutTime_ALL" SG_ 770 CCU_TempEx_AC 5000;
BA_ "InvalidValue" SG_ 770 CCU_TempEx_AC "FFh";
BA_ "GenSigStartValue" SG_ 770 CCU_EvaporatorTemp 80;
BA_ "GenSigTimeoutTime_ALL" SG_ 770 CCU_EvaporatorTemp 5000;
BA_ "InvalidValue" SG_ 770 CCU_EvaporatorTemp "FFh";
BA_ "GenSigStartValue" SG_ 773 HtrMediumOutletTemp 80;
BA_ "GenSigTimeoutTime_ALL" SG_ 773 HtrMediumOutletTemp 500;
BA_ "InvalidValue" SG_ 773 HtrMediumOutletTemp "1FFh";
BA_ "GenSigTimeoutTime_ALL" SG_ 773 CcuHtrOnOffSts 500;
BA_ "InvalidValue" SG_ 773 CcuHtrOnOffSts "7h";
BA_ "GenSigTimeoutTime_ALL" SG_ 773 EcompOnOffSts 500;
BA_ "InvalidValue" SG_ 773 EcompOnOffSts "3h";
BA_ "GenSigStartValue" SG_ 773 HtrMediumInletTemp 80;
BA_ "GenSigTimeoutTime_ALL" SG_ 773 HtrMediumInletTemp 500;
BA_ "InvalidValue" SG_ 773 HtrMediumInletTemp "1FFh";
BA_ "GenSigTimeoutTime_ALL" SG_ 773 ECompRpm 500;
BA_ "InvalidValue" SG_ 773 ECompRpm "FFFFh";
BA_ "GenSigTimeoutTime_ALL" SG_ 773 ECompPowerConsumption 500;
BA_ "InvalidValue" SG_ 773 ECompPowerConsumption "";
BA_ "GenSigTimeoutTime_ALL" SG_ 774 CCU_EcompOnOffRequest 500;
BA_ "InvalidValue" SG_ 774 CCU_EcompOnOffRequest "3h";
BA_ "GenSigTimeoutTime_ALL" SG_ 774 CCU_HtrOnOffRequest 500;
BA_ "InvalidValue" SG_ 774 CCU_HtrOnOffRequest "3h";
BA_ "GenSigTimeoutTime_ALL" SG_ 774 CCU_AcOffCode_CCU 500;
BA_ "InvalidValue" SG_ 774 CCU_AcOffCode_CCU "FFh";
BA_ "GenSigTimeoutTime_ALL" SG_ 774 CCU_CoolPowerDemand 500;
BA_ "InvalidValue" SG_ 774 CCU_CoolPowerDemand "FFh";
BA_ "GenSigTimeoutTime_ALL" SG_ 774 CCU_HeatPowerDemand 500;
BA_ "InvalidValue" SG_ 774 CCU_HeatPowerDemand "FFh";
BA_ "GenSigTimeoutTime_ALL" SG_ 774 CCU_PTCOffCode_CCU 500;
BA_ "InvalidValue" SG_ 774 CCU_PTCOffCode_CCU "FFh";
BA_ "GenSigTimeoutTime_ALL" SG_ 774 CCU_CoolDemand 500;
BA_ "InvalidValue" SG_ 774 CCU_CoolDemand "FFh";
BA_ "GenSigTimeoutTime_ALL" SG_ 774 CCU_HeatDemand 500;
BA_ "InvalidValue" SG_ 774 CCU_HeatDemand "FFh";
BA_ "GenSigTimeoutTime_ALL" SG_ 787 CHSKM_POD_StatusCharger1 500;
BA_ "InvalidValue" SG_ 787 CHSKM_POD_StatusCharger1 "";
BA_ "GenSigTimeoutTime_ALL" SG_ 787 ALV_POD_StatusCharger1 500;
BA_ "InvalidValue" SG_ 787 ALV_POD_StatusCharger1 "Fh";
BA_ "GenSigTimeoutTime_ALL" SG_ 787 POD_statusOBC 500;
BA_ "InvalidValue" SG_ 787 POD_statusOBC "";
BA_ "GenSigTimeoutTime_ALL" SG_ 787 POD_OBC_Max_Current_Out 500;
BA_ "InvalidValue" SG_ 787 POD_OBC_Max_Current_Out "";
BA_ "GenSigTimeoutTime_ALL" SG_ 787 POD_iDCOut 500;
BA_ "InvalidValue" SG_ 787 POD_iDCOut "FFh";
BA_ "GenSigTimeoutTime_ALL" SG_ 787 POD_vDCOut 500;
BA_ "InvalidValue" SG_ 787 POD_vDCOut "FFFFh";
BA_ "GenSigTimeoutTime_ALL" SG_ 787 SECCAN_POD_StatusCharger1 500;
BA_ "InvalidValue" SG_ 787 SECCAN_POD_StatusCharger1 "";
BA_ "GenSigTimeoutTime_ALL" SG_ 803 CHSKM_POD_StatusCharger2 500;
BA_ "InvalidValue" SG_ 803 CHSKM_POD_StatusCharger2 "";
BA_ "GenSigTimeoutTime_ALL" SG_ 803 ALV_POD_StatusCharger2 500;
BA_ "InvalidValue" SG_ 803 ALV_POD_StatusCharger2 "Fh";
BA_ "GenSigStartValue" SG_ 803 POD_phaseACInput 1;
BA_ "GenSigTimeoutTime_ALL" SG_ 803 POD_phaseACInput 500;
BA_ "InvalidValue" SG_ 803 POD_phaseACInput "0";
BA_ "GenSigTimeoutTime_ALL" SG_ 803 POD_iACInput 500;
BA_ "InvalidValue" SG_ 803 POD_iACInput "";
BA_ "GenSigTimeoutTime_ALL" SG_ 803 POD_vACInput 500;
BA_ "InvalidValue" SG_ 803 POD_vACInput "";
BA_ "GenSigStartValue" SG_ 803 POD_tempACCharger 40;
BA_ "GenSigTimeoutTime_ALL" SG_ 803 POD_tempACCharger 500;
BA_ "InvalidValue" SG_ 803 POD_tempACCharger "FFh";
BA_ "GenSigStartValue" SG_ 803 POD_tempColdplate 40;
BA_ "GenSigTimeoutTime_ALL" SG_ 803 POD_tempColdplate 500;
BA_ "InvalidValue" SG_ 803 POD_tempColdplate "FFh";
BA_ "GenSigTimeoutTime_ALL" SG_ 806 CHSKM_POD_StatusDCDC1 500;
BA_ "InvalidValue" SG_ 806 CHSKM_POD_StatusDCDC1 "";
BA_ "GenSigSendType" SG_ 806 ALV_POD_StatusDCDC1 3;
BA_ "GenSigTimeoutTime_ALL" SG_ 806 ALV_POD_StatusDCDC1 500;
BA_ "InvalidValue" SG_ 806 ALV_POD_StatusDCDC1 "Fh";
BA_ "GenSigTimeoutTime_ALL" SG_ 806 POD_statusDCDC 500;
BA_ "InvalidValue" SG_ 806 POD_statusDCDC "7h";
BA_ "GenSigTimeoutTime_ALL" SG_ 806 POD_DCDC_Max_Current_Out 500;
BA_ "InvalidValue" SG_ 806 POD_DCDC_Max_Current_Out "FFh";
BA_ "GenSigTimeoutTime_ALL" SG_ 807 CHKSM_POD_StatusFC 500;
BA_ "InvalidValue" SG_ 807 CHKSM_POD_StatusFC "";
BA_ "GenSigTimeoutTime_ALL" SG_ 807 ALV_POD_StatusFC 500;
BA_ "InvalidValue" SG_ 807 ALV_POD_StatusFC "Fh";
BA_ "GenSigTimeoutTime_ALL" SG_ 807 POD_vFC 500;
BA_ "InvalidValue" SG_ 807 POD_vFC "FFFFh";
BA_ "GenSigTimeoutTime_ALL" SG_ 807 POD_statusFCContactors 500;
BA_ "InvalidValue" SG_ 807 POD_statusFCContactors "7h";
BA_ "GenSigTimeoutTime_ALL" SG_ 816 MILE_KM 500;
BA_ "InvalidValue" SG_ 816 MILE_KM "FFFFFFh";
BA_ "GenSigTimeoutTime_ALL" SG_ 816 FLLV_FUTA 500;
BA_ "InvalidValue" SG_ 816 FLLV_FUTA "FFh";
BA_ "GenSigTimeoutTime_ALL" SG_ 816 RNG 500;
BA_ "InvalidValue" SG_ 816 RNG "FFFh";
BA_ "GenSigTimeoutTime_ALL" SG_ 816 ST_FLLV_FUTA_SPAR 500;
BA_ "InvalidValue" SG_ 816 ST_FLLV_FUTA_SPAR "3h";
BA_ "GenSigTimeoutTime_ALL" SG_ 838 CHSKM_POD_StatusDCDC2 500;
BA_ "InvalidValue" SG_ 838 CHSKM_POD_StatusDCDC2 "";
BA_ "GenSigTimeoutTime_ALL" SG_ 838 ALV_POD_StatusDCDC2 500;
BA_ "InvalidValue" SG_ 838 ALV_POD_StatusDCDC2 "Fh";
BA_ "GenSigTimeoutTime_ALL" SG_ 838 POD_vDCInput 500;
BA_ "InvalidValue" SG_ 838 POD_vDCInput "FFFFh";
BA_ "GenSigTimeoutTime_ALL" SG_ 838 POD_iDCDCOutput 500;
BA_ "InvalidValue" SG_ 838 POD_iDCDCOutput "FFFFh";
BA_ "GenSigTimeoutTime_ALL" SG_ 838 POD_vDCDCOutput 500;
BA_ "InvalidValue" SG_ 838 POD_vDCDCOutput "FFFFh";
BA_ "GenSigTimeoutTime_ALL" SG_ 840 CHKSM_EDS_Sts_FR 500;
BA_ "InvalidValue" SG_ 840 CHKSM_EDS_Sts_FR "";
BA_ "GenSigTimeoutTime_ALL" SG_ 840 ALV_EDS_Sts_FR 500;
BA_ "InvalidValue" SG_ 840 ALV_EDS_Sts_FR "Fh";
BA_ "GenSigTimeoutTime_ALL" SG_ 840 EDS_bus_Volt_FWD 500;
BA_ "InvalidValue" SG_ 840 EDS_bus_Volt_FWD "3FFFh";
BA_ "GenSigTimeoutTime_ALL" SG_ 840 EDS_HVIL_STS_FWD 500;
BA_ "InvalidValue" SG_ 840 EDS_HVIL_STS_FWD "";
BA_ "GenSigTimeoutTime_ALL" SG_ 840 EDS_bus_Curr_FWD 500;
BA_ "InvalidValue" SG_ 840 EDS_bus_Curr_FWD "FFFFh";
BA_ "GenSigTimeoutTime_ALL" SG_ 840 EDS_MtrNumb_FWD 500;
BA_ "InvalidValue" SG_ 840 EDS_MtrNumb_FWD "";
BA_ "GenSigTimeoutTime_ALL" SG_ 840 EDS_DriveMtrNmb_FWD 500;
BA_ "InvalidValue" SG_ 840 EDS_DriveMtrNmb_FWD "";
BA_ "GenSigTimeoutTime_ALL" SG_ 841 CHKSM_EDS_Sts_RR 500;
BA_ "InvalidValue" SG_ 841 CHKSM_EDS_Sts_RR "";
BA_ "GenSigTimeoutTime_ALL" SG_ 841 ALV_EDS_Sts_RR 500;
BA_ "InvalidValue" SG_ 841 ALV_EDS_Sts_RR "Fh";
BA_ "GenSigTimeoutTime_ALL" SG_ 841 EDS_bus_Volt_RWD 500;
BA_ "InvalidValue" SG_ 841 EDS_bus_Volt_RWD "3FFFh";
BA_ "GenSigTimeoutTime_ALL" SG_ 841 EDS_HVIL_STS_RWD 500;
BA_ "InvalidValue" SG_ 841 EDS_HVIL_STS_RWD "";
BA_ "GenSigTimeoutTime_ALL" SG_ 841 EDS_bus_Curr_RWD 500;
BA_ "InvalidValue" SG_ 841 EDS_bus_Curr_RWD "FFFFh";
BA_ "GenSigTimeoutTime_ALL" SG_ 841 EDS_DriveMtrNmb_RWD 500;
BA_ "InvalidValue" SG_ 841 EDS_DriveMtrNmb_RWD "";
BA_ "GenSigTimeoutTime_ALL" SG_ 841 EDS_MtrNumb_RWD 500;
BA_ "InvalidValue" SG_ 841 EDS_MtrNumb_RWD "";
BA_ "GenSigTimeoutTime_ALL" SG_ 870 CHSKM_POD_Thermal 2500;
BA_ "InvalidValue" SG_ 870 CHSKM_POD_Thermal "";
BA_ "GenSigTimeoutTime_ALL" SG_ 870 ALV_PPOD_POD_Thermal 2500;
BA_ "InvalidValue" SG_ 870 ALV_PPOD_POD_Thermal "Fh";
BA_ "GenSigStartValue" SG_ 870 POD_tempHVBusPlus 40;
BA_ "GenSigTimeoutTime_ALL" SG_ 870 POD_tempHVBusPlus 2500;
BA_ "InvalidValue" SG_ 870 POD_tempHVBusPlus "FFh";
BA_ "GenSigStartValue" SG_ 870 POD_tempHVBusNeg 40;
BA_ "GenSigTimeoutTime_ALL" SG_ 870 POD_tempHVBusNeg 2500;
BA_ "InvalidValue" SG_ 870 POD_tempHVBusNeg "FFh";
BA_ "GenSigStartValue" SG_ 870 POD_tempInternal 40;
BA_ "GenSigTimeoutTime_ALL" SG_ 870 POD_tempInternal 2500;
BA_ "InvalidValue" SG_ 870 POD_tempInternal "FFh";
BA_ "GenSigStartValue" SG_ 870 POD_tempColdPlate 40;
BA_ "GenSigTimeoutTime_ALL" SG_ 870 POD_FlowRate_Req 2500;
BA_ "InvalidValue" SG_ 870 POD_FlowRate_Req "FFh";
BA_ "GenSigTimeoutTime_ALL" SG_ 870 POD_CoolPwrDemand 2500;
BA_ "InvalidValue" SG_ 870 POD_CoolPwrDemand "FFh";
BA_ "GenSigTimeoutTime_ALL" SG_ 885 Checksum_0x375 500;
BA_ "InvalidValue" SG_ 885 Checksum_0x375 "";
BA_ "GenSigTimeoutTime_ALL" SG_ 885 Rolling_Counter_0x375 500;
BA_ "InvalidValue" SG_ 885 Rolling_Counter_0x375 "Fh";
BA_ "GenSigTimeoutTime_ALL" SG_ 885 BMS_PreChgRelay_ERR 500;
BA_ "InvalidValue" SG_ 885 BMS_PreChgRelay_ERR "";
BA_ "GenSigTimeoutTime_ALL" SG_ 885 BMS_TotalNegRelay_ERR 500;
BA_ "InvalidValue" SG_ 885 BMS_TotalNegRelay_ERR "";
BA_ "GenSigTimeoutTime_ALL" SG_ 885 BMS_MainPosRelay_ERR 500;
BA_ "InvalidValue" SG_ 885 BMS_MainPosRelay_ERR "";
BA_ "GenSigTimeoutTime_ALL" SG_ 885 BMS_MainPosRelay_STS 500;
BA_ "InvalidValue" SG_ 885 BMS_MainPosRelay_STS "7h";
BA_ "GenSigTimeoutTime_ALL" SG_ 885 BMS_PreChgRelay_STS 500;
BA_ "InvalidValue" SG_ 885 BMS_PreChgRelay_STS "7h";
BA_ "GenSigTimeoutTime_ALL" SG_ 885 BMS_TotalNegRelay_STS 500;
BA_ "InvalidValue" SG_ 885 BMS_TotalNegRelay_STS "7h";
BA_ "GenSigTimeoutTime_ALL" SG_ 895 CHKSM_EPS2_Advanced 100;
BA_ "InvalidValue" SG_ 895 CHKSM_EPS2_Advanced "";
BA_ "GenSigTimeoutTime_ALL" SG_ 895 ALV_EPS2_Advanced 100;
BA_ "InvalidValue" SG_ 895 ALV_EPS2_Advanced "Fh";
BA_ "GenSigTimeoutTime_ALL" SG_ 895 EPS2_TorqSensorSts 100;
BA_ "InvalidValue" SG_ 895 EPS2_TorqSensorSts "";
BA_ "GenSigStartValue" SG_ 895 EPS2_SteeringTorque 1024;
BA_ "GenSigTimeoutTime_ALL" SG_ 895 EPS2_SteeringTorque 100;
BA_ "InvalidValue" SG_ 895 EPS2_SteeringTorque "FFFh";
BA_ "GenSigTimeoutTime_ALL" SG_ 895 EPS2_SteeringTorqueValid 100;
BA_ "InvalidValue" SG_ 895 EPS2_SteeringTorqueValid "";
BA_ "GenSigTimeoutTime_ALL" SG_ 895 EPS2_Mode 100;
BA_ "InvalidValue" SG_ 895 EPS2_Mode "3h";
BA_ "GenSigTimeoutTime_ALL" SG_ 895 EPS2_Steering_angle_spd 100;
BA_ "InvalidValue" SG_ 895 EPS2_Steering_angle_spd "";
BA_ "GenSigTimeoutTime_ALL" SG_ 895 EPS2AngRespSts 100;
BA_ "InvalidValue" SG_ 895 EPS2AngRespSts "3h";
BA_ "GenSigTimeoutTime_ALL" SG_ 895 EPS2_Steering_angle 100;
BA_ "InvalidValue" SG_ 895 EPS2_Steering_angle "";
BA_ "GenSigTimeoutTime_ALL" SG_ 896 VIN_Byte1 5000;
BA_ "InvalidValue" SG_ 896 VIN_Byte1 "";
BA_ "GenSigTimeoutTime_ALL" SG_ 896 VIN_Byte2 5000;
BA_ "InvalidValue" SG_ 896 VIN_Byte2 "";
BA_ "GenSigTimeoutTime_ALL" SG_ 896 VIN_Byte3 5000;
BA_ "InvalidValue" SG_ 896 VIN_Byte3 "";
BA_ "GenSigTimeoutTime_ALL" SG_ 896 VIN_Byte4 5000;
BA_ "InvalidValue" SG_ 896 VIN_Byte4 "";
BA_ "GenSigTimeoutTime_ALL" SG_ 896 VIN_Byte5 5000;
BA_ "InvalidValue" SG_ 896 VIN_Byte5 "";
BA_ "GenSigTimeoutTime_ALL" SG_ 896 VIN_Byte6 5000;
BA_ "InvalidValue" SG_ 896 VIN_Byte6 "";
BA_ "GenSigTimeoutTime_ALL" SG_ 896 VIN_Byte7 5000;
BA_ "InvalidValue" SG_ 896 VIN_Byte7 "";
BA_ "GenSigTimeoutTime_ALL" SG_ 897 CHKSM_ACM_SEAT_OCCUPATION 1000;
BA_ "InvalidValue" SG_ 897 CHKSM_ACM_SEAT_OCCUPATION "";
BA_ "GenSigTimeoutTime_ALL" SG_ 897 ALV_ACM_SEAT_OCCUPATION 1000;
BA_ "InvalidValue" SG_ 897 ALV_ACM_SEAT_OCCUPATION "Fh";
BA_ "GenSigTimeoutTime_ALL" SG_ 897 ACM_Seat_Occupancy_Passenger 1000;
BA_ "InvalidValue" SG_ 897 ACM_Seat_Occupancy_Passenger "";
BA_ "GenSigTimeoutTime_ALL" SG_ 897 ACM_Seat_Occupancy_2nd_Row_Dri 1000;
BA_ "InvalidValue" SG_ 897 ACM_Seat_Occupancy_2nd_Row_Dri "";
BA_ "GenSigTimeoutTime_ALL" SG_ 897 ACM_Seat_Occupancy_2nd_Row_Pas 1000;
BA_ "InvalidValue" SG_ 897 ACM_Seat_Occupancy_2nd_Row_Pas "";
BA_ "GenSigTimeoutTime_ALL" SG_ 897 ACM_Seat_Occupancy_2nd_Row_Mid 1000;
BA_ "InvalidValue" SG_ 897 ACM_Seat_Occupancy_2nd_Row_Mid "";
BA_ "GenSigTimeoutTime_ALL" SG_ 897 ACM_Seat_Belt_Status_Passenger 1000;
BA_ "InvalidValue" SG_ 897 ACM_Seat_Belt_Status_Passenger "";
BA_ "GenSigTimeoutTime_ALL" SG_ 897 ACM_Seat_Belt_Status_Driver 1000;
BA_ "InvalidValue" SG_ 897 ACM_Seat_Belt_Status_Driver "";
BA_ "GenSigTimeoutTime_ALL" SG_ 897 ACM_Seat_Belt_Status_2nd_Row_Dri 1000;
BA_ "InvalidValue" SG_ 897 ACM_Seat_Belt_Status_2nd_Row_Dri "";
BA_ "GenSigTimeoutTime_ALL" SG_ 897 ACM_Seat_Belt_Status_2nd_Row_Mid 1000;
BA_ "InvalidValue" SG_ 897 ACM_Seat_Belt_Status_2nd_Row_Mid "";
BA_ "GenSigTimeoutTime_ALL" SG_ 897 ACM_Seat_Belt_Status_2nd_Row_Pas 1000;
BA_ "InvalidValue" SG_ 897 ACM_Seat_Belt_Status_2nd_Row_Pas "";
BA_ "GenSigSendType" SG_ 905 VCU_IMMO_Sts 1;
BA_ "InvalidValue" SG_ 905 VCU_IMMO_Sts "";
BA_ "GenSigSendType" SG_ 905 SECCAN_VCU_IMMO_Sts 1;
BA_ "InvalidValue" SG_ 905 SECCAN_VCU_IMMO_Sts "";
BA_ "GenSigSendType" SG_ 920 BCM_Immo_Byte_0 1;
BA_ "InvalidValue" SG_ 920 BCM_Immo_Byte_0 "";
BA_ "GenSigSendType" SG_ 920 BCM_Immo_Byte_1 1;
BA_ "InvalidValue" SG_ 920 BCM_Immo_Byte_1 "";
BA_ "GenSigSendType" SG_ 920 BCM_Immo_Byte_2 1;
BA_ "InvalidValue" SG_ 920 BCM_Immo_Byte_2 "";
BA_ "GenSigSendType" SG_ 920 BCM_Immo_Byte_3 1;
BA_ "InvalidValue" SG_ 920 BCM_Immo_Byte_3 "";
BA_ "GenSigSendType" SG_ 920 BCM_Immo_Byte_4 1;
BA_ "InvalidValue" SG_ 920 BCM_Immo_Byte_4 "";
BA_ "GenSigSendType" SG_ 920 BCM_Immo_Byte_5 1;
BA_ "InvalidValue" SG_ 920 BCM_Immo_Byte_5 "";
BA_ "GenSigSendType" SG_ 920 BCM_Immo_Byte_6 1;
BA_ "InvalidValue" SG_ 920 BCM_Immo_Byte_6 "";
BA_ "GenSigSendType" SG_ 920 BCM_Immo_Byte_7 1;
BA_ "InvalidValue" SG_ 920 BCM_Immo_Byte_7 "";
BA_ "GenSigSendType" SG_ 921 VCU_Immo_Byte_0 1;
BA_ "InvalidValue" SG_ 921 VCU_Immo_Byte_0 "";
BA_ "GenSigSendType" SG_ 921 VCU_Immo_Byte_1 1;
BA_ "InvalidValue" SG_ 921 VCU_Immo_Byte_1 "";
BA_ "GenSigSendType" SG_ 921 VCU_Immo_Byte_2 1;
BA_ "InvalidValue" SG_ 921 VCU_Immo_Byte_2 "";
BA_ "GenSigSendType" SG_ 921 VCU_Immo_Byte_3 1;
BA_ "InvalidValue" SG_ 921 VCU_Immo_Byte_3 "";
BA_ "GenSigSendType" SG_ 921 VCU_Immo_Byte_4 1;
BA_ "InvalidValue" SG_ 921 VCU_Immo_Byte_4 "";
BA_ "GenSigSendType" SG_ 921 VCU_Immo_Byte_5 1;
BA_ "InvalidValue" SG_ 921 VCU_Immo_Byte_5 "";
BA_ "GenSigSendType" SG_ 921 VCU_Immo_Byte_6 1;
BA_ "InvalidValue" SG_ 921 VCU_Immo_Byte_6 "";
BA_ "GenSigSendType" SG_ 921 VCU_Immo_Byte_7 1;
BA_ "InvalidValue" SG_ 921 VCU_Immo_Byte_7 "";
BA_ "GenSigTimeoutTime_ALL" SG_ 937 SUM_VCU_Thermal_info_FB 500;
BA_ "InvalidValue" SG_ 937 SUM_VCU_Thermal_info_FB "";
BA_ "GenSigTimeoutTime_ALL" SG_ 937 ALV_VCU_Thermal_info_FB 500;
BA_ "InvalidValue" SG_ 937 ALV_VCU_Thermal_info_FB "Fh";
BA_ "GenSigTimeoutTime_ALL" SG_ 937 VCU_Pump_2_Stt 500;
BA_ "InvalidValue" SG_ 937 VCU_Pump_2_Stt "";
BA_ "GenSigTimeoutTime_ALL" SG_ 937 VCU_Pump_1_Stt 500;
BA_ "InvalidValue" SG_ 937 VCU_Pump_1_Stt "";
BA_ "GenSigTimeoutTime_ALL" SG_ 937 VCU_Pump_1_Flowrate 500;
BA_ "InvalidValue" SG_ 937 VCU_Pump_1_Flowrate "";
BA_ "GenSigTimeoutTime_ALL" SG_ 937 VCU_Pump_2_Flowrate 500;
BA_ "InvalidValue" SG_ 937 VCU_Pump_2_Flowrate "";
BA_ "GenSigStartValue" SG_ 937 VCU_TempSensor_1_value 40;
BA_ "GenSigTimeoutTime_ALL" SG_ 937 VCU_TempSensor_1_value 500;
BA_ "InvalidValue" SG_ 937 VCU_TempSensor_1_value "";
BA_ "GenSigStartValue" SG_ 937 VCU_TempSensor_6_value 40;
BA_ "GenSigTimeoutTime_ALL" SG_ 937 VCU_TempSensor_6_value 500;
BA_ "InvalidValue" SG_ 937 VCU_TempSensor_6_value "";
BA_ "GenSigStartValue" SG_ 937 VCU_TempSensor_5_value 40;
BA_ "GenSigTimeoutTime_ALL" SG_ 937 VCU_TempSensor_5_value 500;
BA_ "InvalidValue" SG_ 937 VCU_TempSensor_5_value "";
BA_ "GenSigTimeoutTime_ALL" SG_ 992 CRC_VCU_HVsystem_status 200;
BA_ "InvalidValue" SG_ 992 CRC_VCU_HVsystem_status "";
BA_ "GenSigTimeoutTime_ALL" SG_ 992 ALIV_VCU_HVsystem_status 200;
BA_ "InvalidValue" SG_ 992 ALIV_VCU_HVsystem_status "Fh";
BA_ "GenSigTimeoutTime_ALL" SG_ 992 VCU_RunningRange 200;
BA_ "InvalidValue" SG_ 992 VCU_RunningRange "";
BA_ "GenSigTimeoutTime_ALL" SG_ 992 VCU_RunningRange_chrg_estSts 200;
BA_ "InvalidValue" SG_ 992 VCU_RunningRange_chrg_estSts "";
BA_ "GenSigTimeoutTime_ALL" SG_ 992 VCU_RunningRange_charged 200;
BA_ "InvalidValue" SG_ 992 VCU_RunningRange_charged "";
BA_ "GenSigTimeoutTime_ALL" SG_ 992 VCU_HVbatSoc_charged 200;
BA_ "InvalidValue" SG_ 992 VCU_HVbatSoc_charged "";
BA_ "GenSigTimeoutTime_ALL" SG_ 992 VCU_HVbatSoc_charged_estStatus 200;
BA_ "InvalidValue" SG_ 992 VCU_HVbatSoc_charged_estStatus "";
BA_ "GenSigTimeoutTime_ALL" SG_ 993 CRC_VCU_HMI_Info 500;
BA_ "InvalidValue" SG_ 993 CRC_VCU_HMI_Info "";
BA_ "GenSigTimeoutTime_ALL" SG_ 993 ALIV_VCU_HMI_Info 500;
BA_ "InvalidValue" SG_ 993 ALIV_VCU_HMI_Info "Fh";
BA_ "GenSigTimeoutTime_ALL" SG_ 993 VCU_SetCruiseSpd 500;
BA_ "InvalidValue" SG_ 993 VCU_SetCruiseSpd "FFh";
BA_ "GenSigTimeoutTime_ALL" SG_ 993 VCU_CruiseCtrlSts 500;
BA_ "InvalidValue" SG_ 993 VCU_CruiseCtrlSts "";
BA_ "GenSigStartValue" SG_ 993 VCU_MHU_Ack_ChgSche_stt 3;
BA_ "GenSigTimeoutTime_ALL" SG_ 993 VCU_MHU_Ack_ChgSche_stt 500;
BA_ "InvalidValue" SG_ 993 VCU_MHU_Ack_ChgSche_stt "3h";
BA_ "GenSigStartValue" SG_ 993 VCU_MHU_Ack_TargetSOC 100;
BA_ "GenSigTimeoutTime_ALL" SG_ 993 VCU_MHU_Ack_TargetSOC 500;
BA_ "InvalidValue" SG_ 993 VCU_MHU_Ack_TargetSOC "7Fh";
BA_ "GenSigTimeoutTime_ALL" SG_ 993 VCU_ValetMode_sts 500;
BA_ "InvalidValue" SG_ 993 VCU_ValetMode_sts "FFh";
BA_ "GenSigTimeoutTime_ALL" SG_ 993 VCU_ValetMode_MaxSpeedSts 500;
BA_ "InvalidValue" SG_ 993 VCU_ValetMode_MaxSpeedSts "FFh";
BA_ "GenSigTimeoutTime_ALL" SG_ 993 SECCAN_VCU_HMI_Info 500;
BA_ "InvalidValue" SG_ 993 SECCAN_VCU_HMI_Info "";
BA_ "GenSigSendType" SG_ 1015 CHSKM_MFS_Control_Button 4;
BA_ "GenSigTimeoutTime_ALL" SG_ 1015 CHSKM_MFS_Control_Button 5000;
BA_ "InvalidValue" SG_ 1015 CHSKM_MFS_Control_Button "";
BA_ "GenSigSendType" SG_ 1015 ALV_MFS_Control_Button 4;
BA_ "GenSigTimeoutTime_ALL" SG_ 1015 ALV_MFS_Control_Button 5000;
BA_ "InvalidValue" SG_ 1015 ALV_MFS_Control_Button "Fh";
BA_ "GenSigSendType" SG_ 1015 MFS_VoiceRecognitionOn_Off 4;
BA_ "GenSigTimeoutTime_ALL" SG_ 1015 MFS_VoiceRecognitionOn_Off 5000;
BA_ "InvalidValue" SG_ 1015 MFS_VoiceRecognitionOn_Off "4h";
BA_ "GenSigSendType" SG_ 1015 MFS_ISAControl 4;
BA_ "GenSigTimeoutTime_ALL" SG_ 1015 MFS_ISAControl 5000;
BA_ "InvalidValue" SG_ 1015 MFS_ISAControl "3h";
BA_ "GenSigSendType" SG_ 1015 MFS_CruiseSpeedIncrease 4;
BA_ "GenSigTimeoutTime_ALL" SG_ 1015 MFS_CruiseSpeedIncrease 5000;
BA_ "InvalidValue" SG_ 1015 MFS_CruiseSpeedIncrease "4h";
BA_ "GenSigSendType" SG_ 1015 MFS_TelephoneCall_EndCall 4;
BA_ "GenSigTimeoutTime_ALL" SG_ 1015 MFS_TelephoneCall_EndCall 5000;
BA_ "InvalidValue" SG_ 1015 MFS_TelephoneCall_EndCall "4h";
BA_ "GenSigSendType" SG_ 1015 MFS_LKAControl 4;
BA_ "GenSigTimeoutTime_ALL" SG_ 1015 MFS_LKAControl 5000;
BA_ "InvalidValue" SG_ 1015 MFS_LKAControl "3h";
BA_ "GenSigSendType" SG_ 1015 MFS_CruiseGapIncrease 4;
BA_ "GenSigTimeoutTime_ALL" SG_ 1015 MFS_CruiseGapIncrease 5000;
BA_ "InvalidValue" SG_ 1015 MFS_CruiseGapIncrease "4h";
BA_ "GenSigSendType" SG_ 1015 MFS_CruiseOn_Off 4;
BA_ "GenSigTimeoutTime_ALL" SG_ 1015 MFS_CruiseOn_Off 5000;
BA_ "InvalidValue" SG_ 1015 MFS_CruiseOn_Off "4h";
BA_ "GenSigSendType" SG_ 1015 MFS_CruiseGapDecrease 4;
BA_ "GenSigTimeoutTime_ALL" SG_ 1015 MFS_CruiseGapDecrease 5000;
BA_ "InvalidValue" SG_ 1015 MFS_CruiseGapDecrease "4h";
BA_ "GenSigSendType" SG_ 1015 MFS_CAN_RESControl 4;
BA_ "GenSigTimeoutTime_ALL" SG_ 1015 MFS_CAN_RESControl 5000;
BA_ "InvalidValue" SG_ 1015 MFS_CAN_RESControl "3h";
BA_ "GenSigSendType" SG_ 1015 MFS_CruiseSpeedDecrease 4;
BA_ "GenSigTimeoutTime_ALL" SG_ 1015 MFS_CruiseSpeedDecrease 5000;
BA_ "InvalidValue" SG_ 1015 MFS_CruiseSpeedDecrease "4h";
BA_ "GenSigSendType" SG_ 1015 MFS_SourseControl 4;
BA_ "GenSigTimeoutTime_ALL" SG_ 1015 MFS_SourseControl 5000;
BA_ "InvalidValue" SG_ 1015 MFS_SourseControl "4h";
BA_ "GenSigSendType" SG_ 1015 MFS_UpControl 4;
BA_ "GenSigTimeoutTime_ALL" SG_ 1015 MFS_UpControl 5000;
BA_ "InvalidValue" SG_ 1015 MFS_UpControl "4h";
BA_ "GenSigSendType" SG_ 1015 MFS_DownControl 4;
BA_ "GenSigTimeoutTime_ALL" SG_ 1015 MFS_DownControl 5000;
BA_ "InvalidValue" SG_ 1015 MFS_DownControl "4h";
BA_ "GenSigSendType" SG_ 1015 MFS_LeftControl 4;
BA_ "GenSigTimeoutTime_ALL" SG_ 1015 MFS_LeftControl 5000;
BA_ "InvalidValue" SG_ 1015 MFS_LeftControl "4h";
BA_ "GenSigSendType" SG_ 1015 MFS_Failure 4;
BA_ "GenSigTimeoutTime_ALL" SG_ 1015 MFS_Failure 5000;
BA_ "InvalidValue" SG_ 1015 MFS_Failure "";
BA_ "GenSigSendType" SG_ 1015 MFS_RightControl 4;
BA_ "GenSigTimeoutTime_ALL" SG_ 1015 MFS_RightControl 5000;
BA_ "InvalidValue" SG_ 1015 MFS_RightControl "4h";
BA_ "GenSigSendType" SG_ 1015 MFS_OK_Control 4;
BA_ "GenSigTimeoutTime_ALL" SG_ 1015 MFS_OK_Control 5000;
BA_ "InvalidValue" SG_ 1015 MFS_OK_Control "4h";
BA_ "InvalidValue" SG_ 1027 MHU_AutoP_Setting "3h";
BA_ "GenSigStartValue" SG_ 1027 MHU_AutoP_Setting 2;
BA_ "GenSigTimeoutTime_ALL" SG_ 1027 MHU_AutoP_Setting 500;
BA_ "GenSigTimeoutTime_ALL" SG_ 1027 CHKSM_MHU_EVSetting 500;
BA_ "InvalidValue" SG_ 1027 CHKSM_MHU_EVSetting "";
BA_ "GenSigTimeoutTime_ALL" SG_ 1027 ALV_MHU_EVSetting 500;
BA_ "InvalidValue" SG_ 1027 ALV_MHU_EVSetting "Fh";
BA_ "GenSigTimeoutTime_ALL" SG_ 1027 MHU_VCU_CreepDisable_stt 500;
BA_ "InvalidValue" SG_ 1027 MHU_VCU_CreepDisable_stt "";
BA_ "GenSigTimeoutTime_ALL" SG_ 1027 MHU_BrakeRegenMode 500;
BA_ "InvalidValue" SG_ 1027 MHU_BrakeRegenMode "";
BA_ "GenSigStartValue" SG_ 1027 MHU_ChargeSetTargetSOC 80;
BA_ "GenSigTimeoutTime_ALL" SG_ 1027 MHU_ChargeSetTargetSOC 500;
BA_ "InvalidValue" SG_ 1027 MHU_ChargeSetTargetSOC "7Fh";
BA_ "GenSigStartValue" SG_ 1027 MHU_ChargeScheduleSet 2;
BA_ "GenSigTimeoutTime_ALL" SG_ 1027 MHU_ChargeScheduleSet 500;
BA_ "InvalidValue" SG_ 1027 MHU_ChargeScheduleSet "3h";
BA_ "GenSigStartValue" SG_ 1027 MHU_ChargingRequest 3;
BA_ "GenSigTimeoutTime_ALL" SG_ 1027 MHU_ChargingRequest 500;
BA_ "InvalidValue" SG_ 1027 MHU_ChargingRequest "";
BA_ "GenSigTimeoutTime_ALL" SG_ 1027 MHU_ChgPort_Open_req 500;
BA_ "InvalidValue" SG_ 1027 MHU_ChgPort_Open_req "3h";
BA_ "GenSigStartValue" SG_ 1027 MHU_SET_DrivingModeSwitch 3;
BA_ "GenSigTimeoutTime_ALL" SG_ 1027 MHU_SET_DrivingModeSwitch 500;
BA_ "InvalidValue" SG_ 1027 MHU_SET_DrivingModeSwitch "3h";
BA_ "GenSigStartValue" SG_ 1027 MHU_ValetMode_Activation 2;
BA_ "GenSigTimeoutTime_ALL" SG_ 1027 MHU_ValetMode_Activation 500;
BA_ "InvalidValue" SG_ 1027 MHU_ValetMode_Activation "FFh";
BA_ "GenSigStartValue" SG_ 1027 MHU_ValetMode_MaxSpeed 255;
BA_ "GenSigTimeoutTime_ALL" SG_ 1027 MHU_ValetMode_MaxSpeed 500;
BA_ "InvalidValue" SG_ 1027 MHU_ValetMode_MaxSpeed "FFh";
BA_ "GenSigStartValue" SG_ 1027 MHU_ChargingCurrentLimit 6;
BA_ "GenSigTimeoutTime_ALL" SG_ 1027 MHU_ChargingCurrentLimit 500;
BA_ "InvalidValue" SG_ 1027 MHU_ChargingCurrentLimit "3Fh";
BA_ "GenSigTimeoutTime_ALL" SG_ 1027 MHU_SET_ActivePreCondition 500;
BA_ "InvalidValue" SG_ 1027 MHU_SET_ActivePreCondition "3h";
BA_ "GenSigTimeoutTime_ALL" SG_ 1027 MHU_SpdLim_Override 500;
BA_ "GenSigSendType" SG_ 1029 MHU_SET_CCUF_FrontDefrost 2;
BA_ "InvalidValue" SG_ 1029 MHU_SET_CCUF_FrontDefrost "3h";
BA_ "GenSigTimeoutTime_ALL" SG_ 1037 CHKSM_MHU_DIGIT_SPEED 1500;
BA_ "GenSigTimeoutTime_ALL" SG_ 1037 ALV_MHU_DIGIT_SPEED 1500;
BA_ "InvalidValue" SG_ 1037 ALV_MHU_DIGIT_SPEED "Fh";
BA_ "GenSigTimeoutTime_ALL" SG_ 1037 MHU_DigitSpeed 1500;
BA_ "InvalidValue" SG_ 1037 MHU_DigitSpeed "1FFh";
BA_ "GenSigTimeoutTime_ALL" SG_ 1074 MHU_FOTA_Checksum 2500;
BA_ "InvalidValue" SG_ 1074 MHU_FOTA_Checksum "";
BA_ "GenSigTimeoutTime_ALL" SG_ 1074 MHU_FOTA_Alive_Counter 2500;
BA_ "InvalidValue" SG_ 1074 MHU_FOTA_Alive_Counter "Fh";
BA_ "GenSigTimeoutTime_ALL" SG_ 1074 MHU_FOTA_State 2500;
BA_ "InvalidValue" SG_ 1074 MHU_FOTA_State "7h";
BA_ "GenSigTimeoutTime_ALL" SG_ 1074 MHU_FOTA_Error_Code 2500;
BA_ "InvalidValue" SG_ 1074 MHU_FOTA_Error_Code "";
BA_ "GenSigTimeoutTime_ALL" SG_ 1079 CRC_VCU_MHU_info_2 1000;
BA_ "GenSigTimeoutTime_ALL" SG_ 1079 ALIV_VCU_MHU_info_2 1000;
BA_ "InvalidValue" SG_ 1079 ALIV_VCU_MHU_info_2 "Fh";
BA_ "GenSigTimeoutTime_ALL" SG_ 1079 VCU_Instant_ConsumEnergy 1000;
BA_ "InvalidValue" SG_ 1079 VCU_Instant_ConsumEnergy "3FFh";
BA_ "GenSigTimeoutTime_ALL" SG_ 1079 VCU_Average_ConsumEnergy 1000;
BA_ "InvalidValue" SG_ 1079 VCU_Average_ConsumEnergy "3FFh";
BA_ "GenSigTimeoutTime_ALL" SG_ 1079 VCU_SpdLimiterSts 1000;
BA_ "GenSigTimeoutTime_ALL" SG_ 1079 VCU_LimiterSpeed 1000;
BA_ "InvalidValue" SG_ 1079 VCU_LimiterSpeed "FFh";
BA_ "GenSigTimeoutTime_ALL" SG_ 1079 VCU_SpdLim_OverrideSts 1000;
BA_ "GenSigTimeoutTime_ALL" SG_ 1080 CHKSM_EDS_Error_FR_A 500;
BA_ "InvalidValue" SG_ 1080 CHKSM_EDS_Error_FR_A "";
BA_ "GenSigTimeoutTime_ALL" SG_ 1080 ALV_EDS_Error_FR_A 500;
BA_ "InvalidValue" SG_ 1080 ALV_EDS_Error_FR_A "Fh";
BA_ "GenSigTimeoutTime_ALL" SG_ 1080 EDS_FailNum_ERR_FWD 500;
BA_ "InvalidValue" SG_ 1080 EDS_FailNum_ERR_FWD "";
BA_ "GenSigTimeoutTime_ALL" SG_ 1080 EDS_FailGrade_ERR_FWD 500;
BA_ "InvalidValue" SG_ 1080 EDS_FailGrade_ERR_FWD "7h";
BA_ "GenSigTimeoutTime_ALL" SG_ 1080 EDS_MotOverTempAlarm_FWD 500;
BA_ "InvalidValue" SG_ 1080 EDS_MotOverTempAlarm_FWD "";
BA_ "GenSigTimeoutTime_ALL" SG_ 1080 EDS_MotOverTempFault_FWD 500;
BA_ "InvalidValue" SG_ 1080 EDS_MotOverTempFault_FWD "";
BA_ "GenSigTimeoutTime_ALL" SG_ 1080 EDS_MotTempSenFault_FWD 500;
BA_ "InvalidValue" SG_ 1080 EDS_MotTempSenFault_FWD "";
BA_ "GenSigTimeoutTime_ALL" SG_ 1080 EDS_EDSOverTempUFault_FWD 500;
BA_ "InvalidValue" SG_ 1080 EDS_EDSOverTempUFault_FWD "";
BA_ "GenSigTimeoutTime_ALL" SG_ 1080 EDS_EDSOverTempVFault_FWD 500;
BA_ "InvalidValue" SG_ 1080 EDS_EDSOverTempVFault_FWD "";
BA_ "GenSigTimeoutTime_ALL" SG_ 1080 EDS_EDSOverTempWFault_FWD 500;
BA_ "InvalidValue" SG_ 1080 EDS_EDSOverTempWFault_FWD "";
BA_ "GenSigTimeoutTime_ALL" SG_ 1080 EDS_EDSOverTempAlarm_FWD 500;
BA_ "InvalidValue" SG_ 1080 EDS_EDSOverTempAlarm_FWD "";
BA_ "GenSigTimeoutTime_ALL" SG_ 1080 EDS_TCoolantOvHi_FWD 500;
BA_ "InvalidValue" SG_ 1080 EDS_TCoolantOvHi_FWD "";
BA_ "GenSigTimeoutTime_ALL" SG_ 1080 EDS_EDSTempCmpAlarm_FWD 500;
BA_ "InvalidValue" SG_ 1080 EDS_EDSTempCmpAlarm_FWD "";
BA_ "GenSigTimeoutTime_ALL" SG_ 1080 EDS_EDSPhaOvCurentHWFault_FWD 500;
BA_ "InvalidValue" SG_ 1080 EDS_EDSPhaOvCurentHWFault_FWD "";
BA_ "GenSigTimeoutTime_ALL" SG_ 1080 EDS_EDSphaOffCalFault_FWD 500;
BA_ "InvalidValue" SG_ 1080 EDS_EDSphaOffCalFault_FWD "";
BA_ "GenSigTimeoutTime_ALL" SG_ 1080 EDS_EDSOverIdcLnkAlarm_FWD 500;
BA_ "InvalidValue" SG_ 1080 EDS_EDSOverIdcLnkAlarm_FWD "";
BA_ "GenSigTimeoutTime_ALL" SG_ 1080 EDS_EDSHVOverVoltageAlarm_FWD 500;
BA_ "InvalidValue" SG_ 1080 EDS_EDSHVOverVoltageAlarm_FWD "";
BA_ "GenSigTimeoutTime_ALL" SG_ 1080 EDS_EDSHVOverVoltageFault_FWD 500;
BA_ "InvalidValue" SG_ 1080 EDS_EDSHVOverVoltageFault_FWD "";
BA_ "GenSigTimeoutTime_ALL" SG_ 1080 EDS_EDSHVUnderVoltageAlarm_FWD 500;
BA_ "InvalidValue" SG_ 1080 EDS_EDSHVUnderVoltageAlarm_FWD "";
BA_ "GenSigTimeoutTime_ALL" SG_ 1080 EDS_EDSHVUnderVoltageFault_FWD 500;
BA_ "InvalidValue" SG_ 1080 EDS_EDSHVUnderVoltageFault_FWD "";
BA_ "GenSigTimeoutTime_ALL" SG_ 1080 EDS_RunToDischaErr_FWD 500;
BA_ "InvalidValue" SG_ 1080 EDS_RunToDischaErr_FWD "";
BA_ "GenSigTimeoutTime_ALL" SG_ 1080 EDS_12VOverVoltageAlarm_FWD 500;
BA_ "InvalidValue" SG_ 1080 EDS_12VOverVoltageAlarm_FWD "";
BA_ "GenSigTimeoutTime_ALL" SG_ 1080 EDS_12VUnderVoltageAlarm_FWD 500;
BA_ "InvalidValue" SG_ 1080 EDS_12VUnderVoltageAlarm_FWD "";
BA_ "GenSigTimeoutTime_ALL" SG_ 1080 EDS_MotOverAlarm_FWD 500;
BA_ "InvalidValue" SG_ 1080 EDS_MotOverAlarm_FWD "";
BA_ "GenSigTimeoutTime_ALL" SG_ 1080 EDS_MotOverFault_FWD 500;
BA_ "InvalidValue" SG_ 1080 EDS_MotOverFault_FWD "";
BA_ "GenSigTimeoutTime_ALL" SG_ 1080 EDS_ResolverOffsetAngle_FWD 500;
BA_ "GenSigTimeoutTime_ALL" SG_ 1080 SECCAN_EDS_Error_FR_A 500;
BA_ "InvalidValue" SG_ 1080 SECCAN_EDS_Error_FR_A "";
BA_ "GenSigTimeoutTime_ALL" SG_ 1081 CHKSM_EDS_Error_RR_A 500;
BA_ "InvalidValue" SG_ 1081 CHKSM_EDS_Error_RR_A "";
BA_ "GenSigTimeoutTime_ALL" SG_ 1081 ALV_EDS_Error_RR_A 500;
BA_ "InvalidValue" SG_ 1081 ALV_EDS_Error_RR_A "Fh";
BA_ "GenSigTimeoutTime_ALL" SG_ 1081 EDS_FailNum_ERR_RWD 500;
BA_ "InvalidValue" SG_ 1081 EDS_FailNum_ERR_RWD "";
BA_ "GenSigTimeoutTime_ALL" SG_ 1081 EDS_FailGrade_ERR_RWD 500;
BA_ "InvalidValue" SG_ 1081 EDS_FailGrade_ERR_RWD "7h";
BA_ "GenSigTimeoutTime_ALL" SG_ 1081 EDS_MotOverTempAlarm_RWD 500;
BA_ "InvalidValue" SG_ 1081 EDS_MotOverTempAlarm_RWD "";
BA_ "GenSigTimeoutTime_ALL" SG_ 1081 EDS_MotOverTempFault_RWD 500;
BA_ "InvalidValue" SG_ 1081 EDS_MotOverTempFault_RWD "";
BA_ "GenSigTimeoutTime_ALL" SG_ 1081 EDS_MotTempSenFault_RWD 500;
BA_ "InvalidValue" SG_ 1081 EDS_MotTempSenFault_RWD "";
BA_ "GenSigTimeoutTime_ALL" SG_ 1081 EDS_EDSOverTempUFault_RWD 500;
BA_ "InvalidValue" SG_ 1081 EDS_EDSOverTempUFault_RWD "";
BA_ "GenSigTimeoutTime_ALL" SG_ 1081 EDS_EDSOverTempVFault_RWD 500;
BA_ "InvalidValue" SG_ 1081 EDS_EDSOverTempVFault_RWD "";
BA_ "GenSigTimeoutTime_ALL" SG_ 1081 EDS_EDSOverTempWFault_RWD 500;
BA_ "InvalidValue" SG_ 1081 EDS_EDSOverTempWFault_RWD "";
BA_ "GenSigTimeoutTime_ALL" SG_ 1081 EDS_EDSOverTempAlarm_RWD 500;
BA_ "InvalidValue" SG_ 1081 EDS_EDSOverTempAlarm_RWD "";
BA_ "GenSigTimeoutTime_ALL" SG_ 1081 EDS_TCoolantOvHi_RWD 500;
BA_ "InvalidValue" SG_ 1081 EDS_TCoolantOvHi_RWD "";
BA_ "GenSigTimeoutTime_ALL" SG_ 1081 EDS_EDSTempCmpAlarm_RWD 500;
BA_ "InvalidValue" SG_ 1081 EDS_EDSTempCmpAlarm_RWD "";
BA_ "GenSigTimeoutTime_ALL" SG_ 1081 EDS_EDSPhaOvCurentHWFault_RWD 500;
BA_ "InvalidValue" SG_ 1081 EDS_EDSPhaOvCurentHWFault_RWD "";
BA_ "GenSigTimeoutTime_ALL" SG_ 1081 EDS_EDSphaOffCalFault_RWD 500;
BA_ "InvalidValue" SG_ 1081 EDS_EDSphaOffCalFault_RWD "";
BA_ "GenSigTimeoutTime_ALL" SG_ 1081 EDS_EDSOverIdcLnkAlarm_RWD 500;
BA_ "InvalidValue" SG_ 1081 EDS_EDSOverIdcLnkAlarm_RWD "";
BA_ "GenSigTimeoutTime_ALL" SG_ 1081 EDS_EDSHVOverVoltageAlarm_RWD 500;
BA_ "InvalidValue" SG_ 1081 EDS_EDSHVOverVoltageAlarm_RWD "";
BA_ "GenSigTimeoutTime_ALL" SG_ 1081 EDS_EDSHVOverVoltageFault_RWD 500;
BA_ "InvalidValue" SG_ 1081 EDS_EDSHVOverVoltageFault_RWD "";
BA_ "GenSigTimeoutTime_ALL" SG_ 1081 EDS_EDSHVUnderVoltageAlarm_RWD 500;
BA_ "InvalidValue" SG_ 1081 EDS_EDSHVUnderVoltageAlarm_RWD "";
BA_ "GenSigTimeoutTime_ALL" SG_ 1081 EDS_EDSHVUnderVoltageFault_RWD 500;
BA_ "InvalidValue" SG_ 1081 EDS_EDSHVUnderVoltageFault_RWD "";
BA_ "GenSigTimeoutTime_ALL" SG_ 1081 EDS_RunToDischaErr_RWD 500;
BA_ "InvalidValue" SG_ 1081 EDS_RunToDischaErr_RWD "";
BA_ "GenSigTimeoutTime_ALL" SG_ 1081 EDS_12VOverVoltageAlarm_RWD 500;
BA_ "InvalidValue" SG_ 1081 EDS_12VOverVoltageAlarm_RWD "";
BA_ "GenSigTimeoutTime_ALL" SG_ 1081 EDS_12VUnderVoltageAlarm_RWD 500;
BA_ "InvalidValue" SG_ 1081 EDS_12VUnderVoltageAlarm_RWD "";
BA_ "GenSigTimeoutTime_ALL" SG_ 1081 EDS_MotOverAlarm_RWD 500;
BA_ "InvalidValue" SG_ 1081 EDS_MotOverAlarm_RWD "";
BA_ "GenSigTimeoutTime_ALL" SG_ 1081 EDS_MotOverFault_RWD 500;
BA_ "InvalidValue" SG_ 1081 EDS_MotOverFault_RWD "";
BA_ "GenSigTimeoutTime_ALL" SG_ 1081 EDS_ResolverOffsetAngle_RWD 500;
BA_ "GenSigTimeoutTime_ALL" SG_ 1081 SECCAN_EDS_Error_RR_A 500;
BA_ "InvalidValue" SG_ 1081 SECCAN_EDS_Error_RR_A "";
BA_ "InvalidValue" SG_ 1082 VCU_AutoP_Feedback "3h";
BA_ "GenSigTimeoutTime_ALL" SG_ 1082 VCU_AutoP_Feedback 500;
BA_ "GenSigTimeoutTime_ALL" SG_ 1082 CRC_VCU_MHU_info 500;
BA_ "InvalidValue" SG_ 1082 CRC_VCU_MHU_info "";
BA_ "GenSigTimeoutTime_ALL" SG_ 1082 ALIV_VCU_MHU_info 500;
BA_ "InvalidValue" SG_ 1082 ALIV_VCU_MHU_info "Fh";
BA_ "GenSigTimeoutTime_ALL" SG_ 1082 VCU_BrakeRegenMode 500;
BA_ "InvalidValue" SG_ 1082 VCU_BrakeRegenMode "";
BA_ "GenSigTimeoutTime_ALL" SG_ 1082 VCU_CreepDisable_stt 500;
BA_ "InvalidValue" SG_ 1082 VCU_CreepDisable_stt "";
BA_ "GenSigStartValue" SG_ 1082 VCU_PowerRegenGaugeDisplay 100;
BA_ "GenSigTimeoutTime_ALL" SG_ 1082 VCU_PowerRegenGaugeDisplay 500;
BA_ "InvalidValue" SG_ 1082 VCU_PowerRegenGaugeDisplay "FFh";
BA_ "GenSigTimeoutTime_ALL" SG_ 1082 VCU_Charging_Authen_stt 500;
BA_ "InvalidValue" SG_ 1082 VCU_Charging_Authen_stt "";
BA_ "GenSigTimeoutTime_ALL" SG_ 1082 VCU_ChgGun_BadConn_stt 500;
BA_ "InvalidValue" SG_ 1082 VCU_ChgGun_BadConn_stt "";
BA_ "GenSigTimeoutTime_ALL" SG_ 1082 VCU_ChgPort_Open_stt 500;
BA_ "InvalidValue" SG_ 1082 VCU_ChgPort_Open_stt "";
BA_ "GenSigStartValue" SG_ 1082 VCU_Regen_available 1;
BA_ "GenSigTimeoutTime_ALL" SG_ 1082 VCU_Regen_available 500;
BA_ "InvalidValue" SG_ 1082 VCU_Regen_available "";
BA_ "GenSigTimeoutTime_ALL" SG_ 1082 VCU_VehChg_STS 500;
BA_ "InvalidValue" SG_ 1082 VCU_VehChg_STS "";
BA_ "GenSigTimeoutTime_ALL" SG_ 1082 VCU_StoppingMode_stt 500;
BA_ "GenSigTimeoutTime_ALL" SG_ 1082 VCU_SOC_display 500;
BA_ "InvalidValue" SG_ 1082 VCU_SOC_display "";
BA_ "GenSigStartValue" SG_ 1082 VCU_ChgGun_Status 7;
BA_ "GenSigTimeoutTime_ALL" SG_ 1082 VCU_ChgGun_Status 500;
BA_ "InvalidValue" SG_ 1082 VCU_ChgGun_Status "7h";
BA_ "GenSigTimeoutTime_ALL" SG_ 1082 VCU_ChgPort_Lock_stt 500;
BA_ "InvalidValue" SG_ 1082 VCU_ChgPort_Lock_stt "";
BA_ "GenSigTimeoutTime_ALL" SG_ 1082 VCU_Hvbatt_charging_stt 500;
BA_ "InvalidValue" SG_ 1082 VCU_Hvbatt_charging_stt "";
BA_ "GenSigTimeoutTime_ALL" SG_ 1083 CHKSM_EDS_Error_FR_B 500;
BA_ "InvalidValue" SG_ 1083 CHKSM_EDS_Error_FR_B "";
BA_ "GenSigTimeoutTime_ALL" SG_ 1083 ALV_EDS_Error_FR_B 500;
BA_ "InvalidValue" SG_ 1083 ALV_EDS_Error_FR_B "Fh";
BA_ "GenSigTimeoutTime_ALL" SG_ 1083 EDS_iDcLnkOvCLimFail_FWD 500;
BA_ "InvalidValue" SG_ 1083 EDS_iDcLnkOvCLimFail_FWD "";
BA_ "GenSigTimeoutTime_ALL" SG_ 1083 EDS_MotBlockedFault_FWD 500;
BA_ "InvalidValue" SG_ 1083 EDS_MotBlockedFault_FWD "";
BA_ "GenSigTimeoutTime_ALL" SG_ 1083 EDS_RSLErr_FWD 500;
BA_ "InvalidValue" SG_ 1083 EDS_RSLErr_FWD "";
BA_ "GenSigTimeoutTime_ALL" SG_ 1083 EDS_MotTrqLimFault_FWD 500;
BA_ "InvalidValue" SG_ 1083 EDS_MotTrqLimFault_FWD "";
BA_ "GenSigTimeoutTime_ALL" SG_ 1083 EDS_VCUChksumFault_FWD 500;
BA_ "InvalidValue" SG_ 1083 EDS_VCUChksumFault_FWD "";
BA_ "GenSigTimeoutTime_ALL" SG_ 1083 EDS_IGBTFault_FWD 500;
BA_ "InvalidValue" SG_ 1083 EDS_IGBTFault_FWD "";
BA_ "GenSigTimeoutTime_ALL" SG_ 1083 EDS_CANBusoffFault_FWD 500;
BA_ "InvalidValue" SG_ 1083 EDS_CANBusoffFault_FWD "";
BA_ "GenSigTimeoutTime_ALL" SG_ 1083 EDS_TDrvBoardOvHiWarn_FWD 500;
BA_ "InvalidValue" SG_ 1083 EDS_TDrvBoardOvHiWarn_FWD "";
BA_ "GenSigTimeoutTime_ALL" SG_ 1083 EDS_TIGBTOvHiFault_FWD 500;
BA_ "InvalidValue" SG_ 1083 EDS_TIGBTOvHiFault_FWD "";
BA_ "GenSigTimeoutTime_ALL" SG_ 1083 EDS_TIGBTOvHiWarn_FWD 500;
BA_ "InvalidValue" SG_ 1083 EDS_TIGBTOvHiWarn_FWD "";
BA_ "GenSigTimeoutTime_ALL" SG_ 1083 EDS_IOHWABSampFail_FWD 500;
BA_ "InvalidValue" SG_ 1083 EDS_IOHWABSampFail_FWD "";
BA_ "GenSigTimeoutTime_ALL" SG_ 1083 EDS_EDSOpenFault_FWD 500;
BA_ "InvalidValue" SG_ 1083 EDS_EDSOpenFault_FWD "";
BA_ "GenSigTimeoutTime_ALL" SG_ 1083 EDS_MotorOpenFault_FWD 500;
BA_ "InvalidValue" SG_ 1083 EDS_MotorOpenFault_FWD "";
BA_ "GenSigTimeoutTime_ALL" SG_ 1083 EDS_EparkSampFail_FWD 500;
BA_ "InvalidValue" SG_ 1083 EDS_EparkSampFail_FWD "";
BA_ "GenSigTimeoutTime_ALL" SG_ 1083 EDS_EmacBlkdWarn_FWD 500;
BA_ "InvalidValue" SG_ 1083 EDS_EmacBlkdWarn_FWD "";
BA_ "GenSigTimeoutTime_ALL" SG_ 1083 EDS_VerMatchFailureErr_FWD 500;
BA_ "InvalidValue" SG_ 1083 EDS_VerMatchFailureErr_FWD "";
BA_ "GenSigTimeoutTime_ALL" SG_ 1083 EDS_DiashCirNoPsblErr_FWD 500;
BA_ "InvalidValue" SG_ 1083 EDS_DiashCirNoPsblErr_FWD "";
BA_ "GenSigTimeoutTime_ALL" SG_ 1083 EDS_OperOutdRngErr_FWD 500;
BA_ "InvalidValue" SG_ 1083 EDS_OperOutdRngErr_FWD "";
BA_ "GenSigTimeoutTime_ALL" SG_ 1083 EDS_PhaseLossFaultErr_FWD 500;
BA_ "InvalidValue" SG_ 1083 EDS_PhaseLossFaultErr_FWD "";
BA_ "GenSigTimeoutTime_ALL" SG_ 1083 EDS_CPLDFault_FWD 500;
BA_ "InvalidValue" SG_ 1083 EDS_CPLDFault_FWD "";
BA_ "GenSigTimeoutTime_ALL" SG_ 1083 EDS_CPLDFaultBaseSpd_FWD 500;
BA_ "InvalidValue" SG_ 1083 EDS_CPLDFaultBaseSpd_FWD "";
BA_ "GenSigTimeoutTime_ALL" SG_ 1083 EDS_IOHWABNen33Fail_FWD 500;
BA_ "InvalidValue" SG_ 1083 EDS_IOHWABNen33Fail_FWD "";
BA_ "GenSigTimeoutTime_ALL" SG_ 1083 EDS_HvMcuSlightFault_FWD 500;
BA_ "InvalidValue" SG_ 1083 EDS_HvMcuSlightFault_FWD "";
BA_ "GenSigTimeoutTime_ALL" SG_ 1083 EDS_HvMcuSevFault_FWD 500;
BA_ "InvalidValue" SG_ 1083 EDS_HvMcuSevFault_FWD "";
BA_ "GenSigTimeoutTime_ALL" SG_ 1083 EDS_EDSPhaSampHWFault_FWD 500;
BA_ "InvalidValue" SG_ 1083 EDS_EDSPhaSampHWFault_FWD "";
BA_ "GenSigTimeoutTime_ALL" SG_ 1083 EDS_IsOvHiErr_FWD 500;
BA_ "InvalidValue" SG_ 1083 EDS_IsOvHiErr_FWD "";
BA_ "GenSigTimeoutTime_ALL" SG_ 1083 EDS_CanRollingCounterErr_FWD 500;
BA_ "InvalidValue" SG_ 1083 EDS_CanRollingCounterErr_FWD "";
BA_ "GenSigTimeoutTime_ALL" SG_ 1083 EDS_CanTimeoutErr_FWD 500;
BA_ "InvalidValue" SG_ 1083 EDS_CanTimeoutErr_FWD "";
BA_ "GenSigTimeoutTime_ALL" SG_ 1083 EDS_CrashFault_FWD 500;
BA_ "InvalidValue" SG_ 1083 EDS_CrashFault_FWD "";
BA_ "GenSigTimeoutTime_ALL" SG_ 1083 EDS_PCFSlightFault_FWD 500;
BA_ "InvalidValue" SG_ 1083 EDS_PCFSlightFault_FWD "";
BA_ "GenSigTimeoutTime_ALL" SG_ 1083 EDS_PCFSerFault_FWD 500;
BA_ "InvalidValue" SG_ 1083 EDS_PCFSerFault_FWD "";
BA_ "GenSigTimeoutTime_ALL" SG_ 1083 SECCAN_EDS_Error_FR_B 500;
BA_ "InvalidValue" SG_ 1083 SECCAN_EDS_Error_FR_B "";
BA_ "GenSigTimeoutTime_ALL" SG_ 1084 CHKSM_EDS_Error_RR_B 500;
BA_ "InvalidValue" SG_ 1084 CHKSM_EDS_Error_RR_B "";
BA_ "GenSigTimeoutTime_ALL" SG_ 1084 ALV_EDS_Error_RR_B 500;
BA_ "InvalidValue" SG_ 1084 ALV_EDS_Error_RR_B "Fh";
BA_ "GenSigTimeoutTime_ALL" SG_ 1084 EDS_iDcLnkOvCLimFail_RWD 500;
BA_ "InvalidValue" SG_ 1084 EDS_iDcLnkOvCLimFail_RWD "";
BA_ "GenSigTimeoutTime_ALL" SG_ 1084 EDS_MotBlockedFault_RWD 500;
BA_ "InvalidValue" SG_ 1084 EDS_MotBlockedFault_RWD "";
BA_ "GenSigTimeoutTime_ALL" SG_ 1084 EDS_RSLErr_RWD 500;
BA_ "InvalidValue" SG_ 1084 EDS_RSLErr_RWD "";
BA_ "GenSigTimeoutTime_ALL" SG_ 1084 EDS_MotTrqLimFault_RWD 500;
BA_ "InvalidValue" SG_ 1084 EDS_MotTrqLimFault_RWD "";
BA_ "GenSigTimeoutTime_ALL" SG_ 1084 EDS_VCUChksumFault_RWD 500;
BA_ "InvalidValue" SG_ 1084 EDS_VCUChksumFault_RWD "";
BA_ "GenSigTimeoutTime_ALL" SG_ 1084 EDS_IGBTFault_RWD 500;
BA_ "InvalidValue" SG_ 1084 EDS_IGBTFault_RWD "";
BA_ "GenSigTimeoutTime_ALL" SG_ 1084 EDS_CANBusoffFault_RWD 500;
BA_ "InvalidValue" SG_ 1084 EDS_CANBusoffFault_RWD "";
BA_ "GenSigTimeoutTime_ALL" SG_ 1084 EDS_TDrvBoardOvHiWarn_RWD 500;
BA_ "InvalidValue" SG_ 1084 EDS_TDrvBoardOvHiWarn_RWD "";
BA_ "GenSigTimeoutTime_ALL" SG_ 1084 EDS_TIGBTOvHiFault_RWD 500;
BA_ "InvalidValue" SG_ 1084 EDS_TIGBTOvHiFault_RWD "";
BA_ "GenSigTimeoutTime_ALL" SG_ 1084 EDS_TIGBTOvHiWarn_RWD 500;
BA_ "InvalidValue" SG_ 1084 EDS_TIGBTOvHiWarn_RWD "";
BA_ "GenSigTimeoutTime_ALL" SG_ 1084 EDS_IOHWABSampFail_RWD 500;
BA_ "InvalidValue" SG_ 1084 EDS_IOHWABSampFail_RWD "";
BA_ "GenSigTimeoutTime_ALL" SG_ 1084 EDS_EDSOpenFault_RWD 500;
BA_ "InvalidValue" SG_ 1084 EDS_EDSOpenFault_RWD "";
BA_ "GenSigTimeoutTime_ALL" SG_ 1084 EDS_MotorOpenFault_RWD 500;
BA_ "InvalidValue" SG_ 1084 EDS_MotorOpenFault_RWD "";
BA_ "GenSigTimeoutTime_ALL" SG_ 1084 EDS_EparkSampFail_RWD 500;
BA_ "InvalidValue" SG_ 1084 EDS_EparkSampFail_RWD "";
BA_ "GenSigTimeoutTime_ALL" SG_ 1084 EDS_EmacBlkdWarn_RWD 500;
BA_ "InvalidValue" SG_ 1084 EDS_EmacBlkdWarn_RWD "";
BA_ "GenSigTimeoutTime_ALL" SG_ 1084 EDS_VerMatchFailureErr_RWD 500;
BA_ "InvalidValue" SG_ 1084 EDS_VerMatchFailureErr_RWD "";
BA_ "GenSigTimeoutTime_ALL" SG_ 1084 EDS_DiashCirNoPsblErr_RWD 500;
BA_ "InvalidValue" SG_ 1084 EDS_DiashCirNoPsblErr_RWD "";
BA_ "GenSigTimeoutTime_ALL" SG_ 1084 EDS_OperOutdRngErr_RWD 500;
BA_ "InvalidValue" SG_ 1084 EDS_OperOutdRngErr_RWD "";
BA_ "GenSigTimeoutTime_ALL" SG_ 1084 EDS_PhaseLossFaultErr_RWD 500;
BA_ "InvalidValue" SG_ 1084 EDS_PhaseLossFaultErr_RWD "";
BA_ "GenSigTimeoutTime_ALL" SG_ 1084 EDS_CPLDFault_RWD 500;
BA_ "InvalidValue" SG_ 1084 EDS_CPLDFault_RWD "";
BA_ "GenSigTimeoutTime_ALL" SG_ 1084 EDS_CPLDFaultBaseSpd_RWD 500;
BA_ "InvalidValue" SG_ 1084 EDS_CPLDFaultBaseSpd_RWD "";
BA_ "GenSigTimeoutTime_ALL" SG_ 1084 EDS_IOHWABNen33Fail_RWD 500;
BA_ "InvalidValue" SG_ 1084 EDS_IOHWABNen33Fail_RWD "";
BA_ "GenSigTimeoutTime_ALL" SG_ 1084 EDS_HvMcuSlightFault_RWD 500;
BA_ "InvalidValue" SG_ 1084 EDS_HvMcuSlightFault_RWD "";
BA_ "GenSigTimeoutTime_ALL" SG_ 1084 EDS_HvMcuSevFault_RWD 500;
BA_ "InvalidValue" SG_ 1084 EDS_HvMcuSevFault_RWD "";
BA_ "GenSigTimeoutTime_ALL" SG_ 1084 EDS_EDSPhaSampHWFault_RWD 500;
BA_ "InvalidValue" SG_ 1084 EDS_EDSPhaSampHWFault_RWD "";
BA_ "GenSigTimeoutTime_ALL" SG_ 1084 EDS_IsOvHiErr_RWD 500;
BA_ "InvalidValue" SG_ 1084 EDS_IsOvHiErr_RWD "";
BA_ "GenSigTimeoutTime_ALL" SG_ 1084 EDS_CanRollingCounterErr_RWD 500;
BA_ "InvalidValue" SG_ 1084 EDS_CanRollingCounterErr_RWD "";
BA_ "GenSigTimeoutTime_ALL" SG_ 1084 EDS_CanTimeoutErr_RWD 500;
BA_ "InvalidValue" SG_ 1084 EDS_CanTimeoutErr_RWD "";
BA_ "GenSigTimeoutTime_ALL" SG_ 1084 EDS_CrashFault_RWD 500;
BA_ "InvalidValue" SG_ 1084 EDS_CrashFault_RWD "";
BA_ "GenSigTimeoutTime_ALL" SG_ 1084 EDS_PCFSlightFault_RWD 500;
BA_ "InvalidValue" SG_ 1084 EDS_PCFSlightFault_RWD "";
BA_ "GenSigTimeoutTime_ALL" SG_ 1084 EDS_PCFSerFault_RWD 500;
BA_ "InvalidValue" SG_ 1084 EDS_PCFSerFault_RWD "";
BA_ "GenSigTimeoutTime_ALL" SG_ 1084 SECCAN_EDS_Error_RR_B 500;
BA_ "InvalidValue" SG_ 1084 SECCAN_EDS_Error_RR_B "";
BA_ "GenSigTimeoutTime_ALL" SG_ 1093 RS_Sol_L 500;
BA_ "InvalidValue" SG_ 1093 RS_Sol_L "FFh";
BA_ "GenSigTimeoutTime_ALL" SG_ 1093 RS_Sol_R 500;
BA_ "InvalidValue" SG_ 1093 RS_Sol_R "FFh";
BA_ "GenSigTimeoutTime_ALL" SG_ 1093 RS_F_HUD_Sensor 500;
BA_ "InvalidValue" SG_ 1093 RS_F_HUD_Sensor "";
BA_ "GenSigTimeoutTime_ALL" SG_ 1093 RS_St_LampReq 500;
BA_ "InvalidValue" SG_ 1093 RS_St_LampReq "3h";
BA_ "GenSigTimeoutTime_ALL" SG_ 1093 RS_St_CurrentRain 500;
BA_ "InvalidValue" SG_ 1093 RS_St_CurrentRain "7h";
BA_ "GenSigTimeoutTime_ALL" SG_ 1093 RS_HUD_illuminance 500;
BA_ "InvalidValue" SG_ 1093 RS_HUD_illuminance "FFFFh";
BA_ "GenSigTimeoutTime_ALL" SG_ 1095 CHKSM_MHU_SET_CarMode 1000;
BA_ "InvalidValue" SG_ 1095 CHKSM_MHU_SET_CarMode "";
BA_ "GenSigTimeoutTime_ALL" SG_ 1095 ALV_MHU_SET_CarMode 1000;
BA_ "InvalidValue" SG_ 1095 ALV_MHU_SET_CarMode "Fh";
BA_ "GenSigTimeoutTime_ALL" SG_ 1095 MHU_Request_CarOFF 1000;
BA_ "InvalidValue" SG_ 1095 MHU_Request_CarOFF "3h";
BA_ "GenSigTimeoutTime_ALL" SG_ 1095 MHU_SET_ChildMode 1000;
BA_ "InvalidValue" SG_ 1095 MHU_SET_ChildMode "3h";
BA_ "GenSigTimeoutTime_ALL" SG_ 1095 MHU_SET_GameMode 1000;
BA_ "InvalidValue" SG_ 1095 MHU_SET_GameMode "3h";
BA_ "GenSigTimeoutTime_ALL" SG_ 1095 MHU_SET_KaraokeMode 1000;
BA_ "InvalidValue" SG_ 1095 MHU_SET_KaraokeMode "3h";
BA_ "GenSigStartValue" SG_ 1095 MHU_Req_StoppingMode 4;
BA_ "GenSigTimeoutTime_ALL" SG_ 1095 MHU_Req_StoppingMode 1000;
BA_ "InvalidValue" SG_ 1095 MHU_Req_StoppingMode "7h";
BA_ "GenSigTimeoutTime_ALL" SG_ 1095 MHU_SET_WashMode 1000;
BA_ "InvalidValue" SG_ 1095 MHU_SET_WashMode "3h";
BA_ "GenSigTimeoutTime_ALL" SG_ 1095 MHU_SET_StopMode 1000;
BA_ "InvalidValue" SG_ 1095 MHU_SET_StopMode "3h";
BA_ "GenSigTimeoutTime_ALL" SG_ 1095 MHU_AVH_Sw 1000;
BA_ "InvalidValue" SG_ 1095 MHU_AVH_Sw "3h";
BA_ "GenSigSendType" SG_ 1110 OP_WISW_SZL_LIN 3;
BA_ "InvalidValue" SG_ 1110 OP_WISW_SZL_LIN "";
BA_ "GenSigSendType" SG_ 1110 COMM_ERR_SZL_LIN 3;
BA_ "InvalidValue" SG_ 1110 COMM_ERR_SZL_LIN "";
BA_ "GenSigSendType" SG_ 1110 BCM_Wiper_Front_Status 3;
BA_ "InvalidValue" SG_ 1110 BCM_Wiper_Front_Status "";
BA_ "GenSigSendType" SG_ 1110 OP_WIPO_SZL_LIN 3;
BA_ "InvalidValue" SG_ 1110 OP_WIPO_SZL_LIN "";
BA_ "GenSigSendType" SG_ 1110 OP_COLS_SZL_LIN 3;
BA_ "InvalidValue" SG_ 1110 OP_COLS_SZL_LIN "";
BA_ "GenSigSendType" SG_ 1110 NOD_ERR_SZL_LIN 3;
BA_ "InvalidValue" SG_ 1110 NOD_ERR_SZL_LIN "";
BA_ "GenSigSendType" SG_ 1110 BCM_Wiper_Rear_Status 3;
BA_ "InvalidValue" SG_ 1110 BCM_Wiper_Rear_Status "3h";
BA_ "GenSigSendType" SG_ 1110 ALIV_WISW_SZL_LIN 3;
BA_ "InvalidValue" SG_ 1110 ALIV_WISW_SZL_LIN "Fh";
BA_ "GenSigTimeoutTime_ALL" SG_ 1139 POD_OBC_evt_SFT_MemFail 500;
BA_ "InvalidValue" SG_ 1139 POD_OBC_evt_SFT_MemFail "0";
BA_ "GenSigTimeoutTime_ALL" SG_ 1139 POD_OBC_evt_SFT_ADCFail 500;
BA_ "InvalidValue" SG_ 1139 POD_OBC_evt_SFT_ADCFail "0";
BA_ "GenSigTimeoutTime_ALL" SG_ 1139 POD_OBC_evt_SFT_ClockFail 500;
BA_ "InvalidValue" SG_ 1139 POD_OBC_evt_SFT_ClockFail "0";
BA_ "GenSigTimeoutTime_ALL" SG_ 1139 POD_OBC_evt_SFT_OpcodeFail 500;
BA_ "InvalidValue" SG_ 1139 POD_OBC_evt_SFT_OpcodeFail "0";
BA_ "GenSigTimeoutTime_ALL" SG_ 1139 POD_OBC_evt_SFT_PMICFail 500;
BA_ "InvalidValue" SG_ 1139 POD_OBC_evt_SFT_PMICFail "0";
BA_ "GenSigTimeoutTime_ALL" SG_ 1139 POD_OBC_evt_SFT_ExtWDGFail 500;
BA_ "InvalidValue" SG_ 1139 POD_OBC_evt_SFT_ExtWDGFail "0";
BA_ "GenSigTimeoutTime_ALL" SG_ 1139 POD_OBC_evt_SFT_PFMFail 500;
BA_ "InvalidValue" SG_ 1139 POD_OBC_evt_SFT_PFMFail "0";
BA_ "GenSigTimeoutTime_ALL" SG_ 1139 POD_OBC_evt_SOPT_Flt 500;
BA_ "InvalidValue" SG_ 1139 POD_OBC_evt_SOPT_Flt "0";
BA_ "GenSigTimeoutTime_ALL" SG_ 1139 POD_OBC_evt_Threscheck_Flt 500;
BA_ "InvalidValue" SG_ 1139 POD_OBC_evt_Threscheck_Flt "0";
BA_ "GenSigTimeoutTime_ALL" SG_ 1139 POD_OBC_evt_ExtMem_Flt 500;
BA_ "InvalidValue" SG_ 1139 POD_OBC_evt_ExtMem_Flt "0";
BA_ "GenSigTimeoutTime_ALL" SG_ 1139 POD_OBC_evt_SWData_Corrupt 500;
BA_ "InvalidValue" SG_ 1139 POD_OBC_evt_SWData_Corrupt "0";
BA_ "GenSigTimeoutTime_ALL" SG_ 1140 POD_GW_En_CLC_Fail 500;
BA_ "InvalidValue" SG_ 1140 POD_GW_En_CLC_Fail "0";
BA_ "GenSigTimeoutTime_ALL" SG_ 1140 POD_GW_ADC_Convert_Fail 500;
BA_ "InvalidValue" SG_ 1140 POD_GW_ADC_Convert_Fail "0";
BA_ "GenSigTimeoutTime_ALL" SG_ 1140 POD_GW_Intbus_CANSM_Fail 500;
BA_ "InvalidValue" SG_ 1140 POD_GW_Intbus_CANSM_Fail "0";
BA_ "GenSigTimeoutTime_ALL" SG_ 1140 POD_GW_Pubbus_CANSM_Fail 500;
BA_ "InvalidValue" SG_ 1140 POD_GW_Pubbus_CANSM_Fail "0";
BA_ "GenSigTimeoutTime_ALL" SG_ 1140 POD_GW_ECUM_KillAllReq 500;
BA_ "InvalidValue" SG_ 1140 POD_GW_ECUM_KillAllReq "0";
BA_ "GenSigTimeoutTime_ALL" SG_ 1140 POD_GW_ECUM_ConfigData_Fail 500;
BA_ "InvalidValue" SG_ 1140 POD_GW_ECUM_ConfigData_Fail "0";
BA_ "GenSigTimeoutTime_ALL" SG_ 1140 POD_GW_ECUM_ImproperCaller 500;
BA_ "InvalidValue" SG_ 1140 POD_GW_ECUM_ImproperCaller "0";
BA_ "GenSigTimeoutTime_ALL" SG_ 1140 POD_GW_ECUM_RAMchecked_Fail 500;
BA_ "InvalidValue" SG_ 1140 POD_GW_ECUM_RAMchecked_Fail "0";
BA_ "GenSigTimeoutTime_ALL" SG_ 1140 POD_GW_FEE_Erase_Fail 500;
BA_ "InvalidValue" SG_ 1140 POD_GW_FEE_Erase_Fail "0";
BA_ "GenSigTimeoutTime_ALL" SG_ 1140 POD_GW_FEE_InitGC_Fail 500;
BA_ "InvalidValue" SG_ 1140 POD_GW_FEE_InitGC_Fail "0";
BA_ "GenSigTimeoutTime_ALL" SG_ 1140 POD_GW_FEE_ReadGC_Fail 500;
BA_ "InvalidValue" SG_ 1140 POD_GW_FEE_ReadGC_Fail "0";
BA_ "GenSigTimeoutTime_ALL" SG_ 1140 POD_GW_FEE_GC_Trigger_Fail 500;
BA_ "InvalidValue" SG_ 1140 POD_GW_FEE_GC_Trigger_Fail "0";
BA_ "GenSigTimeoutTime_ALL" SG_ 1140 POD_GW_FEE_WriteGC_Fail 500;
BA_ "InvalidValue" SG_ 1140 POD_GW_FEE_WriteGC_Fail "0";
BA_ "GenSigTimeoutTime_ALL" SG_ 1140 POD_GW_FEE_InvalidReq 500;
BA_ "InvalidValue" SG_ 1140 POD_GW_FEE_InvalidReq "0";
BA_ "GenSigTimeoutTime_ALL" SG_ 1140 POD_GW_FEE_Read_Fail 500;
BA_ "InvalidValue" SG_ 1140 POD_GW_FEE_Read_Fail "0";
BA_ "GenSigTimeoutTime_ALL" SG_ 1140 POD_GW_FEE_UnconfigBLK_Exceed 500;
BA_ "InvalidValue" SG_ 1140 POD_GW_FEE_UnconfigBLK_Exceed "0";
BA_ "GenSigTimeoutTime_ALL" SG_ 1140 POD_GW_FEE_Write_Fail 500;
BA_ "InvalidValue" SG_ 1140 POD_GW_FEE_Write_Fail "0";
BA_ "GenSigTimeoutTime_ALL" SG_ 1140 POD_GW_FEE_OverWriteCycle 500;
BA_ "InvalidValue" SG_ 1140 POD_GW_FEE_OverWriteCycle "0";
BA_ "GenSigTimeoutTime_ALL" SG_ 1140 POD_GW_Fls_Compared_Fail 500;
BA_ "InvalidValue" SG_ 1140 POD_GW_Fls_Compared_Fail "0";
BA_ "GenSigTimeoutTime_ALL" SG_ 1140 POD_GW_Fls_Erase_Fail 500;
BA_ "InvalidValue" SG_ 1140 POD_GW_Fls_Erase_Fail "0";
BA_ "GenSigTimeoutTime_ALL" SG_ 1140 POD_GW_Fls_Read_Fail 500;
BA_ "InvalidValue" SG_ 1140 POD_GW_Fls_Read_Fail "0";
BA_ "GenSigTimeoutTime_ALL" SG_ 1140 POD_GW_Fls_UnexpectedFlashID 500;
BA_ "InvalidValue" SG_ 1140 POD_GW_Fls_UnexpectedFlashID "0";
BA_ "GenSigTimeoutTime_ALL" SG_ 1140 POD_GW_Fls_Write_Fail 500;
BA_ "InvalidValue" SG_ 1140 POD_GW_Fls_Write_Fail "0";
BA_ "GenSigTimeoutTime_ALL" SG_ 1140 POD_GW_MCU_CCU6_CLC_DisableErr 500;
BA_ "InvalidValue" SG_ 1140 POD_GW_MCU_CCU6_CLC_DisableErr "0";
BA_ "GenSigTimeoutTime_ALL" SG_ 1140 POD_GW_MCU_CCU6_CLC_EnableErr 500;
BA_ "InvalidValue" SG_ 1140 POD_GW_MCU_CCU6_CLC_EnableErr "0";
BA_ "GenSigTimeoutTime_ALL" SG_ 1140 POD_GW_CCUCON_UpdateErr 500;
BA_ "InvalidValue" SG_ 1140 POD_GW_CCUCON_UpdateErr "0";
BA_ "GenSigTimeoutTime_ALL" SG_ 1140 POD_GW_MCU_CLK_Fail 500;
BA_ "InvalidValue" SG_ 1140 POD_GW_MCU_CLK_Fail "0";
BA_ "GenSigTimeoutTime_ALL" SG_ 1140 POD_GW_MCU_CONVCTRLCLC_DisErr 500;
BA_ "InvalidValue" SG_ 1140 POD_GW_MCU_CONVCTRLCLC_DisErr "0";
BA_ "GenSigTimeoutTime_ALL" SG_ 1140 POD_GW_MCU_CONVCTRLCLC_EnableErr 500;
BA_ "InvalidValue" SG_ 1140 POD_GW_MCU_CONVCTRLCLC_EnableErr "0";
BA_ "GenSigTimeoutTime_ALL" SG_ 1140 POD_GW_MCU_GPT12_CLC_DisableErr 500;
BA_ "InvalidValue" SG_ 1140 POD_GW_MCU_GPT12_CLC_DisableErr "0";
BA_ "GenSigTimeoutTime_ALL" SG_ 1140 POD_GW_MCU_GPT12_CLC_EnableErr 500;
BA_ "InvalidValue" SG_ 1140 POD_GW_MCU_GPT12_CLC_EnableErr "0";
BA_ "GenSigTimeoutTime_ALL" SG_ 1140 POD_GW_MCU_GTM_CLC_DisableErr 500;
BA_ "InvalidValue" SG_ 1140 POD_GW_MCU_GTM_CLC_DisableErr "0";
BA_ "GenSigTimeoutTime_ALL" SG_ 1140 POD_GW_MCU_GTM_CLC_EnableErr 500;
BA_ "InvalidValue" SG_ 1140 POD_GW_MCU_GTM_CLC_EnableErr "0";
BA_ "GenSigTimeoutTime_ALL" SG_ 1140 POD_GW_MCU_Oscillator_Fail 500;
BA_ "InvalidValue" SG_ 1140 POD_GW_MCU_Oscillator_Fail "0";
BA_ "GenSigTimeoutTime_ALL" SG_ 1140 POD_GW_MCU_PeriPLL_Lock_Loss 500;
BA_ "InvalidValue" SG_ 1140 POD_GW_MCU_PeriPLL_Lock_Loss "0";
BA_ "GenSigTimeoutTime_ALL" SG_ 1140 POD_GW_MCU_PeriPLL_Timeout_Fail 500;
BA_ "InvalidValue" SG_ 1140 POD_GW_MCU_PeriPLL_Timeout_Fail "0";
BA_ "GenSigTimeoutTime_ALL" SG_ 1140 POD_GW_MCU_PMSCWR_UpdateErr 500;
BA_ "InvalidValue" SG_ 1140 POD_GW_MCU_PMSCWR_UpdateErr "0";
BA_ "GenSigTimeoutTime_ALL" SG_ 1140 POD_GW_MCU_SysPLL_LockLoss 500;
BA_ "InvalidValue" SG_ 1140 POD_GW_MCU_SysPLL_LockLoss "0";
BA_ "GenSigTimeoutTime_ALL" SG_ 1140 POD_GW_MCU_SysPLL_Timeout_Fail 500;
BA_ "InvalidValue" SG_ 1140 POD_GW_MCU_SysPLL_Timeout_Fail "0";
BA_ "GenSigTimeoutTime_ALL" SG_ 1140 POD_GW_NVM_Integrity_Fail 500;
BA_ "InvalidValue" SG_ 1140 POD_GW_NVM_Integrity_Fail "0";
BA_ "GenSigTimeoutTime_ALL" SG_ 1140 POD_GW_NVM_Loss_Redundancy_Fail 500;
BA_ "InvalidValue" SG_ 1140 POD_GW_NVM_Loss_Redundancy_Fail "0";
BA_ "GenSigTimeoutTime_ALL" SG_ 1140 POD_GW_NVM_Queue_OverFlow 500;
BA_ "InvalidValue" SG_ 1140 POD_GW_NVM_Queue_OverFlow "0";
BA_ "GenSigTimeoutTime_ALL" SG_ 1140 POD_GW_NVM_Request_Fail 500;
BA_ "InvalidValue" SG_ 1140 POD_GW_NVM_Request_Fail "0";
BA_ "GenSigTimeoutTime_ALL" SG_ 1140 POD_GW_NVM_Verify_Fail 500;
BA_ "InvalidValue" SG_ 1140 POD_GW_NVM_Verify_Fail "0";
BA_ "GenSigTimeoutTime_ALL" SG_ 1140 POD_GW_NVM_WriteProtected 500;
BA_ "InvalidValue" SG_ 1140 POD_GW_NVM_WriteProtected "0";
BA_ "GenSigTimeoutTime_ALL" SG_ 1140 POD_GW_NVM_WrongBlockID 500;
BA_ "InvalidValue" SG_ 1140 POD_GW_NVM_WrongBlockID "0";
BA_ "GenSigTimeoutTime_ALL" SG_ 1140 POD_GW_SPI_HWError 500;
BA_ "InvalidValue" SG_ 1140 POD_GW_SPI_HWError "0";
BA_ "GenSigTimeoutTime_ALL" SG_ 1140 POD_GW_DCDC_EventMatrix_mia 500;
BA_ "InvalidValue" SG_ 1140 POD_GW_DCDC_EventMatrix_mia "0";
BA_ "GenSigTimeoutTime_ALL" SG_ 1140 POD_GW_OBC_EventMatrix_mia 500;
BA_ "InvalidValue" SG_ 1140 POD_GW_OBC_EventMatrix_mia "0";
BA_ "GenSigTimeoutTime_ALL" SG_ 1140 POD_GW_DCFC_EventMatrix_mia 500;
BA_ "InvalidValue" SG_ 1140 POD_GW_DCFC_EventMatrix_mia "0";
BA_ "GenSigTimeoutTime_ALL" SG_ 1140 POD_GW_Public_Busoff 500;
BA_ "InvalidValue" SG_ 1140 POD_GW_Public_Busoff "0";
BA_ "GenSigTimeoutTime_ALL" SG_ 1140 POD_GW_Private_Busoff 500;
BA_ "InvalidValue" SG_ 1140 POD_GW_Private_Busoff "0";
BA_ "GenSigTimeoutTime_ALL" SG_ 1140 POD_GW_VBAT_Low 500;
BA_ "InvalidValue" SG_ 1140 POD_GW_VBAT_Low "0";
BA_ "GenSigTimeoutTime_ALL" SG_ 1140 POD_GW_VBat_High 500;
BA_ "InvalidValue" SG_ 1140 POD_GW_VBat_High "0";
VAL_ 568 EDS_EPARK_STS_FWD 0 "unlock" 1 "unlocking" 2 "lock" 3 "locking";
VAL_ 568 EDS_EPARK_ERR_FWD 0 "normal" 1 "error";
VAL_ 568 EDS_disxhg_st_FWD 0 "No Active Discharge" 1 "Active Discharge" 2 "Failed Active Discharge" 3 "Finished Active Discharge";
VAL_ 568 EDS_tempValid_FWD 0 "invalid" 1 "valid";
VAL_ 568 EDS_MotTemp_MEAS_EDS_valid_FWD 0 "invalid" 1 "valid";
VAL_ 568 EDS_ActiveHeating_state 0 "Disable" 1 "Enable";
VAL_ 568 EDS_DampingState_FWD 0 "Damping disable" 1 "Damping active";
VAL_ 568 EDS_IGBTState_FWD 0 "FreeWheel" 1 "Up Bridge ASC" 2 "Down Bridge ASC" 3 "Normal Run";
VAL_ 569 EDS_disxhg_st_RWD 0 "No Active Discharge" 1 "Active Discharge" 2 "Failed Active Discharge" 3 "Finished Active Discharge";
VAL_ 569 EDS_tempValid_RWD 0 "invalid" 1 "valid";
VAL_ 569 EDS_MotTemp_MEAS_EDS_valid_RWD 0 "invalid" 1 "valid";
VAL_ 569 EDS_DampingState_RWD 0 "Damping disable" 1 "Damping active";
VAL_ 569 EDS_IGBTState_RWD 0 "FreeWheel" 1 "Up Bridge ASC" 2 "Down Bridge ASC" 3 "Normal Run";
VAL_ 570 IDB_WheelDirection_FR 0 "Standstill" 1 "Forward" 2 "Backward" 3 "Invalid";
VAL_ 570 IDB_WheelDirection_FL 0 "Standstill" 1 "Forward" 2 "Backward" 3 "Invalid";
VAL_ 571 IDB_WheelDirection_RR 0 "Standstill" 1 "Forward" 2 "Backward" 3 "Invalid";
VAL_ 571 IDB_WheelDirection_RL 0 "Standstill" 1 "Forward" 2 "Backward" 3 "Invalid";
VAL_ 572 IDB_DPBAvlSts 0 "Available" 1 "Not available";
VAL_ 572 IDB_ReqApplyEPBVldtn 0 "Valid" 1 "Invalid";
VAL_ 572 IDB_ReqApplyEPB 0 "Not request" 1 "Request to release" 2 "Request to apply" 3 "Reserved";
VAL_ 572 IDB_DiagMode 0 "Normal mode" 1 "Diagnosis mode";
VAL_ 572 IDB_DPBActvSts 0 "Inactive" 1 "Active";
VAL_ 572 IDB_CircPresVldty 0 "Valid" 1 "Invalid";
VAL_ 572 IDB_BrkPedlValVldty 0 "Valid" 1 "Invalid";
VAL_ 573 IDB_FrntLeEstimdWhlPresVldty 0 "Valid" 1 "Invalid";
VAL_ 573 IDB_FrntRiEstimdWhlPresVldty 0 "Valid" 1 "Invalid";
VAL_ 573 IDB_ReLeEstimdWhlPresVldty 0 "Valid" 1 "Invalid";
VAL_ 573 IDB_ReRiEstimdWhlPresVldty 0 "Valid" 1 "Invalid";
VAL_ 574 RCU_EPB_DynamicApplySta 0 "Not active" 1 "RWU active" 2 "Degrade apply" 3 "Reserved";
VAL_ 574 RCU_EPB_WarnLampSta 0 "No Indication" 1 "Continuous Indication" 2 "Flash Rate 1 Indication" 3 "Reserved";
VAL_ 574 RCU_EPB_ParkLampSta 0 "No Indication" 1 "Continuous Indication" 2 "Flash Rate 1 Indication" 3 "Reserved";
VAL_ 574 RCU_EPB_SwitchSta 0 "Neutral" 1 "Release" 2 "Apply" 3 "Invalid";
VAL_ 574 RCU_EPB_DecelReqSts 0 "Not request" 1 "Request";
VAL_ 574 RCU_EPB_SystemState 0 "Unknown" 1 "Released" 2 "Applied" 3 "Applying in progress without switch" 4 "Releasing in progress without switch" 5 "Dynamic braking via EPB" 6 "Releasing in progress by switch" 7 "Applying in progress by switch";
VAL_ 574 RCU_PBCInApplyRelsReq 0 "None" 1 "ParkApply" 2 "HoldApply" 3 "RollerbenchApply" 4 "Release" 5 "DynamicApply" 6 "PadAdjustment" 7 "reserved";
VAL_ 574 RCU_PBCRollrBenchActv 0 "Inactive" 1 "Active";
VAL_ 574 RCU_EPB_FltSts 0 "Not Valid" 1 "No Error" 2 "Initializtion" 3 "DiagSession" 4 "Temporary Fail" 5 "Permananet Fail";
VAL_ 574 RCU_ReqBrkLiOn 0 "Inactive" 1 "Active";
VAL_ 581 BMS_ProbeNumMaxCellTemp 0 "Invalid" 62 "Error" 63 "Invalid";
VAL_ 581 BMS_ProbeNumMinCellTemp 0 "Invalid" 62 "Error" 63 "Invalid";
VAL_ 596 QU_AVL_RPM_WHL_RLH 1 "Signal value is valid and secured and checked for plausibility" 2 "Reserved" 3 "Reserved" 4 "Substitute value is set in the useful signal" 6 "Signal value is invalid (Electrical fault, can be repaired)" 7 "Reserved" 8 "initialization" 9 "Reserved" 10 "Reserved" 11 "Signal quality or monitoring restricted, state / status temporary" 12 "Substitute value is set in the useful signal State / status temporary" 14 "Signal value is invalid (Electrical fault, can not repaired)" 15 "Signal invalid";
VAL_ 596 QU_AVL_RPM_WHL_RRH 1 "Signal value is valid and secured and checked for plausibility" 2 "Reserved" 3 "Reserved" 4 "Substitute value is set in the useful signal" 6 "Signal value is invalid (Electrical fault, can be repaired)" 7 "Reserved" 8 "initialization" 9 "Reserved" 10 "Reserved" 11 "Signal quality or monitoring restricted, state / status temporary" 12 "Substitute value is set in the useful signal State / status temporary" 14 "Signal value is invalid (Electrical fault, can not repaired)" 15 "Signal invalid";
VAL_ 597 QU_AVL_RPM_WHL_FLH 1 "Signal value is valid and secured and checked for plausibility" 2 "Reserved" 3 "Reserved" 4 "Substitute value is set in the useful signal" 6 "Signal value is invalid (Electrical fault, can be repaired)" 7 "Reserved" 8 "initialization" 9 "Reserved" 10 "Reserved" 11 "Signal quality or monitoring restricted, state / status temporary" 12 "Substitute value is set in the useful signal State / status temporary" 14 "Signal value is invalid (Electrical fault, can not repaired)" 15 "Signal invalid";
VAL_ 597 QU_AVL_RPM_WHL_FRH 1 "Signal value is valid and secured and checked for plausibility" 2 "Reserved" 3 "Reserved" 4 "Substitute value is set in the useful signal" 6 "Signal value is invalid (Electrical fault, can be repaired)" 7 "Reserved" 8 "initialization" 9 "Reserved" 10 "Reserved" 11 "Signal quality or monitoring restricted, state / status temporary" 12 "Substitute value is set in the useful signal State / status temporary" 14 "Signal value is invalid (Electrical fault, can not repaired)" 15 "Signal invalid";
VAL_ 608 VCU_IDB_Available 0 "Available" 1 "Not available" ;
VAL_ 608 VCU_IDB_ControledRes 0 "Inactive" 1 "Active" ;
VAL_ 609 VCU_enableFC 0 "Request OPEN" 1 "Request CLOSE";
VAL_ 609 VCU_enableOBC 0 "OBC_OFF" 1 "OBC_ON_NORMAL" 2 "OBC_ON_VOLTAGE";
VAL_ 610 BMS_statusHVIL 0 "BMS_HVIL_NORMAL" 1 "BMS_HVIL_FAULT";
VAL_ 714 MHU_STAT_CoolantLevelStatus 0 "Normal condition" 1 "Low level condition" 2 "Reserved" 3 "Signal Invalid";
VAL_ 720 FCAM_AESA_DoorUnlock_Req 0 "No request" 1 "Requested" ;
VAL_ 720 FCAM_AESA_ECALL_Req 0 "No request" 1 "Requested" ;
VAL_ 720 FCAM_AESA_Status 0 "Not active" 1 "Decelerating" 2 "Target following" 3 "Reserved" ;
VAL_ 760 DISP_DATE_WDAY 1 "Monday" 2 "Tuesday" 3 "Wednesday" 4 "Thursday" 5 "Friday" 6 "Saturday" 7 "Sunday" 15 "Signal invalid";
VAL_ 760 ST_DISP_CTI_DATE 0 "data not valid" 1 "data valid" 3 "UTC" 5 "winter time" 6 "Manually set time" 7 "summer time" 15 "signal invalid";
VAL_ 768 CCU_STAT_SyncClimateZone 0 "OFF" 1 "ON" 2 "Reserved" 3 "Signal invalid";
VAL_ 768 CCU_STAT_Auto 0 "OFF" 1 "ON" 2 "Reserved" 3 "Signal invalid";
VAL_ 768 CCU_STAT_Aircondition 0 "OFF" 1 "ON" 2 "Reserved" 3 "Signal invalid";
VAL_ 768 CCU_STAT_IonButton 0 "OFF" 1 "ON" 2 "Reserved" 3 "Signal invalid";
VAL_ 768 CCU_STAT_MaxAc 0 "OFF" 1 "ON" 2 "Reserved" 3 "Signal invalid";
VAL_ 768 CCU_STAT_OnOff 0 "OFF" 1 "ON" 2 "Reserved" 3 "Signal invalid";
VAL_ 768 CCU_STAT_FanSpeed 0 "OFF" 1 "Level 1" 2 "Level 2" 3 "Level 3" 4 "Level 4" 5 "Level 5" 6 "Level 6" 7 "Reserved" 8 "Reserved" 9 "Reserved" 10 "Reserved" 11 "Reserved" 12 "Reserved" 13 "Reserved" 14 "Reserved" 15 "Signal invalid";
VAL_ 768 CCU_STAT_RecircFlap 0 "Inside" 1 "Outside" 2 "Auto" 3 "Signal invalid";
VAL_ 768 CCU_STAT_FlapPos 0 "OFF" 1 "Vent" 2 "Vent/Foot" 3 "Foot" 4 "Foot/Defrost" 5 "Defrost" 6 "Default" 7 "Signal invalid";
VAL_ 768 CCU_STAT_Defrost 0 "OFF" 1 "ON" 2 "Reserved" 3 "Signal invalid";
VAL_ 768 CCU_STAT_PTC_Heater 0 "OFF" 1 "Stage 1" 2 "Stage 2" 3 "Stage 3" 4 "Reserved" 5 "Reserved" 6 "Reserved" 7 "Signal invalid";
VAL_ 773 CcuHtrOnOffSts 0 "HV PTC off / HV_PTC_OFF" 1 "HV PTC on / HV_PTC_ON" 2 "HV PTC degraded / HV_PTC_DEG" 3 "HV PTC stopped / HV_PTC_STOP" 4 "HV PTC shutdown / HV_PTC_SHUTDOWN" 5 "HV PTC shorted / HV_PTC_SHORTED" 6 "HV PTC reset not possible / HV_PTC_NO_RESET" 7 "SNA";
VAL_ 773 EcompOnOffSts 0 "Off" 1 "On" 2 "Reserved" 3 "Signal invalid";
VAL_ 774 CCU_EcompOnOffRequest 0 "Off" 1 "On" 2 "Reserved" 3 "Signal invalid";
VAL_ 774 CCU_HtrOnOffRequest 0 "Off" 1 "On" 2 "Reserved" 3 "Signal invalid";
VAL_ 787 POD_statusOBC 0 "OBC_OFF" 1 "OBC_STANDBY" 2 "OBC_ON_NORMAL" 3 "OBC_ON_VOLTAGE" 4 "OBC_DEGRADED" 5 "OBC_FAULT_SHUTDOWN" 6 "OBC_EMERGENCY_SHUTDOWN" 7 "OBC_STS_SNA";
VAL_ 803 POD_phaseACInput 0 "Not Used" 1 "AC 1 phase input" 2 "Not used" 3 "AC 3 phase input";
VAL_ 806 POD_statusDCDC 0 "DCDC_OFF" 1 "DCDC_STANDBY" 2 "DCDC_ON" 3 "DCDC_RESERVED" 4 "DCDC_DEGRADED" 5 "DCDC_FAULT_SHUTDOWN" 6 "DCDC_EMERGENCY_SHUTDOWN" 7 "DCDC_STS_SNA";
VAL_ 807 POD_statusFCContactors 0 "FC_CONTACTORS_OPEN" 1 "FC_CONTACTORS_CLOSING" 2 "FC_CONTACTRORS_CLOSED" 3 "FC_CONTACTORS_OPENING" 4 "FC_CONTACTORS_WELDED" 5 "FC_CONTACTORS_FAULT" 7 "FC_CONTACTORS_SNA";
VAL_ 816 ST_FLLV_FUTA_SPAR 0 "No active" 1 "Active" 2 "Reserved" 3 "Signal invalid";
VAL_ 840 EDS_HVIL_STS_FWD 0 "Closed" 1 "Open" 2 "short to battery" 3 "short to ground";
VAL_ 841 EDS_HVIL_STS_RWD 0 "Closed" 1 "Open" 2 "short to battery" 3 "short to ground";
VAL_ 885 BMS_PreChgRelay_ERR 0 "error" 1 "normal";
VAL_ 885 BMS_TotalNegRelay_ERR 0 "Error" 1 "normal";
VAL_ 885 BMS_MainPosRelay_ERR 0 "Error" 1 "normal";
VAL_ 885 BMS_MainPosRelay_STS 0 "reserved" 1 "open" 2 "closed" 3 "stuck closed" 4 "stuck open";
VAL_ 885 BMS_PreChgRelay_STS 0 "reserved" 1 "open" 2 "closed" 3 "stuck closed" 4 "stuck open";
VAL_ 885 BMS_TotalNegRelay_STS 0 "reserved" 1 "open" 2 "closed" 3 "stuck closed" 4 "stuck open";
VAL_ 895 EPS2_TorqSensorSts 0 "Valid" 1 "Invalid";
VAL_ 895 EPS2_SteeringTorque 4095 "Invalid";
VAL_ 895 EPS2_Mode 0 "full assist" 1 "low assist" 2 "no assist" 3 " Invalid";
VAL_ 897 ACM_Seat_Occupancy_Passenger 0 "Seat_Not_Occupied" 1 "Seat Occupied" 2 "Not_Available" 3 "Failure";
VAL_ 897 ACM_Seat_Occupancy_2nd_Row_Dri 0 "Seat_Not_Occupied" 1 "Seat Occupied" 2 "Not_Available" 3 "Failure";
VAL_ 897 ACM_Seat_Occupancy_2nd_Row_Pas 0 "Seat_Not_Occupied" 1 "Seat Occupied" 2 "Not_Available" 3 "Failure";
VAL_ 897 ACM_Seat_Occupancy_2nd_Row_Mid 0 "Seat_Not_Occupied" 1 "Seat Occupied" 2 "Not_Available" 3 "Failure";
VAL_ 897 ACM_Seat_Belt_Status_Passenger 0 "Not_buckled" 1 "Buckled" 2 "Not_Available" 3 "Failure";
VAL_ 897 ACM_Seat_Belt_Status_Driver 0 "Not_buckled" 1 "Buckled" 2 "Not_Available" 3 "Failure";
VAL_ 897 ACM_Seat_Belt_Status_2nd_Row_Dri 0 "Not_buckled" 1 "Buckled" 2 "Not_Available" 3 "Failure";
VAL_ 897 ACM_Seat_Belt_Status_2nd_Row_Mid 0 "Not_buckled" 1 "Buckled" 2 "Not_Available" 3 "Failure";
VAL_ 897 ACM_Seat_Belt_Status_2nd_Row_Pas 0 "Not_buckled" 1 "Buckled" 2 "Not_Available" 3 "Failure";
VAL_ 905 VCU_IMMO_Sts 0 "init" 1 "pass" 2 "failed";
VAL_ 937 VCU_Pump_2_Stt 0 "OFF" 1 "ON" 2 "Fault" 3 "Reserve";
VAL_ 937 VCU_Pump_1_Stt 0 "OFF" 1 "ON" 2 "Fault" 3 "Reserve";
VAL_ 992 VCU_RunningRange_chrg_estSts 0 "Not ready" 1 "Processing" 2 "Estimated" 3 "Failed";
VAL_ 992 VCU_HVbatSoc_charged_estStatus 0 "Not ready" 1 "Processing" 2 "Estimated" 3 "Failed";
VAL_ 993 VCU_SetCruiseSpd 255 "Signal Invalid";
VAL_ 993 VCU_CruiseCtrlSts 0 "OFF" 1 "Standby" 2 "Active" 3 "Override" 4 "Fault" 5 "Reserved" 6 "Reserved" ;
VAL_ 993 VCU_MHU_Ack_ChgSche_stt 0 "Charging Schedule Enable" 1 "Charging Schedule Disable" 2 "Reserved" 3 "Signal Invalid";
VAL_ 993 VCU_ValetMode_sts 0 "Inactive" 1 "Active" 255 "Invalid";
VAL_ 1015 MFS_VoiceRecognitionOn_Off 0 "Button not Pressed" 1 "Short Press" 2 "Long Press" 3 "Reserved" 4 "Signal invalid";
VAL_ 1015 MFS_ISAControl 0 "Button not Pressed" 1 "Short Press" 2 "Long Press" 3 "Signal invalid";
VAL_ 1015 MFS_CruiseSpeedIncrease 0 "Button not Pressed" 1 "Short Press" 2 "Long Press" 3 "Reserved" 4 "Signal invalid";
VAL_ 1015 MFS_TelephoneCall_EndCall 0 "Button not Pressed" 1 "Short Press" 2 "Long Press" 3 "Reserved" 4 "Signal invalid";
VAL_ 1015 MFS_LKAControl 0 "Button not Pressed" 1 "Short Press" 2 "Long Press" 3 "Signal invalid";
VAL_ 1015 MFS_CruiseGapIncrease 0 "Button not Pressed" 1 "Short Press" 2 "Long Press" 3 "Reserved" 4 "Signal invalid";
VAL_ 1015 MFS_CruiseOn_Off 0 "Button not Pressed" 1 "Short Press" 2 "Long Press" 3 "Reserved" 4 "Signal invalid";
VAL_ 1015 MFS_CruiseGapDecrease 0 "Button not Pressed" 1 "Short Press" 2 "Long Press" 3 "Reserved" 4 "Signal invalid";
VAL_ 1015 MFS_CAN_RESControl 0 "Button not Pressed, " 1 "Short Press" 2 "Long Press" 3 "Reserved";
VAL_ 1015 MFS_CruiseSpeedDecrease 0 "Button not Pressed" 1 "Short Press" 2 "Long Press" 3 "Reserved" 4 "Signal invalid";
VAL_ 1015 MFS_SourseControl 0 "Button not Pressed" 1 "Short Press" 2 "Long Press" 3 "Reserved" 4 "Signal invalid";
VAL_ 1015 MFS_UpControl 0 "Button not Pressed" 1 "Short Press" 2 "Long Press" 3 "Reserved" 4 "Signal invalid";
VAL_ 1015 MFS_DownControl 0 "Button not Pressed" 1 "Short Press" 2 "Long Press" 3 "Reserved" 4 "Signal invalid";
VAL_ 1015 MFS_LeftControl 0 "Button not Pressed" 1 "Short Press" 2 "Long Press" 3 "Reserved" 4 "Signal invalid";
VAL_ 1015 MFS_Failure 0 "No Error" 1 "Error";
VAL_ 1015 MFS_RightControl 0 "Button not Pressed" 1 "Short Press" 2 "Long Press" 3 "Reserved" 4 "Signal invalid";
VAL_ 1015 MFS_OK_Control 0 "Button not Pressed" 1 "Short Press" 2 "Long Press" 3 "Reserved" 4 "Signal invalid";
VAL_ 1027 MHU_AutoP_Setting 3 "Signal Invalid" 2 "Reserved" 1 "OFF" 0 "ON" ;
VAL_ 1027 MHU_VCU_CreepDisable_stt 0 "No request" 1 "Creep Disable request";
VAL_ 1027 MHU_BrakeRegenMode 0 "HIGH" 1 "MID" 2 "LOW" 3 "OFF";
VAL_ 1027 MHU_ChargeScheduleSet 0 "disable" 1 "Enable" 2 "No effect" 3 "Invalid";
VAL_ 1027 MHU_ChargingRequest 0 "Stop charging" 1 "Start charging" 2 "Pause charging" 3 "No effect";
VAL_ 1027 MHU_ChgPort_Open_req 0 "No request" 1 "Requesting" 2 "Reserved" 3 "Signal invalid";
VAL_ 1027 MHU_SET_DrivingModeSwitch 0 "NORMAL" 1 "ECO" 2 "SPORT" 3 "Signal invalid";
VAL_ 1027 MHU_ValetMode_Activation 0 "Inactive" 1 "Active" 2 "No effect" 255 "Invalid";
VAL_ 1027 MHU_SET_ActivePreCondition 0 "OFF" 1 "ON" 2 "Reserved" 3 "Reserved";
VAL_ 1027 MHU_SpdLim_Override 0 "OFF" 1 "10km/h" 2 "20km/h" 3 "30km/h" 4 "Reserved" 5 "Invalid";
VAL_ 1029 MHU_SET_CCUF_FrontDefrost 0 "Not pressed" 1 "Pressed" 2 "Reserved" 3 "Signal invalid";
VAL_ 1074 MHU_FOTA_State 0 "INIT" 1 "NORMAL" 2 "FOTA FLASHING" 3 "FOTA-SUSPENDED" 4 "FAIL-SAFE-ERROR" 5 "SHUTDOWN" 6 "REMOTE DIAGNOSTICS" 7 "Invalid";
VAL_ 1079 VCU_SpdLimiterSts 0 "OFF" 1 "Standby" 2 "Active" 3 "Override" 4 "Fault" 5 "Reserved" 6 "Reserved" ;
VAL_ 1079 VCU_LimiterSpeed 255 "Signal Invalid";
VAL_ 1079 VCU_SpdLim_OverrideSts 0 "OFF" 1 "10km/h" 2 "20km/h" 3 "30km/h" 4 "Reserved" 5 "Invalid";
VAL_ 1080 EDS_FailGrade_ERR_FWD 0 "No fault" 1 "First-Level warning" 2 "Second Fault Limited power" 3 "Third Fault Limp" 4 "Forth Fault, ZeroTorque" 5 "Fifth Fault, Delayed power off" 6 "Invaild" 7 "Invaild";
VAL_ 1080 EDS_MotOverTempAlarm_FWD 0 "Normal" 1 "Error";
VAL_ 1080 EDS_MotOverTempFault_FWD 0 "Normal" 1 "Error";
VAL_ 1080 EDS_MotTempSenFault_FWD 0 "Normal" 1 "Error";
VAL_ 1080 EDS_EDSOverTempUFault_FWD 0 "Normal" 1 "Error";
VAL_ 1080 EDS_EDSOverTempVFault_FWD 0 "Normal" 1 "Error";
VAL_ 1080 EDS_EDSOverTempWFault_FWD 0 "Normal" 1 "Error";
VAL_ 1080 EDS_EDSOverTempAlarm_FWD 0 "Normal" 1 "Error";
VAL_ 1080 EDS_TCoolantOvHi_FWD 0 "Normal" 1 "Error";
VAL_ 1080 EDS_EDSTempCmpAlarm_FWD 0 "Normal" 1 "Error";
VAL_ 1080 EDS_EDSPhaOvCurentHWFault_FWD 0 "Normal" 1 "Error";
VAL_ 1080 EDS_EDSphaOffCalFault_FWD 0 "Normal" 1 "Error";
VAL_ 1080 EDS_EDSOverIdcLnkAlarm_FWD 0 "Normal" 1 "Error";
VAL_ 1080 EDS_EDSHVOverVoltageAlarm_FWD 0 "Normal" 1 "Error";
VAL_ 1080 EDS_EDSHVOverVoltageFault_FWD 0 "Normal" 1 "Error";
VAL_ 1080 EDS_EDSHVUnderVoltageAlarm_FWD 0 "Normal" 1 "Error";
VAL_ 1080 EDS_EDSHVUnderVoltageFault_FWD 0 "Normal" 1 "Error";
VAL_ 1080 EDS_RunToDischaErr_FWD 0 "Normal" 1 "Error";
VAL_ 1080 EDS_12VOverVoltageAlarm_FWD 0 "Normal" 1 "Error";
VAL_ 1080 EDS_12VUnderVoltageAlarm_FWD 0 "Normal" 1 "Error";
VAL_ 1080 EDS_MotOverAlarm_FWD 0 "Normal" 1 "Error";
VAL_ 1080 EDS_MotOverFault_FWD 0 "Normal" 1 "Error";
VAL_ 1080 EDS_ResolverOffsetAngle_FWD 0 "Normal" 1 "Error";
VAL_ 1081 EDS_FailGrade_ERR_RWD 0 "No fault" 1 "First-Level warning" 2 "Second Fault Limited power" 3 "Third Fault, Limp" 4 "Forth Fault, ZeroTorque" 5 "Fifth Fault, Delayed power off" 6 "Invaild" 7 "Invaild";
VAL_ 1081 EDS_MotOverTempAlarm_RWD 0 "Normal" 1 "Error";
VAL_ 1081 EDS_MotOverTempFault_RWD 0 "Normal" 1 "Error";
VAL_ 1081 EDS_MotTempSenFault_RWD 0 "Normal" 1 "Error";
VAL_ 1081 EDS_EDSOverTempUFault_RWD 0 "Normal" 1 "Error";
VAL_ 1081 EDS_EDSOverTempVFault_RWD 0 "Normal" 1 "Error";
VAL_ 1081 EDS_EDSOverTempWFault_RWD 0 "Normal" 1 "Error";
VAL_ 1081 EDS_EDSOverTempAlarm_RWD 0 "Normal" 1 "Error";
VAL_ 1081 EDS_TCoolantOvHi_RWD 0 "Normal" 1 "Error";
VAL_ 1081 EDS_EDSTempCmpAlarm_RWD 0 "Normal" 1 "Error";
VAL_ 1081 EDS_EDSPhaOvCurentHWFault_RWD 0 "Normal" 1 "Error";
VAL_ 1081 EDS_EDSphaOffCalFault_RWD 0 "Normal" 1 "Error";
VAL_ 1081 EDS_EDSOverIdcLnkAlarm_RWD 0 "Normal" 1 "Error";
VAL_ 1081 EDS_EDSHVOverVoltageAlarm_RWD 0 "Normal" 1 "Error";
VAL_ 1081 EDS_EDSHVOverVoltageFault_RWD 0 "Normal" 1 "Error";
VAL_ 1081 EDS_EDSHVUnderVoltageAlarm_RWD 0 "Normal" 1 "Error";
VAL_ 1081 EDS_EDSHVUnderVoltageFault_RWD 0 "Normal" 1 "Error";
VAL_ 1081 EDS_RunToDischaErr_RWD 0 "Normal" 1 "Error";
VAL_ 1081 EDS_12VOverVoltageAlarm_RWD 0 "Normal" 1 "Error";
VAL_ 1081 EDS_12VUnderVoltageAlarm_RWD 0 "Normal" 1 "Error";
VAL_ 1081 EDS_MotOverAlarm_RWD 0 "Normal" 1 "Error";
VAL_ 1081 EDS_MotOverFault_RWD 0 "Normal" 1 "Error";
VAL_ 1081 EDS_ResolverOffsetAngle_RWD 0 "Normal" 1 "Error";
VAL_ 1082 VCU_AutoP_Feedback 3 "Signal Invalid" 2 "Reserved" 1 "OFF" 0 "ON" ;
VAL_ 1082 VCU_BrakeRegenMode 0 "HIGH" 1 "MID" 2 "LOW" 3 "OFF";
VAL_ 1082 VCU_CreepDisable_stt 0 "Enable" 1 "Disable";
VAL_ 1082 VCU_Charging_Authen_stt 0 "Not authencating" 1 "Authenticating" 2 "Authen success" 3 "Authen failed" 4 "Forbidden vehicle" 5 "reserved" 6 "reserved" 7 "reserved";
VAL_ 1082 VCU_ChgGun_BadConn_stt 0 "No error" 1 "Bad connection";
VAL_ 1082 VCU_ChgPort_Open_stt 0 "Closed" 1 "Opening";
VAL_ 1082 VCU_Regen_available 0 "Not available" 1 "Available" 2 "Regen limit" 3 "Regen faut";
VAL_ 1082 VCU_VehChg_STS 0 "Charging not in progress and gun not plug-in" 1 "Charging in progress" 2 "Charging complete" 3 "Charge fault" 4 "Gun plugged-in, Standby" 5 "Gun plugged-in, Waiting" 6 "Reserved" 7 "Signal Invalid";
VAL_ 1082 VCU_StoppingMode_stt 0 "Off" 1 "CreepMode" 2 "RollMode" 3 "HoldMode" 4 "Reserved" 5 "Reserved" 6 "Reserved" 7 "Reserved";
VAL_ 1082 VCU_ChgGun_Status 0 "Charging gun not plugged" 1 "Locked" 2 "Released" 3 "Error due to plug voltage is higher than 60V." 4 "Error due to electrical failure of lock motor drive pins." 5 "Error due to electrical failure of lock feedback pins" 6 "Error plug lock feedback is received as error from BSW" 7 "Invalid";
VAL_ 1082 VCU_ChgPort_Lock_stt 0 "Locked" 1 "Released";
VAL_ 1082 VCU_Hvbatt_charging_stt 0 "Not charging" 1 "Charging";
VAL_ 1083 EDS_iDcLnkOvCLimFail_FWD 0 "Normal" 1 "Error";
VAL_ 1083 EDS_MotBlockedFault_FWD 0 "Normal" 1 "Error";
VAL_ 1083 EDS_RSLErr_FWD 0 "Normal" 1 "Error";
VAL_ 1083 EDS_MotTrqLimFault_FWD 0 "Normal" 1 "Error";
VAL_ 1083 EDS_VCUChksumFault_FWD 0 "Normal" 1 "Error";
VAL_ 1083 EDS_IGBTFault_FWD 0 "Normal" 1 "Error";
VAL_ 1083 EDS_CANBusoffFault_FWD 0 "Normal" 1 "Error";
VAL_ 1083 EDS_TDrvBoardOvHiWarn_FWD 0 "Normal" 1 "Error";
VAL_ 1083 EDS_TIGBTOvHiFault_FWD 0 "Normal" 1 "Error";
VAL_ 1083 EDS_TIGBTOvHiWarn_FWD 0 "Normal" 1 "Error";
VAL_ 1083 EDS_IOHWABSampFail_FWD 0 "Normal" 1 "Error";
VAL_ 1083 EDS_EDSOpenFault_FWD 0 "Normal" 1 "Error";
VAL_ 1083 EDS_MotorOpenFault_FWD 0 "Normal" 1 "Error";
VAL_ 1083 EDS_EparkSampFail_FWD 0 "Normal" 1 "Error";
VAL_ 1083 EDS_EmacBlkdWarn_FWD 0 "Normal" 1 "Error";
VAL_ 1083 EDS_VerMatchFailureErr_FWD 0 "Normal" 1 "Error";
VAL_ 1083 EDS_DiashCirNoPsblErr_FWD 0 "Normal" 1 "Error";
VAL_ 1083 EDS_OperOutdRngErr_FWD 0 "Normal" 1 "Error";
VAL_ 1083 EDS_PhaseLossFaultErr_FWD 0 "Normal" 1 "Error";
VAL_ 1083 EDS_CPLDFault_FWD 0 "Normal" 1 "Error";
VAL_ 1083 EDS_CPLDFaultBaseSpd_FWD 0 "Normal" 1 "Error";
VAL_ 1083 EDS_IOHWABNen33Fail_FWD 0 "Normal" 1 "Error";
VAL_ 1083 EDS_HvMcuSlightFault_FWD 0 "Normal" 1 "Error";
VAL_ 1083 EDS_HvMcuSevFault_FWD 0 "Normal" 1 "Error";
VAL_ 1083 EDS_EDSPhaSampHWFault_FWD 0 "Normal" 1 "Error";
VAL_ 1083 EDS_IsOvHiErr_FWD 0 "Normal" 1 "Error";
VAL_ 1083 EDS_CanRollingCounterErr_FWD 0 "Normal" 1 "Error";
VAL_ 1083 EDS_CanTimeoutErr_FWD 0 "Normal" 1 "Error";
VAL_ 1083 EDS_CrashFault_FWD 0 "Normal" 1 "Error";
VAL_ 1083 EDS_PCFSlightFault_FWD 0 "Normal" 1 "Error";
VAL_ 1083 EDS_PCFSerFault_FWD 0 "Normal" 1 "Error";
VAL_ 1084 EDS_iDcLnkOvCLimFail_RWD 0 "Normal" 1 "Error";
VAL_ 1084 EDS_MotBlockedFault_RWD 0 "Normal" 1 "Error";
VAL_ 1084 EDS_RSLErr_RWD 0 "Normal" 1 "Error";
VAL_ 1084 EDS_MotTrqLimFault_RWD 0 "Normal" 1 "Error";
VAL_ 1084 EDS_VCUChksumFault_RWD 0 "Normal" 1 "Error";
VAL_ 1084 EDS_IGBTFault_RWD 0 "Normal" 1 "Error";
VAL_ 1084 EDS_CANBusoffFault_RWD 0 "Normal" 1 "Error";
VAL_ 1084 EDS_TDrvBoardOvHiWarn_RWD 0 "Normal" 1 "Error";
VAL_ 1084 EDS_TIGBTOvHiFault_RWD 0 "Normal" 1 "Error";
VAL_ 1084 EDS_TIGBTOvHiWarn_RWD 0 "Normal" 1 "Error";
VAL_ 1084 EDS_IOHWABSampFail_RWD 0 "Normal" 1 "Error";
VAL_ 1084 EDS_EDSOpenFault_RWD 0 "Normal" 1 "Error";
VAL_ 1084 EDS_MotorOpenFault_RWD 0 "Normal" 1 "Error";
VAL_ 1084 EDS_EparkSampFail_RWD 0 "Normal" 1 "Error";
VAL_ 1084 EDS_EmacBlkdWarn_RWD 0 "Normal" 1 "Error";
VAL_ 1084 EDS_VerMatchFailureErr_RWD 0 "Normal" 1 "Error";
VAL_ 1084 EDS_DiashCirNoPsblErr_RWD 0 "Normal" 1 "Error";
VAL_ 1084 EDS_OperOutdRngErr_RWD 0 "Normal" 1 "Error";
VAL_ 1084 EDS_PhaseLossFaultErr_RWD 0 "Normal" 1 "Error";
VAL_ 1084 EDS_CPLDFault_RWD 0 "Normal" 1 "Error";
VAL_ 1084 EDS_CPLDFaultBaseSpd_RWD 0 "Normal" 1 "Error";
VAL_ 1084 EDS_IOHWABNen33Fail_RWD 0 "Normal" 1 "Error";
VAL_ 1084 EDS_HvMcuSlightFault_RWD 0 "Normal" 1 "Error";
VAL_ 1084 EDS_HvMcuSevFault_RWD 0 "Normal" 1 "Error";
VAL_ 1084 EDS_EDSPhaSampHWFault_RWD 0 "Normal" 1 "Error";
VAL_ 1084 EDS_IsOvHiErr_RWD 0 "Normal" 1 "Error";
VAL_ 1084 EDS_CanRollingCounterErr_RWD 0 "Normal" 1 "Error";
VAL_ 1084 EDS_CanTimeoutErr_RWD 0 "Normal" 1 "Error";
VAL_ 1084 EDS_CrashFault_RWD 0 "Normal" 1 "Error";
VAL_ 1084 EDS_PCFSlightFault_RWD 0 "Normal" 1 "Error";
VAL_ 1084 EDS_PCFSerFault_RWD 0 "Normal" 1 "Error";
VAL_ 1093 RS_Sol_L 254 "HW failure solar sensor" 255 "Signal invalid";
VAL_ 1093 RS_Sol_R 254 "HW failure solar sensor" 255 "Signal invalid";
VAL_ 1093 RS_F_HUD_Sensor 0 "No error" 1 "HUD error";
VAL_ 1093 RS_St_LampReq 0 "OFF" 1 "ON" 2 "Reserved" 3 "Invalid";
VAL_ 1093 RS_St_CurrentRain 0 "No rain" 1 "level 1(light rain)" 2 "level 2(moderate rain)" 3 "level 3(heavy rain)" 4 "Reserved" 5 "Reserved" 6 "Reserved" 7 "Signal invalid";
VAL_ 1093 RS_HUD_illuminance 65535 "Invalid";
VAL_ 1095 MHU_Request_CarOFF 0 "Not Request" 1 "Request Car goes to OFF" 2 "Reserved" 3 "Signal Invalid";
VAL_ 1095 MHU_SET_ChildMode 0 "Child Mode OFF" 1 "Child mode ON" 2 "Reserved" 3 "Signal Invalid";
VAL_ 1095 MHU_SET_GameMode 0 "Game mode OFF" 1 "Game mode ON" 2 "Reserved" 3 "Signal Invalid";
VAL_ 1095 MHU_SET_KaraokeMode 0 "Karaoke mode OFF" 1 "Karaoke ON" 2 "Reserved" 3 "Signal Invalid";
VAL_ 1095 MHU_Req_StoppingMode 0 "Off" 1 "CreepMode" 2 "RollMode" 3 "HoldMode" 4 "NoRequest" 5 "Reserved" 6 "Reserved" 7 "Invalid";
VAL_ 1095 MHU_SET_WashMode 0 "Wash mode OFFt" 1 "Wash mode ON" 2 "Reserved" 3 "Signal Invalid";
VAL_ 1095 MHU_SET_StopMode 0 "Creep" 1 "Hold" 2 "Roll" 3 "Signal Invalid";
VAL_ 1095 MHU_AVH_Sw 3 "Reserved" 2 "OFF" 1 "ON" 0 "No Action" ;
VAL_ 1110 OP_WISW_SZL_LIN 0 "No action" 255 "Signal Invalid";
VAL_ 1110 COMM_ERR_SZL_LIN 0 "No error" 1 "Error active";
VAL_ 1110 BCM_Wiper_Front_Status 0 "OFF" 1 "Mist" 2 "IntermittentAuto" 3 "Low Speed" 4 "High Speed" 5 "Reserved" 6 "Reserved" 7 "Invalid";
VAL_ 1110 OP_WIPO_SZL_LIN 0 "Step 1" 1 "Step 2" 2 "Step 3" 4 "Step 4" 7 "Signal Invalid";
VAL_ 1110 OP_COLS_SZL_LIN 0 "No action" 255 "Signal Invalid";
VAL_ 1110 NOD_ERR_SZL_LIN 0 "NO error" 1 "error active" 2 "error Stat change" 3 "Signal invalid";
VAL_ 1110 BCM_Wiper_Rear_Status 0 "OFF" 1 "ON" 2 "Reserved" 3 "Signal Invalid";
